[part 4 of 12: package /E40_Platform_System_SystemPackage/Components]
AUTOSAR XML (schema 4-2-1)
package /E40_Platform_System_SystemPackage/Components  (continued)
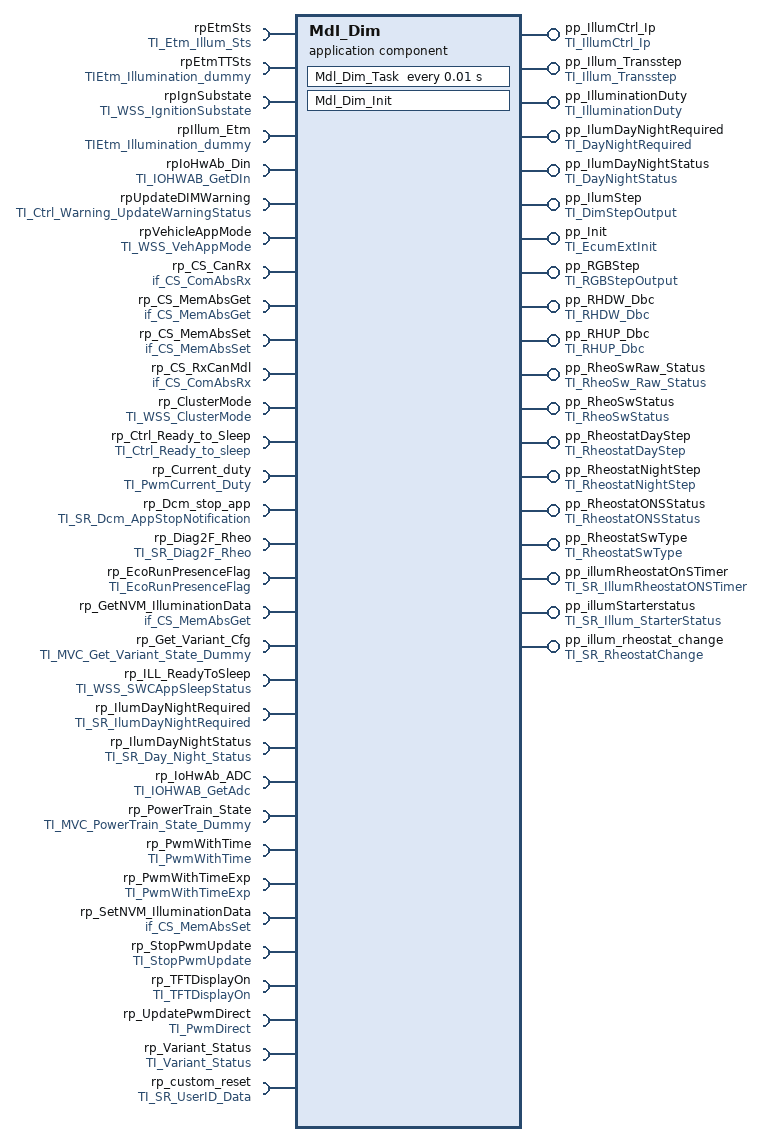
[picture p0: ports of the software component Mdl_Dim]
  application sw component type Mdl_Dim
    19 x provide port:
      pp_IllumCtrl_Ip: nonqueued-sender-com-spec{data-element=IllumCtrl_Ip_Data, init-value=constant-reference=Mdl_DimIllumCtrl_Ip_DataValue0}, provided-interface=TI_IllumCtrl_Ip
      pp_Illum_Transstep: nonqueued-sender-com-spec{data-element=Trans_Stepvlaue, init-value=constant-reference=Mdl_DimTrans_StepvlaueValue0}, provided-interface=TI_Illum_Transstep
      pp_IlluminationDuty: nonqueued-sender-com-spec{data-element=DutyValue, init-value=constant-reference=Mdl_DimDutyValueValue0}, provided-interface=TI_IlluminationDuty
      pp_IlumDayNightRequired: nonqueued-sender-com-spec{data-element=ilumDNRequired, init-value=constant-reference=Mdl_DimilumDNRequiredValue0}, provided-interface=TI_DayNightRequired
      pp_IlumDayNightStatus: nonqueued-sender-com-spec{data-element=illumDNStatus, init-value=constant-reference=Mdl_DimillumDNStatusValue0}, provided-interface=TI_DayNightStatus
      pp_IlumStep: nonqueued-sender-com-spec{data-element=IllumStepValue, init-value=constant-reference=Mdl_DimIllumStepValueValue0}, provided-interface=TI_DimStepOutput
      pp_Init: server-com-spec{operation=TI_EcumExtInit/Init, queue-length=1}, provided-interface=TI_EcumExtInit
      pp_RGBStep: nonqueued-sender-com-spec{data-element=RGBStepValue, init-value=constant-reference=Mdl_DimRGBStepValueValue0}, provided-interface=TI_RGBStepOutput
      pp_RHDW_Dbc: nonqueued-sender-com-spec{data-element=RHDW_Dbc, init-value=constant-reference=Mdl_DimRHDW_DbcValue0}, provided-interface=TI_RHDW_Dbc
      pp_RHUP_Dbc: nonqueued-sender-com-spec{data-element=RHUP_Dbc, init-value=constant-reference=Mdl_DimRHUP_DbcValue0}, provided-interface=TI_RHUP_Dbc
      pp_RheoSwRaw_Status: nonqueued-sender-com-spec{data-element=RawdataStatus, init-value=constant-reference=Mdl_DimRawdataStatusValue0}, provided-interface=TI_RheoSw_Raw_Status
      pp_RheoSwStatus: nonqueued-sender-com-spec{data-element=SwitchStatus, init-value=constant-reference=Mdl_DimSwitchStatusValue0}, provided-interface=TI_RheoSwStatus
      pp_RheostatDayStep: nonqueued-sender-com-spec{data-element=RheostatDayStep, init-value=constant-reference=Mdl_DimRheostatDayStepValue0}, provided-interface=TI_RheostatDayStep
      pp_RheostatNightStep: nonqueued-sender-com-spec{data-element=RheostatNightStep, init-value=constant-reference=Mdl_DimRheostatNightStepValue0}, provided-interface=TI_RheostatNightStep
      pp_RheostatONSStatus: nonqueued-sender-com-spec{data-element=RheostatONSStatus, init-value=constant-reference=Mdl_DimRheostatONSStatusValue0}, provided-interface=TI_RheostatONSStatus
      pp_RheostatSwType: nonqueued-sender-com-spec{data-element=RheostatSwType, init-value=constant-reference=Mdl_DimRheostatSwTypeValue0}, provided-interface=TI_RheostatSwType
      pp_illumRheostatOnSTimer: nonqueued-sender-com-spec{data-element=Rheostat_OnSTime, init-value=constant-reference=Mdl_DimRheostat_OnSTimeValue0}, provided-interface=TI_SR_IllumRheostatONSTimer
      pp_illumStarterstatus: nonqueued-sender-com-spec{data-element=StarterStatus_Out, init-value=constant-reference=Mdl_DimStarterStatus_OutValue0}, provided-interface=TI_SR_Illum_StarterStatus
      pp_illum_rheostat_change: nonqueued-sender-com-spec{data-element=RheoUpdateVal, init-value=constant-reference=Mdl_DimRheoUpdateValValue0}, provided-interface=TI_SR_RheostatChange
    32 x require port:
      rpEtmSts: nonqueued-receiver-com-spec{data-element=Illum_Status, init-value=constant-reference=Mdl_DimIllum_StatusValue0}, required-interface=TI_Etm_Illum_Sts
      rpEtmTTSts: nonqueued-receiver-com-spec{data-element=IllumStatus, init-value=constant-reference=Mdl_DimIllumStatusValue0}, required-interface=TIEtm_Illumination_dummy
      rpIgnSubstate: nonqueued-receiver-com-spec{data-element=IgnitionSubstate, init-value=constant-reference=Mdl_DimIgnitionSubstateValue0}, required-interface=TI_WSS_IgnitionSubstate
      rpIllum_Etm: nonqueued-receiver-com-spec{data-element=IllumStatus, init-value=constant-reference=Mdl_DimIllumStatusValue0}, required-interface=TIEtm_Illumination_dummy
      rpIoHwAb_Din: required-interface=TI_IOHWAB_GetDIn
      rpUpdateDIMWarning: required-interface=TI_Ctrl_Warning_UpdateWarningStatus
      rpVehicleAppMode: nonqueued-receiver-com-spec{data-element=WSSCurrentVehicleState, init-value=constant-reference=Mdl_DimWSSCurrentVehicleStateValue0}, required-interface=TI_WSS_VehAppMode
      rp_CS_CanRx: required-interface=if_CS_ComAbsRx
      rp_CS_MemAbsGet: required-interface=if_CS_MemAbsGet
      rp_CS_MemAbsSet: required-interface=if_CS_MemAbsSet
      rp_CS_RxCanMdl: required-interface=if_CS_ComAbsRx
      rp_ClusterMode: nonqueued-receiver-com-spec{data-element=WSSCurrentClusterMode, init-value=constant-reference=Mdl_DimWSSCurrentClusterModeValue0}, required-interface=TI_WSS_ClusterMode
      rp_Ctrl_Ready_to_Sleep: nonqueued-receiver-com-spec{data-element=Ready_to_Sleep, init-value=constant-reference=Mdl_DimReady_to_SleepValue0}, required-interface=TI_Ctrl_Ready_to_sleep
      rp_Current_duty: required-interface=TI_PwmCurrent_Duty
      rp_Dcm_stop_app: nonqueued-receiver-com-spec{data-element=AppId, init-value=constant-reference=Mdl_DimAppIdValue0}, required-interface=TI_SR_Dcm_AppStopNotification
      rp_Diag2F_Rheo: nonqueued-receiver-com-spec{data-element=Diag_RheoStat, init-value=constant-reference=Mdl_DimDiag_RheoStatValue0}, required-interface=TI_SR_Diag2F_Rheo
      rp_EcoRunPresenceFlag: nonqueued-receiver-com-spec{data-element=EcoRunPresenceFlag, init-value=constant-reference=Mdl_DimEcoRunPresenceFlagValue0}, required-interface=TI_EcoRunPresenceFlag
      rp_GetNVM_IlluminationData: required-interface=if_CS_MemAbsGet
      rp_Get_Variant_Cfg: required-interface=TI_MVC_Get_Variant_State_Dummy
      rp_ILL_ReadyToSleep: required-interface=TI_WSS_SWCAppSleepStatus
      rp_IlumDayNightRequired: nonqueued-receiver-com-spec{data-element=IlumDayNightRequired, init-value=constant-reference=Mdl_DimIlumDayNightRequiredValue0}, required-interface=TI_SR_IlumDayNightRequired
      rp_IlumDayNightStatus: nonqueued-receiver-com-spec{data-element=Day_Night_Status, init-value=constant-reference=Mdl_DimDay_Night_StatusValue0}, required-interface=TI_SR_Day_Night_Status
      rp_IoHwAb_ADC: required-interface=TI_IOHWAB_GetAdc
      rp_PowerTrain_State: nonqueued-receiver-com-spec{data-element=PowerTrain_Flag, init-value=constant-reference=Mdl_DimPowerTrain_FlagValue0}, required-interface=TI_MVC_PowerTrain_State_Dummy
      rp_PwmWithTime: required-interface=TI_PwmWithTime
      rp_PwmWithTimeExp: required-interface=TI_PwmWithTimeExp
      rp_SetNVM_IlluminationData: required-interface=if_CS_MemAbsSet
      rp_StopPwmUpdate: nonqueued-receiver-com-spec{data-element=channel_id, init-value=constant-reference=Mdl_Dimchannel_idValue0}, required-interface=TI_StopPwmUpdate
      rp_TFTDisplayOn: nonqueued-receiver-com-spec{data-element=TFTDisplayOn, init-value=constant-reference=Mdl_DimTFTDisplayOnValue0}, required-interface=TI_TFTDisplayOn
      rp_UpdatePwmDirect: required-interface=TI_PwmDirect
      rp_Variant_Status: required-interface=TI_Variant_Status
      rp_custom_reset: required-interface=TI_SR_UserID_Data
        required-com-specs:
          data-element=CurrentUserID, init-value=constant-reference=Mdl_DimCurrentUserIDValue0
          data-element=CustomizeReset, init-value=constant-reference=Mdl_DimCustomizeResetValue0
          data-element=SettingResetResult, init-value=constant-reference=Mdl_DimSettingResetResultValue0
    behavior IB_Mdl_Dim
      operation invoked event OIE_pp_Init_Mdl_Dim_InitTrigByInit: start-on-event=Mdl_Dim_Init, operation=pp_Init.Init
      timing event TEMdl_Dim_Task: start-on-event=Mdl_Dim_Task, period=0.01
      port-api-options:
        enable-take-address=false, indirect-api=false, port=pp_IllumCtrl_Ip
        enable-take-address=false, indirect-api=false, port=pp_Illum_Transstep
        enable-take-address=false, indirect-api=false, port=pp_IlluminationDuty
        enable-take-address=false, indirect-api=false, port=Mdl_Dim/pp_IlumDayNightRequired
        enable-take-address=false, indirect-api=false, port=Mdl_Dim/pp_IlumDayNightStatus
        enable-take-address=false, indirect-api=false, port=pp_IlumStep
        enable-take-address=false, indirect-api=false, port=Mdl_Dim/pp_Init
        enable-take-address=false, indirect-api=false, port=pp_RGBStep
        enable-take-address=false, indirect-api=false, port=pp_RHDW_Dbc
        enable-take-address=false, indirect-api=false, port=pp_RHUP_Dbc
        enable-take-address=false, indirect-api=false, port=pp_RheoSwRaw_Status
        enable-take-address=false, indirect-api=false, port=pp_RheoSwStatus
        enable-take-address=false, indirect-api=false, port=pp_RheostatDayStep
        enable-take-address=false, indirect-api=false, port=pp_RheostatNightStep
        enable-take-address=false, indirect-api=false, port=pp_RheostatONSStatus
        enable-take-address=false, indirect-api=false, port=pp_RheostatSwType
        enable-take-address=false, indirect-api=false, port=pp_illumRheostatOnSTimer
        enable-take-address=false, indirect-api=false, port=pp_illumStarterstatus
        enable-take-address=false, indirect-api=false, port=pp_illum_rheostat_change
        enable-take-address=false, indirect-api=false, port=Mdl_Dim/rpEtmSts
        enable-take-address=false, indirect-api=false, port=rpEtmTTSts
        enable-take-address=false, indirect-api=false, port=Mdl_Dim/rpIgnSubstate
        enable-take-address=false, indirect-api=false, port=Mdl_Dim/rpIllum_Etm
        enable-take-address=false, indirect-api=false, port=Mdl_Dim/rpIoHwAb_Din
        enable-take-address=false, indirect-api=false, port=rpUpdateDIMWarning
        enable-take-address=false, indirect-api=false, port=Mdl_Dim/rpVehicleAppMode
        enable-take-address=false, indirect-api=false, port=Mdl_Dim/rp_CS_CanRx
        enable-take-address=false, indirect-api=false, port=Mdl_Dim/rp_CS_MemAbsGet
        enable-take-address=false, indirect-api=false, port=Mdl_Dim/rp_CS_MemAbsSet
        enable-take-address=false, indirect-api=false, port=Mdl_Dim/rp_CS_RxCanMdl
        enable-take-address=false, indirect-api=false, port=Mdl_Dim/rp_ClusterMode
        enable-take-address=false, indirect-api=false, port=rp_Ctrl_Ready_to_Sleep
        enable-take-address=false, indirect-api=false, port=rp_Current_duty
        enable-take-address=false, indirect-api=false, port=rp_Dcm_stop_app
        enable-take-address=false, indirect-api=false, port=rp_Diag2F_Rheo
        enable-take-address=false, indirect-api=false, port=rp_EcoRunPresenceFlag
        enable-take-address=false, indirect-api=false, port=rp_GetNVM_IlluminationData
        enable-take-address=false, indirect-api=false, port=Mdl_Dim/rp_Get_Variant_Cfg
        enable-take-address=false, indirect-api=false, port=Mdl_Dim/rp_ILL_ReadyToSleep
        enable-take-address=false, indirect-api=false, port=rp_IlumDayNightRequired
        enable-take-address=false, indirect-api=false, port=Mdl_Dim/rp_IlumDayNightStatus
        enable-take-address=false, indirect-api=false, port=Mdl_Dim/rp_IoHwAb_ADC
        enable-take-address=false, indirect-api=false, port=Mdl_Dim/rp_PowerTrain_State
        enable-take-address=false, indirect-api=false, port=rp_PwmWithTime
        enable-take-address=false, indirect-api=false, port=rp_PwmWithTimeExp
        enable-take-address=false, indirect-api=false, port=rp_SetNVM_IlluminationData
        enable-take-address=false, indirect-api=false, port=rp_StopPwmUpdate
        enable-take-address=false, indirect-api=false, port=Mdl_Dim/rp_TFTDisplayOn
        enable-take-address=false, indirect-api=false, port=rp_UpdatePwmDirect
        enable-take-address=false, indirect-api=false, port=Mdl_Dim/rp_Variant_Status
        enable-take-address=false, indirect-api=false, port=rp_custom_reset
      runnable Mdl_Dim_Init: can-be-invoked-concurrently=true
      runnable Mdl_Dim_Task: can-be-invoked-concurrently=true
        data-receive-point-by-arguments:
          18 x access:
            DRA_rpEtmSts_Illum_Status: accessed-variable=rpEtmSts.Illum_Status
            DRA_rpEtmTTSts_IllumStatus: accessed-variable=rpEtmTTSts.IllumStatus
            DRA_rpIgnSubstate_IgnitionSubstate: accessed-variable=rpIgnSubstate.IgnitionSubstate
            DRA_rpIllum_Etm_IllumStatus: accessed-variable=rpIllum_Etm.IllumStatus
            DRA_rpVehicleAppMode_WSSCurrentVehicleState: accessed-variable=rpVehicleAppMode.WSSCurrentVehicleState
            DRA_rp_ClusterMode_WSSCurrentClusterMode: accessed-variable=rp_ClusterMode.WSSCurrentClusterMode
            DRA_rp_Ctrl_Ready_to_Sleep_Ready_to_Sleep: accessed-variable=rp_Ctrl_Ready_to_Sleep.Ready_to_Sleep
            DRA_rp_Dcm_stop_app_AppId: accessed-variable=rp_Dcm_stop_app.AppId
            DRA_rp_Diag2F_Rheo_Diag_RheoStat: accessed-variable=rp_Diag2F_Rheo.Diag_RheoStat
            DRA_rp_EcoRunPresenceFlag_EcoRunPresenceFlag: accessed-variable=rp_EcoRunPresenceFlag.EcoRunPresenceFlag
            DRA_rp_IlumDayNightRequired_IlumDayNightRequired: accessed-variable=rp_IlumDayNightRequired.IlumDayNightRequired
            DRA_rp_IlumDayNightStatus_Day_Night_Status: accessed-variable=rp_IlumDayNightStatus.Day_Night_Status
            DRA_rp_PowerTrain_State_PowerTrain_Flag: accessed-variable=rp_PowerTrain_State.PowerTrain_Flag
            DRA_rp_StopPwmUpdate_channel_id: accessed-variable=rp_StopPwmUpdate.channel_id
            DRA_rp_TFTDisplayOn_TFTDisplayOn: accessed-variable=rp_TFTDisplayOn.TFTDisplayOn
            DRA_rp_custom_reset_CurrentUserID: accessed-variable=rp_custom_reset.CurrentUserID
            DRA_rp_custom_reset_CustomizeReset: accessed-variable=rp_custom_reset.CustomizeReset
            DRA_rp_custom_reset_SettingResetResult: accessed-variable=rp_custom_reset.SettingResetResult
        data-send-points:
          18 x access:
            DWA_pp_IllumCtrl_Ip_IllumCtrl_Ip_Data: accessed-variable=pp_IllumCtrl_Ip.IllumCtrl_Ip_Data
            DWA_pp_Illum_Transstep_Trans_Stepvlaue: accessed-variable=pp_Illum_Transstep.Trans_Stepvlaue
            DWA_pp_IlluminationDuty_DutyValue: accessed-variable=pp_IlluminationDuty.DutyValue
            DWA_pp_IlumDayNightRequired_ilumDNRequired: accessed-variable=pp_IlumDayNightRequired.ilumDNRequired
            DWA_pp_IlumDayNightStatus_illumDNStatus: accessed-variable=pp_IlumDayNightStatus.illumDNStatus
            DWA_pp_IlumStep_IllumStepValue: accessed-variable=pp_IlumStep.IllumStepValue
            DWA_pp_RGBStep_RGBStepValue: accessed-variable=pp_RGBStep.RGBStepValue
            DWA_pp_RHDW_Dbc_RHDW_Dbc: accessed-variable=pp_RHDW_Dbc.RHDW_Dbc
            DWA_pp_RHUP_Dbc_RHUP_Dbc: accessed-variable=pp_RHUP_Dbc.RHUP_Dbc
            DWA_pp_RheoSwRaw_Status_RawdataStatus: accessed-variable=pp_RheoSwRaw_Status.RawdataStatus
            DWA_pp_RheoSwStatus_SwitchStatus: accessed-variable=pp_RheoSwStatus.SwitchStatus
            DWA_pp_RheostatDayStep_RheostatDayStep: accessed-variable=pp_RheostatDayStep.RheostatDayStep
            DWA_pp_RheostatNightStep_RheostatNightStep: accessed-variable=pp_RheostatNightStep.RheostatNightStep
            DWA_pp_RheostatONSStatus_RheostatONSStatus: accessed-variable=pp_RheostatONSStatus.RheostatONSStatus
            DWA_pp_RheostatSwType_RheostatSwType: accessed-variable=pp_RheostatSwType.RheostatSwType
            DWA_pp_illumRheostatOnSTimer_Rheostat_OnSTime: accessed-variable=pp_illumRheostatOnSTimer.Rheostat_OnSTime
            DWA_pp_illumStarterstatus_StarterStatus_Out: accessed-variable=pp_illumStarterstatus.StarterStatus_Out
            DWA_pp_illum_rheostat_change_RheoUpdateVal: accessed-variable=pp_illum_rheostat_change.RheoUpdateVal
        409 x sync call, all with timeout=0.0:
          OA_rpIoHwAb_Din_GetAsyncRawInput: operation=rpIoHwAb_Din.GetAsyncRawInput
          OA_rpIoHwAb_Din_GetProcessedInput: operation=rpIoHwAb_Din.GetProcessedInput
          OA_rpIoHwAb_Din_GetSyncRawInput: operation=rpIoHwAb_Din.GetSyncRawInput
          OA_rpIoHwAb_Din_GetInputGroup: operation=rpIoHwAb_Din.GetInputGroup
          OA_rpUpdateDIMWarning_UpdateWarningStatus: operation=rpUpdateDIMWarning.UpdateWarningStatus
          OA_rp_CS_CanRx_RxCan_GetSignalValueU8Arr: operation=rp_CS_CanRx.RxCan_GetSignalValueU8Arr
          OA_rp_CS_CanRx_RxCan_SetSignalInitValue: operation=rp_CS_CanRx.RxCan_SetSignalInitValue
          OA_rp_CS_CanRx_RxCan_SetSignalInitValueU8Arr: operation=rp_CS_CanRx.RxCan_SetSignalInitValueU8Arr
          OA_rp_CS_CanRx_RxCan_SignalInvalidProcessingControl: operation=rp_CS_CanRx.RxCan_SignalInvalidProcessingControl
          OA_rp_CS_CanRx_RxCan_SignalMissingProcessingControl: operation=rp_CS_CanRx.RxCan_SignalMissingProcessingControl
          OA_rp_CS_CanRx_RxCan_SignalNRProcessingControl: operation=rp_CS_CanRx.RxCan_SignalNRProcessingControl
          OA_rp_CS_CanRx_RxCan_SignalGetJustRcvdStatus: operation=rp_CS_CanRx.RxCan_SignalGetJustRcvdStatus
          OA_rp_CS_CanRx_RxCan_SignalClearJustRcvdStatus: operation=rp_CS_CanRx.RxCan_SignalClearJustRcvdStatus
          OA_rp_CS_CanRx_RxCan_GetSignalValue: operation=rp_CS_CanRx.RxCan_GetSignalValue
          OA_rp_CS_MemAbsGet_Get_BsShare_SwUpdReflash_Element: operation=rp_CS_MemAbsGet.Get_BsShare_SwUpdReflash_Element
          OA_rp_CS_MemAbsGet_Get_BsShare_SwUpdFotaMode_Element: operation=rp_CS_MemAbsGet.Get_BsShare_SwUpdFotaMode_Element
          OA_rp_CS_MemAbsGet_Get_BsShare_SwUpdFotaFinPrint_Element: operation=rp_CS_MemAbsGet.Get_BsShare_SwUpdFotaFinPrint_Element
          OA_rp_CS_MemAbsGet_Get_BsShare_SwUpdFotaStatus_Element: operation=rp_CS_MemAbsGet.Get_BsShare_SwUpdFotaStatus_Element
          OA_rp_CS_MemAbsGet_Get_BsShare_SwUpdFotadecrypt_Element: operation=rp_CS_MemAbsGet.Get_BsShare_SwUpdFotadecrypt_Element
          OA_rp_CS_MemAbsGet_Get_BsShare_EcuPartNumber_Element: operation=rp_CS_MemAbsGet.Get_BsShare_EcuPartNumber_Element
          OA_rp_CS_MemAbsGet_Get_BsShare_VisteonPartNumber: operation=rp_CS_MemAbsGet.Get_BsShare_VisteonPartNumber
          OA_rp_CS_MemAbsGet_Get_BsShare_VisteonPCBPartNumber: operation=rp_CS_MemAbsGet.Get_BsShare_VisteonPCBPartNumber
          OA_rp_CS_MemAbsGet_Get_BsShare_ProductSerialNumber: operation=rp_CS_MemAbsGet.Get_BsShare_ProductSerialNumber
          OA_rp_CS_MemAbsGet_Get_BsShare_PCBSerialNumber: operation=rp_CS_MemAbsGet.Get_BsShare_PCBSerialNumber
          OA_rp_CS_MemAbsGet_Get_BsShare_SMTManufacturingDate: operation=rp_CS_MemAbsGet.Get_BsShare_SMTManufacturingDate
          OA_rp_CS_MemAbsGet_Get_BsShare_AssemblyManufacturingDate: operation=rp_CS_MemAbsGet.Get_BsShare_AssemblyManufacturingDate
          OA_rp_CS_MemAbsGet_Get_BsShare_SMTPlantNumber: operation=rp_CS_MemAbsGet.Get_BsShare_SMTPlantNumber
          OA_rp_CS_MemAbsGet_Get_BsShare_AssemblyPlantNumber: operation=rp_CS_MemAbsGet.Get_BsShare_AssemblyPlantNumber
          OA_rp_CS_MemAbsGet_Get_BsShare_HWModification: operation=rp_CS_MemAbsGet.Get_BsShare_HWModification
          OA_rp_CS_MemAbsGet_Get_BsShare_VisMeet_Element: operation=rp_CS_MemAbsGet.Get_BsShare_VisMeet_Element
          OA_rp_CS_MemAbsGet_Get_BsShare_VisMeet_EOLEntry_Element: operation=rp_CS_MemAbsGet.Get_BsShare_VisMeet_EOLEntry_Element
          OA_rp_CS_MemAbsGet_Get_BsShare_VehicleConfig_Element: operation=rp_CS_MemAbsGet.Get_BsShare_VehicleConfig_Element
          OA_rp_CS_MemAbsGet_Get_BsConst_SpeedoGauge_Element: operation=rp_CS_MemAbsGet.Get_BsConst_SpeedoGauge_Element
          OA_rp_CS_MemAbsGet_Get_BsConst_TachoGauge_Element: operation=rp_CS_MemAbsGet.Get_BsConst_TachoGauge_Element
          OA_rp_CS_MemAbsGet_Get_BsConst_FuelGauge_Element: operation=rp_CS_MemAbsGet.Get_BsConst_FuelGauge_Element
          OA_rp_CS_MemAbsGet_Get_BsConst_TempGauge_Element: operation=rp_CS_MemAbsGet.Get_BsConst_TempGauge_Element
          OA_rp_CS_MemAbsGet_Get_BsConst_PowerGauge_Element: operation=rp_CS_MemAbsGet.Get_BsConst_PowerGauge_Element
          OA_rp_CS_MemAbsGet_Get_BsConst_OilGauge_Element: operation=rp_CS_MemAbsGet.Get_BsConst_OilGauge_Element
          OA_rp_CS_MemAbsGet_Get_BsConst_TripComputer_Element: operation=rp_CS_MemAbsGet.Get_BsConst_TripComputer_Element
          OA_rp_CS_MemAbsGet_Get_BsConst_Compensation_Line_Slope_m: operation=rp_CS_MemAbsGet.Get_BsConst_Compensation_Line_Slope_m
          OA_rp_CS_MemAbsGet_Get_BsConst_Compensation_Line_Shift_b: operation=rp_CS_MemAbsGet.Get_BsConst_Compensation_Line_Shift_b
          OA_rp_CS_MemAbsGet_Get_BsConst_Lookup_Curve_HotSpot_Coef_X: operation=rp_CS_MemAbsGet.Get_BsConst_Lookup_Curve_HotSpot_Coef_X
          OA_rp_CS_MemAbsGet_Get_BsConst_Lookup_Curve_HotSpot_Coef_Y: operation=rp_CS_MemAbsGet.Get_BsConst_Lookup_Curve_HotSpot_Coef_Y
          OA_rp_CS_MemAbsGet_Get_BsConst_Temp_Threshold_Hysteresis_Derating: operation=rp_CS_MemAbsGet.Get_BsConst_Temp_Threshold_Hysteresis_Derating
          OA_rp_CS_MemAbsGet_Get_BsConst_Derating_Backlight_Disable: operation=rp_CS_MemAbsGet.Get_BsConst_Derating_Backlight_Disable
          OA_rp_CS_MemAbsGet_Get_BsConst_Temperature_Sensor_Conv: operation=rp_CS_MemAbsGet.Get_BsConst_Temperature_Sensor_Conv
          OA_rp_CS_MemAbsGet_Get_BsConst_PCB_Temperature_Sensor_Conv: operation=rp_CS_MemAbsGet.Get_BsConst_PCB_Temperature_Sensor_Conv
          OA_rp_CS_MemAbsGet_Get_BsConst_Display_Illum_Max_Level: operation=rp_CS_MemAbsGet.Get_BsConst_Display_Illum_Max_Level
          OA_rp_CS_MemAbsGet_Get_BsConst_PWM_boost_bypass_duty: operation=rp_CS_MemAbsGet.Get_BsConst_PWM_boost_bypass_duty
          OA_rp_CS_MemAbsGet_Get_BsConst_BsConst_Illumination_ReservedByte: operation=rp_CS_MemAbsGet.Get_BsConst_BsConst_Illumination_ReservedByte
          OA_rp_CS_MemAbsGet_Get_BsConst_Compensation_Line_Slope_m_SafeCopy1: operation=rp_CS_MemAbsGet.Get_BsConst_Compensation_Line_Slope_m_SafeCopy1
          OA_rp_CS_MemAbsGet_Get_BsConst_Compensation_Line_Shift_b_SafeCopy1: operation=rp_CS_MemAbsGet.Get_BsConst_Compensation_Line_Shift_b_SafeCopy1
          OA_rp_CS_MemAbsGet_Get_BsConst_Lookup_Curve_HotSpot_Coef_X_SafeCopy1: operation=rp_CS_MemAbsGet.Get_BsConst_Lookup_Curve_HotSpot_Coef_X_SafeCopy1
          OA_rp_CS_MemAbsGet_Get_BsConst_Lookup_Curve_HotSpot_Coef_Y_SafeCopy1: operation=rp_CS_MemAbsGet.Get_BsConst_Lookup_Curve_HotSpot_Coef_Y_SafeCopy1
          OA_rp_CS_MemAbsGet_Get_BsConst_Temp_Threshold_Hysteresis_Derating_SafeCopy1: operation=rp_CS_MemAbsGet.Get_BsConst_Temp_Threshold_Hysteresis_Derating_SafeCopy1
          OA_rp_CS_MemAbsGet_Get_BsConst_Derating_Backlight_Disable_SafeCopy1: operation=rp_CS_MemAbsGet.Get_BsConst_Derating_Backlight_Disable_SafeCopy1
          OA_rp_CS_MemAbsGet_Get_BsConst_Temperature_Sensor_Conv_SafeCopy1: operation=rp_CS_MemAbsGet.Get_BsConst_Temperature_Sensor_Conv_SafeCopy1
          OA_rp_CS_MemAbsGet_Get_BsConst_PCB_Temperature_Sensor_Conv_SafeCopy1: operation=rp_CS_MemAbsGet.Get_BsConst_PCB_Temperature_Sensor_Conv_SafeCopy1
          OA_rp_CS_MemAbsGet_Get_BsConst_Display_Illum_Max_Level_SafeCopy1: operation=rp_CS_MemAbsGet.Get_BsConst_Display_Illum_Max_Level_SafeCopy1
          OA_rp_CS_MemAbsGet_Get_BsConst_PWM_boost_bypass_duty_SafeCopy1: operation=rp_CS_MemAbsGet.Get_BsConst_PWM_boost_bypass_duty_SafeCopy1
          OA_rp_CS_MemAbsGet_Get_BsConst_BsConst_Illumination_ReservedByte_SafeCopy1: operation=rp_CS_MemAbsGet.Get_BsConst_BsConst_Illumination_ReservedByte_SafeCopy1
          OA_rp_CS_MemAbsGet_Get_BsConst_Compensation_Line_Slope_m_SafeCopy2: operation=rp_CS_MemAbsGet.Get_BsConst_Compensation_Line_Slope_m_SafeCopy2
          OA_rp_CS_MemAbsGet_Get_BsConst_Compensation_Line_Shift_b_SafeCopy2: operation=rp_CS_MemAbsGet.Get_BsConst_Compensation_Line_Shift_b_SafeCopy2
          OA_rp_CS_MemAbsGet_Get_BsConst_Lookup_Curve_HotSpot_Coef_X_SafeCopy2: operation=rp_CS_MemAbsGet.Get_BsConst_Lookup_Curve_HotSpot_Coef_X_SafeCopy2
          OA_rp_CS_MemAbsGet_Get_BsConst_Lookup_Curve_HotSpot_Coef_Y_SafeCopy2: operation=rp_CS_MemAbsGet.Get_BsConst_Lookup_Curve_HotSpot_Coef_Y_SafeCopy2
          OA_rp_CS_MemAbsGet_Get_BsConst_Temp_Threshold_Hysteresis_Derating_SafeCopy2: operation=rp_CS_MemAbsGet.Get_BsConst_Temp_Threshold_Hysteresis_Derating_SafeCopy2
          OA_rp_CS_MemAbsGet_Get_BsConst_Derating_Backlight_Disable_SafeCopy2: operation=rp_CS_MemAbsGet.Get_BsConst_Derating_Backlight_Disable_SafeCopy2
          OA_rp_CS_MemAbsGet_Get_BsConst_Temperature_Sensor_Conv_SafeCopy2: operation=rp_CS_MemAbsGet.Get_BsConst_Temperature_Sensor_Conv_SafeCopy2
          OA_rp_CS_MemAbsGet_Get_BsConst_PCB_Temperature_Sensor_Conv_SafeCopy2: operation=rp_CS_MemAbsGet.Get_BsConst_PCB_Temperature_Sensor_Conv_SafeCopy2
          OA_rp_CS_MemAbsGet_Get_BsConst_Display_Illum_Max_Level_SafeCopy2: operation=rp_CS_MemAbsGet.Get_BsConst_Display_Illum_Max_Level_SafeCopy2
          OA_rp_CS_MemAbsGet_Get_BsConst_PWM_boost_bypass_duty_SafeCopy2: operation=rp_CS_MemAbsGet.Get_BsConst_PWM_boost_bypass_duty_SafeCopy2
          OA_rp_CS_MemAbsGet_Get_BsConst_BsConst_Illumination_ReservedByte_SafeCopy2: operation=rp_CS_MemAbsGet.Get_BsConst_BsConst_Illumination_ReservedByte_SafeCopy2
          OA_rp_CS_MemAbsGet_Get_BsConst_Audio_Element: operation=rp_CS_MemAbsGet.Get_BsConst_Audio_Element
          OA_rp_CS_MemAbsGet_Get_BsConst_Warning_Element: operation=rp_CS_MemAbsGet.Get_BsConst_Warning_Element
          OA_rp_CS_MemAbsGet_Get_BsConst_RealTimeClock_Element: operation=rp_CS_MemAbsGet.Get_BsConst_RealTimeClock_Element
          OA_rp_CS_MemAbsGet_Get_BsConst_Communication_Element: operation=rp_CS_MemAbsGet.Get_BsConst_Communication_Element
          OA_rp_CS_MemAbsGet_Get_BsConst_Power_Element: operation=rp_CS_MemAbsGet.Get_BsConst_Power_Element
          OA_rp_CS_MemAbsGet_Get_BsConst_ServiceReminder_Element: operation=rp_CS_MemAbsGet.Get_BsConst_ServiceReminder_Element
          OA_rp_CS_MemAbsGet_Get_BsConst_EngOffTimer_Element: operation=rp_CS_MemAbsGet.Get_BsConst_EngOffTimer_Element
          OA_rp_CS_MemAbsGet_Get_BsCys_Certicificate_Element: operation=rp_CS_MemAbsGet.Get_BsCys_Certicificate_Element
          OA_rp_CS_MemAbsGet_Get_RefCys_Certicificate_Element: operation=rp_CS_MemAbsGet.Get_RefCys_Certicificate_Element
          OA_rp_CS_MemAbsGet_Get_RefCys_Certicificate1_Element: operation=rp_CS_MemAbsGet.Get_RefCys_Certicificate1_Element
          OA_rp_CS_MemAbsGet_Get_BsRt_Odometer_Element: operation=rp_CS_MemAbsGet.Get_BsRt_Odometer_Element
          OA_rp_CS_MemAbsGet_Get_BsRt_SpeedoGauge_Element: operation=rp_CS_MemAbsGet.Get_BsRt_SpeedoGauge_Element
          OA_rp_CS_MemAbsGet_Get_BsRt_TachoGauge_Element: operation=rp_CS_MemAbsGet.Get_BsRt_TachoGauge_Element
          OA_rp_CS_MemAbsGet_Get_BsRt_FuelGauge_Element: operation=rp_CS_MemAbsGet.Get_BsRt_FuelGauge_Element
          OA_rp_CS_MemAbsGet_Get_BsRt_TempGauge_Element: operation=rp_CS_MemAbsGet.Get_BsRt_TempGauge_Element
          OA_rp_CS_MemAbsGet_Get_BsRt_PowerGauge_Element: operation=rp_CS_MemAbsGet.Get_BsRt_PowerGauge_Element
          OA_rp_CS_MemAbsGet_Get_BsRt_OilGauge_Element: operation=rp_CS_MemAbsGet.Get_BsRt_OilGauge_Element
          OA_rp_CS_MemAbsGet_Get_BsRt_TripComputer_Element: operation=rp_CS_MemAbsGet.Get_BsRt_TripComputer_Element
          OA_rp_CS_MemAbsGet_Get_BsRt_Warning_Element: operation=rp_CS_MemAbsGet.Get_BsRt_Warning_Element
          OA_rp_CS_MemAbsGet_Get_BsRt_RealTimeClock_Element: operation=rp_CS_MemAbsGet.Get_BsRt_RealTimeClock_Element
          OA_rp_CS_MemAbsGet_Get_BsRt_Personalization_Element: operation=rp_CS_MemAbsGet.Get_BsRt_Personalization_Element
          OA_rp_CS_MemAbsGet_Get_BsRt_Illumination_Element: operation=rp_CS_MemAbsGet.Get_BsRt_Illumination_Element
          OA_rp_CS_MemAbsGet_Get_BsRt_CusDlt_Element: operation=rp_CS_MemAbsGet.Get_BsRt_CusDlt_Element
          OA_rp_CS_MemAbsGet_Get_BsReten_Odometer_Element: operation=rp_CS_MemAbsGet.Get_BsReten_Odometer_Element
          OA_rp_CS_MemAbsGet_Get_BsReten_Gauges_Element: operation=rp_CS_MemAbsGet.Get_BsReten_Gauges_Element
          OA_rp_CS_MemAbsGet_Get_BsReten_Tripcomputer_Element: operation=rp_CS_MemAbsGet.Get_BsReten_Tripcomputer_Element
          OA_rp_CS_MemAbsGet_Get_BsReten_Illumination_Element: operation=rp_CS_MemAbsGet.Get_BsReten_Illumination_Element
          OA_rp_CS_MemAbsGet_Get_BsReten_Audio_Element: operation=rp_CS_MemAbsGet.Get_BsReten_Audio_Element
          OA_rp_CS_MemAbsGet_Get_BsReten_Warning_Element: operation=rp_CS_MemAbsGet.Get_BsReten_Warning_Element
          OA_rp_CS_MemAbsGet_Get_BsReten_RealTimeClock_Element: operation=rp_CS_MemAbsGet.Get_BsReten_RealTimeClock_Element
          OA_rp_CS_MemAbsGet_Get_BsReten_Communication_Element: operation=rp_CS_MemAbsGet.Get_BsReten_Communication_Element
          OA_rp_CS_MemAbsGet_Get_BsReten_Personalization_Element: operation=rp_CS_MemAbsGet.Get_BsReten_Personalization_Element
          OA_rp_CS_MemAbsGet_Get_BsReten_Power_Element: operation=rp_CS_MemAbsGet.Get_BsReten_Power_Element
          OA_rp_CS_MemAbsGet_Get_BsReten_Display_Element: operation=rp_CS_MemAbsGet.Get_BsReten_Display_Element
          OA_rp_CS_MemAbsGet_Get_BsDiag_ErrorRecord_Element: operation=rp_CS_MemAbsGet.Get_BsDiag_ErrorRecord_Element
          OA_rp_CS_MemAbsGet_Get_BsDiag_Dtc_Element: operation=rp_CS_MemAbsGet.Get_BsDiag_Dtc_Element
          OA_rp_CS_MemAbsSet_Set_BsShare_SwUpdReflash_Element: operation=rp_CS_MemAbsSet.Set_BsShare_SwUpdReflash_Element
          OA_rp_CS_MemAbsSet_Set_BsShare_SwUpdFotaMode_Element: operation=rp_CS_MemAbsSet.Set_BsShare_SwUpdFotaMode_Element
          OA_rp_CS_MemAbsSet_Set_BsShare_SwUpdFotaFinPrint_Element: operation=rp_CS_MemAbsSet.Set_BsShare_SwUpdFotaFinPrint_Element
          OA_rp_CS_MemAbsSet_Set_BsShare_SwUpdFotaStatus_Element: operation=rp_CS_MemAbsSet.Set_BsShare_SwUpdFotaStatus_Element
          OA_rp_CS_MemAbsSet_Set_BsShare_SwUpdFotadecrypt_Element: operation=rp_CS_MemAbsSet.Set_BsShare_SwUpdFotadecrypt_Element
          OA_rp_CS_MemAbsSet_Set_BsShare_EcuPartNumber_Element: operation=rp_CS_MemAbsSet.Set_BsShare_EcuPartNumber_Element
          OA_rp_CS_MemAbsSet_Set_BsShare_VisteonPartNumber: operation=rp_CS_MemAbsSet.Set_BsShare_VisteonPartNumber
          OA_rp_CS_MemAbsSet_Set_BsShare_VisteonPCBPartNumber: operation=rp_CS_MemAbsSet.Set_BsShare_VisteonPCBPartNumber
          OA_rp_CS_MemAbsSet_Set_BsShare_ProductSerialNumber: operation=rp_CS_MemAbsSet.Set_BsShare_ProductSerialNumber
          OA_rp_CS_MemAbsSet_Set_BsShare_PCBSerialNumber: operation=rp_CS_MemAbsSet.Set_BsShare_PCBSerialNumber
          OA_rp_CS_MemAbsSet_Set_BsShare_SMTManufacturingDate: operation=rp_CS_MemAbsSet.Set_BsShare_SMTManufacturingDate
          OA_rp_CS_MemAbsSet_Set_BsShare_AssemblyManufacturingDate: operation=rp_CS_MemAbsSet.Set_BsShare_AssemblyManufacturingDate
          OA_rp_CS_MemAbsSet_Set_BsShare_SMTPlantNumber: operation=rp_CS_MemAbsSet.Set_BsShare_SMTPlantNumber
          OA_rp_CS_MemAbsSet_Set_BsShare_AssemblyPlantNumber: operation=rp_CS_MemAbsSet.Set_BsShare_AssemblyPlantNumber
          OA_rp_CS_MemAbsSet_Set_BsShare_HWModification: operation=rp_CS_MemAbsSet.Set_BsShare_HWModification
          OA_rp_CS_MemAbsSet_Set_BsShare_VisMeet_Element: operation=rp_CS_MemAbsSet.Set_BsShare_VisMeet_Element
          OA_rp_CS_MemAbsSet_Set_BsShare_VisMeet_EOLEntry_Element: operation=rp_CS_MemAbsSet.Set_BsShare_VisMeet_EOLEntry_Element
          OA_rp_CS_MemAbsSet_Set_BsShare_VehicleConfig_Element: operation=rp_CS_MemAbsSet.Set_BsShare_VehicleConfig_Element
          OA_rp_CS_MemAbsSet_Set_BsConst_SpeedoGauge_Element: operation=rp_CS_MemAbsSet.Set_BsConst_SpeedoGauge_Element
          OA_rp_CS_MemAbsSet_Set_BsConst_TachoGauge_Element: operation=rp_CS_MemAbsSet.Set_BsConst_TachoGauge_Element
          OA_rp_CS_MemAbsSet_Set_BsConst_FuelGauge_Element: operation=rp_CS_MemAbsSet.Set_BsConst_FuelGauge_Element
          OA_rp_CS_MemAbsSet_Set_BsConst_TempGauge_Element: operation=rp_CS_MemAbsSet.Set_BsConst_TempGauge_Element
          OA_rp_CS_MemAbsSet_Set_BsConst_PowerGauge_Element: operation=rp_CS_MemAbsSet.Set_BsConst_PowerGauge_Element
          OA_rp_CS_MemAbsSet_Set_BsConst_OilGauge_Element: operation=rp_CS_MemAbsSet.Set_BsConst_OilGauge_Element
          OA_rp_CS_MemAbsSet_Set_BsConst_TripComputer_Element: operation=rp_CS_MemAbsSet.Set_BsConst_TripComputer_Element
          OA_rp_CS_MemAbsSet_Set_BsConst_Compensation_Line_Slope_m: operation=rp_CS_MemAbsSet.Set_BsConst_Compensation_Line_Slope_m
          OA_rp_CS_MemAbsSet_Set_BsConst_Compensation_Line_Shift_b: operation=rp_CS_MemAbsSet.Set_BsConst_Compensation_Line_Shift_b
          OA_rp_CS_MemAbsSet_Set_BsConst_Lookup_Curve_HotSpot_Coef_X: operation=rp_CS_MemAbsSet.Set_BsConst_Lookup_Curve_HotSpot_Coef_X
          OA_rp_CS_MemAbsSet_Set_BsConst_Lookup_Curve_HotSpot_Coef_Y: operation=rp_CS_MemAbsSet.Set_BsConst_Lookup_Curve_HotSpot_Coef_Y
          OA_rp_CS_MemAbsSet_Set_BsConst_Temp_Threshold_Hysteresis_Derating: operation=rp_CS_MemAbsSet.Set_BsConst_Temp_Threshold_Hysteresis_Derating
          OA_rp_CS_MemAbsSet_Set_BsConst_Derating_Backlight_Disable: operation=rp_CS_MemAbsSet.Set_BsConst_Derating_Backlight_Disable
          OA_rp_CS_MemAbsSet_Set_BsConst_Temperature_Sensor_Conv: operation=rp_CS_MemAbsSet.Set_BsConst_Temperature_Sensor_Conv
          OA_rp_CS_MemAbsSet_Set_BsConst_PCB_Temperature_Sensor_Conv: operation=rp_CS_MemAbsSet.Set_BsConst_PCB_Temperature_Sensor_Conv
          OA_rp_CS_MemAbsSet_Set_BsConst_Display_Illum_Max_Level: operation=rp_CS_MemAbsSet.Set_BsConst_Display_Illum_Max_Level
          OA_rp_CS_MemAbsSet_Set_BsConst_PWM_boost_bypass_duty: operation=rp_CS_MemAbsSet.Set_BsConst_PWM_boost_bypass_duty
          OA_rp_CS_MemAbsSet_Set_BsConst_BsConst_Illumination_ReservedByte: operation=rp_CS_MemAbsSet.Set_BsConst_BsConst_Illumination_ReservedByte
          OA_rp_CS_MemAbsSet_Set_BsConst_Compensation_Line_Slope_m_SafeCopy1: operation=rp_CS_MemAbsSet.Set_BsConst_Compensation_Line_Slope_m_SafeCopy1
          OA_rp_CS_MemAbsSet_Set_BsConst_Compensation_Line_Shift_b_SafeCopy1: operation=rp_CS_MemAbsSet.Set_BsConst_Compensation_Line_Shift_b_SafeCopy1
          OA_rp_CS_MemAbsSet_Set_BsConst_Lookup_Curve_HotSpot_Coef_X_SafeCopy1: operation=rp_CS_MemAbsSet.Set_BsConst_Lookup_Curve_HotSpot_Coef_X_SafeCopy1
          OA_rp_CS_MemAbsSet_Set_BsConst_Lookup_Curve_HotSpot_Coef_Y_SafeCopy1: operation=rp_CS_MemAbsSet.Set_BsConst_Lookup_Curve_HotSpot_Coef_Y_SafeCopy1
          OA_rp_CS_MemAbsSet_Set_BsConst_Temp_Threshold_Hysteresis_Derating_SafeCopy1: operation=rp_CS_MemAbsSet.Set_BsConst_Temp_Threshold_Hysteresis_Derating_SafeCopy1
          OA_rp_CS_MemAbsSet_Set_BsConst_Derating_Backlight_Disable_SafeCopy1: operation=rp_CS_MemAbsSet.Set_BsConst_Derating_Backlight_Disable_SafeCopy1
          OA_rp_CS_MemAbsSet_Set_BsConst_Temperature_Sensor_Conv_SafeCopy1: operation=rp_CS_MemAbsSet.Set_BsConst_Temperature_Sensor_Conv_SafeCopy1
          OA_rp_CS_MemAbsSet_Set_BsConst_PCB_Temperature_Sensor_Conv_SafeCopy1: operation=rp_CS_MemAbsSet.Set_BsConst_PCB_Temperature_Sensor_Conv_SafeCopy1
          OA_rp_CS_MemAbsSet_Set_BsConst_Display_Illum_Max_Level_SafeCopy1: operation=rp_CS_MemAbsSet.Set_BsConst_Display_Illum_Max_Level_SafeCopy1
          OA_rp_CS_MemAbsSet_Set_BsConst_PWM_boost_bypass_duty_SafeCopy1: operation=rp_CS_MemAbsSet.Set_BsConst_PWM_boost_bypass_duty_SafeCopy1
          OA_rp_CS_MemAbsSet_Set_BsConst_BsConst_Illumination_ReservedByte_SafeCopy1: operation=rp_CS_MemAbsSet.Set_BsConst_BsConst_Illumination_ReservedByte_SafeCopy1
          OA_rp_CS_MemAbsSet_Set_BsConst_Compensation_Line_Slope_m_SafeCopy2: operation=rp_CS_MemAbsSet.Set_BsConst_Compensation_Line_Slope_m_SafeCopy2
          OA_rp_CS_MemAbsSet_Set_BsConst_Compensation_Line_Shift_b_SafeCopy2: operation=rp_CS_MemAbsSet.Set_BsConst_Compensation_Line_Shift_b_SafeCopy2
          OA_rp_CS_MemAbsSet_Set_BsConst_Lookup_Curve_HotSpot_Coef_X_SafeCopy2: operation=rp_CS_MemAbsSet.Set_BsConst_Lookup_Curve_HotSpot_Coef_X_SafeCopy2
          OA_rp_CS_MemAbsSet_Set_BsConst_Lookup_Curve_HotSpot_Coef_Y_SafeCopy2: operation=rp_CS_MemAbsSet.Set_BsConst_Lookup_Curve_HotSpot_Coef_Y_SafeCopy2
          OA_rp_CS_MemAbsSet_Set_BsConst_Temp_Threshold_Hysteresis_Derating_SafeCopy2: operation=rp_CS_MemAbsSet.Set_BsConst_Temp_Threshold_Hysteresis_Derating_SafeCopy2
          OA_rp_CS_MemAbsSet_Set_BsConst_Derating_Backlight_Disable_SafeCopy2: operation=rp_CS_MemAbsSet.Set_BsConst_Derating_Backlight_Disable_SafeCopy2
          OA_rp_CS_MemAbsSet_Set_BsConst_Temperature_Sensor_Conv_SafeCopy2: operation=rp_CS_MemAbsSet.Set_BsConst_Temperature_Sensor_Conv_SafeCopy2
          OA_rp_CS_MemAbsSet_Set_BsConst_PCB_Temperature_Sensor_Conv_SafeCopy2: operation=rp_CS_MemAbsSet.Set_BsConst_PCB_Temperature_Sensor_Conv_SafeCopy2
          OA_rp_CS_MemAbsSet_Set_BsConst_Display_Illum_Max_Level_SafeCopy2: operation=rp_CS_MemAbsSet.Set_BsConst_Display_Illum_Max_Level_SafeCopy2
          OA_rp_CS_MemAbsSet_Set_BsConst_PWM_boost_bypass_duty_SafeCopy2: operation=rp_CS_MemAbsSet.Set_BsConst_PWM_boost_bypass_duty_SafeCopy2
          OA_rp_CS_MemAbsSet_Set_BsConst_BsConst_Illumination_ReservedByte_SafeCopy2: operation=rp_CS_MemAbsSet.Set_BsConst_BsConst_Illumination_ReservedByte_SafeCopy2
          OA_rp_CS_MemAbsSet_Set_BsConst_Audio_Element: operation=rp_CS_MemAbsSet.Set_BsConst_Audio_Element
          OA_rp_CS_MemAbsSet_Set_BsConst_Warning_Element: operation=rp_CS_MemAbsSet.Set_BsConst_Warning_Element
          OA_rp_CS_MemAbsSet_Set_BsConst_RealTimeClock_Element: operation=rp_CS_MemAbsSet.Set_BsConst_RealTimeClock_Element
          OA_rp_CS_MemAbsSet_Set_BsConst_Communication_Element: operation=rp_CS_MemAbsSet.Set_BsConst_Communication_Element
          OA_rp_CS_MemAbsSet_Set_BsConst_Power_Element: operation=rp_CS_MemAbsSet.Set_BsConst_Power_Element
          OA_rp_CS_MemAbsSet_Set_BsConst_ServiceReminder_Element: operation=rp_CS_MemAbsSet.Set_BsConst_ServiceReminder_Element
          OA_rp_CS_MemAbsSet_Set_BsConst_EngOffTimer_Element: operation=rp_CS_MemAbsSet.Set_BsConst_EngOffTimer_Element
          OA_rp_CS_MemAbsSet_Set_BsCys_Certicificate_Element: operation=rp_CS_MemAbsSet.Set_BsCys_Certicificate_Element
          OA_rp_CS_MemAbsSet_Set_RefCys_Certicificate_Element: operation=rp_CS_MemAbsSet.Set_RefCys_Certicificate_Element
          OA_rp_CS_MemAbsSet_Set_RefCys_Certicificate1_Element: operation=rp_CS_MemAbsSet.Set_RefCys_Certicificate1_Element
          OA_rp_CS_MemAbsSet_Set_BsRt_Odometer_Element: operation=rp_CS_MemAbsSet.Set_BsRt_Odometer_Element
          OA_rp_CS_MemAbsSet_Set_BsRt_SpeedoGauge_Element: operation=rp_CS_MemAbsSet.Set_BsRt_SpeedoGauge_Element
          OA_rp_CS_MemAbsSet_Set_BsRt_TachoGauge_Element: operation=rp_CS_MemAbsSet.Set_BsRt_TachoGauge_Element
          OA_rp_CS_MemAbsSet_Set_BsRt_FuelGauge_Element: operation=rp_CS_MemAbsSet.Set_BsRt_FuelGauge_Element
          OA_rp_CS_MemAbsSet_Set_BsRt_TempGauge_Element: operation=rp_CS_MemAbsSet.Set_BsRt_TempGauge_Element
          OA_rp_CS_MemAbsSet_Set_BsRt_PowerGauge_Element: operation=rp_CS_MemAbsSet.Set_BsRt_PowerGauge_Element
          OA_rp_CS_MemAbsSet_Set_BsRt_OilGauge_Element: operation=rp_CS_MemAbsSet.Set_BsRt_OilGauge_Element
          OA_rp_CS_MemAbsSet_Set_BsRt_TripComputer_Element: operation=rp_CS_MemAbsSet.Set_BsRt_TripComputer_Element
          OA_rp_CS_MemAbsSet_Set_BsRt_Warning_Element: operation=rp_CS_MemAbsSet.Set_BsRt_Warning_Element
          OA_rp_CS_MemAbsSet_Set_BsRt_RealTimeClock_Element: operation=rp_CS_MemAbsSet.Set_BsRt_RealTimeClock_Element
          OA_rp_CS_MemAbsSet_Set_BsRt_Personalization_Element: operation=rp_CS_MemAbsSet.Set_BsRt_Personalization_Element
          OA_rp_CS_MemAbsSet_Set_BsRt_Illumination_Element: operation=rp_CS_MemAbsSet.Set_BsRt_Illumination_Element
          OA_rp_CS_MemAbsSet_Set_BsRt_CusDlt_Element: operation=rp_CS_MemAbsSet.Set_BsRt_CusDlt_Element
          OA_rp_CS_MemAbsSet_Set_BsReten_Odometer_Element: operation=rp_CS_MemAbsSet.Set_BsReten_Odometer_Element
          OA_rp_CS_MemAbsSet_Set_BsReten_Gauges_Element: operation=rp_CS_MemAbsSet.Set_BsReten_Gauges_Element
          OA_rp_CS_MemAbsSet_Set_BsReten_Tripcomputer_Element: operation=rp_CS_MemAbsSet.Set_BsReten_Tripcomputer_Element
          OA_rp_CS_MemAbsSet_Set_BsReten_Illumination_Element: operation=rp_CS_MemAbsSet.Set_BsReten_Illumination_Element
          OA_rp_CS_MemAbsSet_Set_BsReten_Audio_Element: operation=rp_CS_MemAbsSet.Set_BsReten_Audio_Element
          OA_rp_CS_MemAbsSet_Set_BsReten_Warning_Element: operation=rp_CS_MemAbsSet.Set_BsReten_Warning_Element
          OA_rp_CS_MemAbsSet_Set_BsReten_RealTimeClock_Element: operation=rp_CS_MemAbsSet.Set_BsReten_RealTimeClock_Element
          OA_rp_CS_MemAbsSet_Set_BsReten_Communication_Element: operation=rp_CS_MemAbsSet.Set_BsReten_Communication_Element
          OA_rp_CS_MemAbsSet_Set_BsReten_Personalization_Element: operation=rp_CS_MemAbsSet.Set_BsReten_Personalization_Element
          OA_rp_CS_MemAbsSet_Set_BsReten_Power_Element: operation=rp_CS_MemAbsSet.Set_BsReten_Power_Element
          OA_rp_CS_MemAbsSet_Set_BsReten_Display_Element: operation=rp_CS_MemAbsSet.Set_BsReten_Display_Element
          OA_rp_CS_MemAbsSet_Set_BsDiag_ErrorRecord_Element: operation=rp_CS_MemAbsSet.Set_BsDiag_ErrorRecord_Element
          OA_rp_CS_MemAbsSet_Set_BsDiag_Dtc_Element: operation=rp_CS_MemAbsSet.Set_BsDiag_Dtc_Element
          OA_rp_CS_RxCanMdl_RxCan_GetSignalValueU8Arr: operation=rp_CS_RxCanMdl.RxCan_GetSignalValueU8Arr
          OA_rp_CS_RxCanMdl_RxCan_SetSignalInitValue: operation=rp_CS_RxCanMdl.RxCan_SetSignalInitValue
          OA_rp_CS_RxCanMdl_RxCan_SetSignalInitValueU8Arr: operation=rp_CS_RxCanMdl.RxCan_SetSignalInitValueU8Arr
          OA_rp_CS_RxCanMdl_RxCan_SignalInvalidProcessingControl: operation=rp_CS_RxCanMdl.RxCan_SignalInvalidProcessingControl
          OA_rp_CS_RxCanMdl_RxCan_SignalMissingProcessingControl: operation=rp_CS_RxCanMdl.RxCan_SignalMissingProcessingControl
          OA_rp_CS_RxCanMdl_RxCan_SignalNRProcessingControl: operation=rp_CS_RxCanMdl.RxCan_SignalNRProcessingControl
          OA_rp_CS_RxCanMdl_RxCan_SignalGetJustRcvdStatus: operation=rp_CS_RxCanMdl.RxCan_SignalGetJustRcvdStatus
          OA_rp_CS_RxCanMdl_RxCan_SignalClearJustRcvdStatus: operation=rp_CS_RxCanMdl.RxCan_SignalClearJustRcvdStatus
          OA_rp_CS_RxCanMdl_RxCan_GetSignalValue: operation=rp_CS_RxCanMdl.RxCan_GetSignalValue
          OA_rp_Current_duty_GetPwmCurrentDuty: operation=rp_Current_duty.GetPwmCurrentDuty
          OA_rp_GetNVM_IlluminationData_Get_BsShare_SwUpdReflash_Element: operation=rp_GetNVM_IlluminationData.Get_BsShare_SwUpdReflash_Element
          OA_rp_GetNVM_IlluminationData_Get_BsShare_SwUpdFotaMode_Element: operation=rp_GetNVM_IlluminationData.Get_BsShare_SwUpdFotaMode_Element
          OA_rp_GetNVM_IlluminationData_Get_BsShare_SwUpdFotaFinPrint_Element: operation=rp_GetNVM_IlluminationData.Get_BsShare_SwUpdFotaFinPrint_Element
          OA_rp_GetNVM_IlluminationData_Get_BsShare_SwUpdFotaStatus_Element: operation=rp_GetNVM_IlluminationData.Get_BsShare_SwUpdFotaStatus_Element
          OA_rp_GetNVM_IlluminationData_Get_BsShare_SwUpdFotadecrypt_Element: operation=rp_GetNVM_IlluminationData.Get_BsShare_SwUpdFotadecrypt_Element
          OA_rp_GetNVM_IlluminationData_Get_BsShare_EcuPartNumber_Element: operation=rp_GetNVM_IlluminationData.Get_BsShare_EcuPartNumber_Element
          OA_rp_GetNVM_IlluminationData_Get_BsShare_VisteonPartNumber: operation=rp_GetNVM_IlluminationData.Get_BsShare_VisteonPartNumber
          OA_rp_GetNVM_IlluminationData_Get_BsShare_VisteonPCBPartNumber: operation=rp_GetNVM_IlluminationData.Get_BsShare_VisteonPCBPartNumber
          OA_rp_GetNVM_IlluminationData_Get_BsShare_ProductSerialNumber: operation=rp_GetNVM_IlluminationData.Get_BsShare_ProductSerialNumber
          OA_rp_GetNVM_IlluminationData_Get_BsShare_PCBSerialNumber: operation=rp_GetNVM_IlluminationData.Get_BsShare_PCBSerialNumber
          OA_rp_GetNVM_IlluminationData_Get_BsShare_SMTManufacturingDate: operation=rp_GetNVM_IlluminationData.Get_BsShare_SMTManufacturingDate
          OA_rp_GetNVM_IlluminationData_Get_BsShare_AssemblyManufacturingDate: operation=rp_GetNVM_IlluminationData.Get_BsShare_AssemblyManufacturingDate
          OA_rp_GetNVM_IlluminationData_Get_BsShare_SMTPlantNumber: operation=rp_GetNVM_IlluminationData.Get_BsShare_SMTPlantNumber
          OA_rp_GetNVM_IlluminationData_Get_BsShare_AssemblyPlantNumber: operation=rp_GetNVM_IlluminationData.Get_BsShare_AssemblyPlantNumber
          OA_rp_GetNVM_IlluminationData_Get_BsShare_HWModification: operation=rp_GetNVM_IlluminationData.Get_BsShare_HWModification
          OA_rp_GetNVM_IlluminationData_Get_BsShare_VisMeet_Element: operation=rp_GetNVM_IlluminationData.Get_BsShare_VisMeet_Element
          OA_rp_GetNVM_IlluminationData_Get_BsShare_VisMeet_EOLEntry_Element: operation=rp_GetNVM_IlluminationData.Get_BsShare_VisMeet_EOLEntry_Element
          OA_rp_GetNVM_IlluminationData_Get_BsShare_VehicleConfig_Element: operation=rp_GetNVM_IlluminationData.Get_BsShare_VehicleConfig_Element
          OA_rp_GetNVM_IlluminationData_Get_BsConst_SpeedoGauge_Element: operation=rp_GetNVM_IlluminationData.Get_BsConst_SpeedoGauge_Element
          OA_rp_GetNVM_IlluminationData_Get_BsConst_TachoGauge_Element: operation=rp_GetNVM_IlluminationData.Get_BsConst_TachoGauge_Element
          OA_rp_GetNVM_IlluminationData_Get_BsConst_FuelGauge_Element: operation=rp_GetNVM_IlluminationData.Get_BsConst_FuelGauge_Element
          OA_rp_GetNVM_IlluminationData_Get_BsConst_TempGauge_Element: operation=rp_GetNVM_IlluminationData.Get_BsConst_TempGauge_Element
          OA_rp_GetNVM_IlluminationData_Get_BsConst_PowerGauge_Element: operation=rp_GetNVM_IlluminationData.Get_BsConst_PowerGauge_Element
          OA_rp_GetNVM_IlluminationData_Get_BsConst_OilGauge_Element: operation=rp_GetNVM_IlluminationData.Get_BsConst_OilGauge_Element
          OA_rp_GetNVM_IlluminationData_Get_BsConst_TripComputer_Element: operation=rp_GetNVM_IlluminationData.Get_BsConst_TripComputer_Element
          OA_rp_GetNVM_IlluminationData_Get_BsConst_Compensation_Line_Slope_m: operation=rp_GetNVM_IlluminationData.Get_BsConst_Compensation_Line_Slope_m
          OA_rp_GetNVM_IlluminationData_Get_BsConst_Compensation_Line_Shift_b: operation=rp_GetNVM_IlluminationData.Get_BsConst_Compensation_Line_Shift_b
          OA_rp_GetNVM_IlluminationData_Get_BsConst_Lookup_Curve_HotSpot_Coef_X: operation=rp_GetNVM_IlluminationData.Get_BsConst_Lookup_Curve_HotSpot_Coef_X
          OA_rp_GetNVM_IlluminationData_Get_BsConst_Lookup_Curve_HotSpot_Coef_Y: operation=rp_GetNVM_IlluminationData.Get_BsConst_Lookup_Curve_HotSpot_Coef_Y
          OA_rp_GetNVM_IlluminationData_Get_BsConst_Temp_Threshold_Hysteresis_Derating: operation=rp_GetNVM_IlluminationData.Get_BsConst_Temp_Threshold_Hysteresis_Derating
          OA_rp_GetNVM_IlluminationData_Get_BsConst_Derating_Backlight_Disable: operation=rp_GetNVM_IlluminationData.Get_BsConst_Derating_Backlight_Disable
          OA_rp_GetNVM_IlluminationData_Get_BsConst_Temperature_Sensor_Conv: operation=rp_GetNVM_IlluminationData.Get_BsConst_Temperature_Sensor_Conv
          OA_rp_GetNVM_IlluminationData_Get_BsConst_PCB_Temperature_Sensor_Conv: operation=rp_GetNVM_IlluminationData.Get_BsConst_PCB_Temperature_Sensor_Conv
          OA_rp_GetNVM_IlluminationData_Get_BsConst_Display_Illum_Max_Level: operation=rp_GetNVM_IlluminationData.Get_BsConst_Display_Illum_Max_Level
          OA_rp_GetNVM_IlluminationData_Get_BsConst_PWM_boost_bypass_duty: operation=rp_GetNVM_IlluminationData.Get_BsConst_PWM_boost_bypass_duty
          OA_rp_GetNVM_IlluminationData_Get_BsConst_BsConst_Illumination_ReservedByte: operation=rp_GetNVM_IlluminationData.Get_BsConst_BsConst_Illumination_ReservedByte
          OA_rp_GetNVM_IlluminationData_Get_BsConst_Compensation_Line_Slope_m_SafeCopy1: operation=rp_GetNVM_IlluminationData.Get_BsConst_Compensation_Line_Slope_m_SafeCopy1
          OA_rp_GetNVM_IlluminationData_Get_BsConst_Compensation_Line_Shift_b_SafeCopy1: operation=rp_GetNVM_IlluminationData.Get_BsConst_Compensation_Line_Shift_b_SafeCopy1
          OA_rp_GetNVM_IlluminationData_Get_BsConst_Lookup_Curve_HotSpot_Coef_X_SafeCopy1: operation=rp_GetNVM_IlluminationData.Get_BsConst_Lookup_Curve_HotSpot_Coef_X_SafeCopy1
          OA_rp_GetNVM_IlluminationData_Get_BsConst_Lookup_Curve_HotSpot_Coef_Y_SafeCopy1: operation=rp_GetNVM_IlluminationData.Get_BsConst_Lookup_Curve_HotSpot_Coef_Y_SafeCopy1
          OA_rp_GetNVM_IlluminationData_Get_BsConst_Temp_Threshold_Hysteresis_Derating_SafeCopy1: operation=rp_GetNVM_IlluminationData.Get_BsConst_Temp_Threshold_Hysteresis_Derating_SafeCopy1
          OA_rp_GetNVM_IlluminationData_Get_BsConst_Derating_Backlight_Disable_SafeCopy1: operation=rp_GetNVM_IlluminationData.Get_BsConst_Derating_Backlight_Disable_SafeCopy1
          OA_rp_GetNVM_IlluminationData_Get_BsConst_Temperature_Sensor_Conv_SafeCopy1: operation=rp_GetNVM_IlluminationData.Get_BsConst_Temperature_Sensor_Conv_SafeCopy1
          OA_rp_GetNVM_IlluminationData_Get_BsConst_PCB_Temperature_Sensor_Conv_SafeCopy1: operation=rp_GetNVM_IlluminationData.Get_BsConst_PCB_Temperature_Sensor_Conv_SafeCopy1
          OA_rp_GetNVM_IlluminationData_Get_BsConst_Display_Illum_Max_Level_SafeCopy1: operation=rp_GetNVM_IlluminationData.Get_BsConst_Display_Illum_Max_Level_SafeCopy1
          OA_rp_GetNVM_IlluminationData_Get_BsConst_PWM_boost_bypass_duty_SafeCopy1: operation=rp_GetNVM_IlluminationData.Get_BsConst_PWM_boost_bypass_duty_SafeCopy1
          OA_rp_GetNVM_IlluminationData_Get_BsConst_BsConst_Illumination_ReservedByte_SafeCopy1: operation=rp_GetNVM_IlluminationData.Get_BsConst_BsConst_Illumination_ReservedByte_SafeCopy1
          OA_rp_GetNVM_IlluminationData_Get_BsConst_Compensation_Line_Slope_m_SafeCopy2: operation=rp_GetNVM_IlluminationData.Get_BsConst_Compensation_Line_Slope_m_SafeCopy2
          OA_rp_GetNVM_IlluminationData_Get_BsConst_Compensation_Line_Shift_b_SafeCopy2: operation=rp_GetNVM_IlluminationData.Get_BsConst_Compensation_Line_Shift_b_SafeCopy2
          OA_rp_GetNVM_IlluminationData_Get_BsConst_Lookup_Curve_HotSpot_Coef_X_SafeCopy2: operation=rp_GetNVM_IlluminationData.Get_BsConst_Lookup_Curve_HotSpot_Coef_X_SafeCopy2
          OA_rp_GetNVM_IlluminationData_Get_BsConst_Lookup_Curve_HotSpot_Coef_Y_SafeCopy2: operation=rp_GetNVM_IlluminationData.Get_BsConst_Lookup_Curve_HotSpot_Coef_Y_SafeCopy2
          OA_rp_GetNVM_IlluminationData_Get_BsConst_Temp_Threshold_Hysteresis_Derating_SafeCopy2: operation=rp_GetNVM_IlluminationData.Get_BsConst_Temp_Threshold_Hysteresis_Derating_SafeCopy2
          OA_rp_GetNVM_IlluminationData_Get_BsConst_Derating_Backlight_Disable_SafeCopy2: operation=rp_GetNVM_IlluminationData.Get_BsConst_Derating_Backlight_Disable_SafeCopy2
          OA_rp_GetNVM_IlluminationData_Get_BsConst_Temperature_Sensor_Conv_SafeCopy2: operation=rp_GetNVM_IlluminationData.Get_BsConst_Temperature_Sensor_Conv_SafeCopy2
          OA_rp_GetNVM_IlluminationData_Get_BsConst_PCB_Temperature_Sensor_Conv_SafeCopy2: operation=rp_GetNVM_IlluminationData.Get_BsConst_PCB_Temperature_Sensor_Conv_SafeCopy2
          OA_rp_GetNVM_IlluminationData_Get_BsConst_Display_Illum_Max_Level_SafeCopy2: operation=rp_GetNVM_IlluminationData.Get_BsConst_Display_Illum_Max_Level_SafeCopy2
          OA_rp_GetNVM_IlluminationData_Get_BsConst_PWM_boost_bypass_duty_SafeCopy2: operation=rp_GetNVM_IlluminationData.Get_BsConst_PWM_boost_bypass_duty_SafeCopy2
          OA_rp_GetNVM_IlluminationData_Get_BsConst_BsConst_Illumination_ReservedByte_SafeCopy2: operation=rp_GetNVM_IlluminationData.Get_BsConst_BsConst_Illumination_ReservedByte_SafeCopy2
          OA_rp_GetNVM_IlluminationData_Get_BsConst_Audio_Element: operation=rp_GetNVM_IlluminationData.Get_BsConst_Audio_Element
          OA_rp_GetNVM_IlluminationData_Get_BsConst_Warning_Element: operation=rp_GetNVM_IlluminationData.Get_BsConst_Warning_Element
          OA_rp_GetNVM_IlluminationData_Get_BsConst_RealTimeClock_Element: operation=rp_GetNVM_IlluminationData.Get_BsConst_RealTimeClock_Element
          OA_rp_GetNVM_IlluminationData_Get_BsConst_Communication_Element: operation=rp_GetNVM_IlluminationData.Get_BsConst_Communication_Element
          OA_rp_GetNVM_IlluminationData_Get_BsConst_Power_Element: operation=rp_GetNVM_IlluminationData.Get_BsConst_Power_Element
          OA_rp_GetNVM_IlluminationData_Get_BsConst_ServiceReminder_Element: operation=rp_GetNVM_IlluminationData.Get_BsConst_ServiceReminder_Element
          OA_rp_GetNVM_IlluminationData_Get_BsConst_EngOffTimer_Element: operation=rp_GetNVM_IlluminationData.Get_BsConst_EngOffTimer_Element
          OA_rp_GetNVM_IlluminationData_Get_BsCys_Certicificate_Element: operation=rp_GetNVM_IlluminationData.Get_BsCys_Certicificate_Element
          OA_rp_GetNVM_IlluminationData_Get_RefCys_Certicificate_Element: operation=rp_GetNVM_IlluminationData.Get_RefCys_Certicificate_Element
          OA_rp_GetNVM_IlluminationData_Get_RefCys_Certicificate1_Element: operation=rp_GetNVM_IlluminationData.Get_RefCys_Certicificate1_Element
          OA_rp_GetNVM_IlluminationData_Get_BsRt_Odometer_Element: operation=rp_GetNVM_IlluminationData.Get_BsRt_Odometer_Element
          OA_rp_GetNVM_IlluminationData_Get_BsRt_SpeedoGauge_Element: operation=rp_GetNVM_IlluminationData.Get_BsRt_SpeedoGauge_Element
          OA_rp_GetNVM_IlluminationData_Get_BsRt_TachoGauge_Element: operation=rp_GetNVM_IlluminationData.Get_BsRt_TachoGauge_Element
          OA_rp_GetNVM_IlluminationData_Get_BsRt_FuelGauge_Element: operation=rp_GetNVM_IlluminationData.Get_BsRt_FuelGauge_Element
          OA_rp_GetNVM_IlluminationData_Get_BsRt_TempGauge_Element: operation=rp_GetNVM_IlluminationData.Get_BsRt_TempGauge_Element
          OA_rp_GetNVM_IlluminationData_Get_BsRt_PowerGauge_Element: operation=rp_GetNVM_IlluminationData.Get_BsRt_PowerGauge_Element
          OA_rp_GetNVM_IlluminationData_Get_BsRt_OilGauge_Element: operation=rp_GetNVM_IlluminationData.Get_BsRt_OilGauge_Element
          OA_rp_GetNVM_IlluminationData_Get_BsRt_TripComputer_Element: operation=rp_GetNVM_IlluminationData.Get_BsRt_TripComputer_Element
          OA_rp_GetNVM_IlluminationData_Get_BsRt_Warning_Element: operation=rp_GetNVM_IlluminationData.Get_BsRt_Warning_Element
          OA_rp_GetNVM_IlluminationData_Get_BsRt_RealTimeClock_Element: operation=rp_GetNVM_IlluminationData.Get_BsRt_RealTimeClock_Element
          OA_rp_GetNVM_IlluminationData_Get_BsRt_Personalization_Element: operation=rp_GetNVM_IlluminationData.Get_BsRt_Personalization_Element
          OA_rp_GetNVM_IlluminationData_Get_BsRt_Illumination_Element: operation=rp_GetNVM_IlluminationData.Get_BsRt_Illumination_Element
          OA_rp_GetNVM_IlluminationData_Get_BsRt_CusDlt_Element: operation=rp_GetNVM_IlluminationData.Get_BsRt_CusDlt_Element
          OA_rp_GetNVM_IlluminationData_Get_BsReten_Odometer_Element: operation=rp_GetNVM_IlluminationData.Get_BsReten_Odometer_Element
          OA_rp_GetNVM_IlluminationData_Get_BsReten_Gauges_Element: operation=rp_GetNVM_IlluminationData.Get_BsReten_Gauges_Element
          OA_rp_GetNVM_IlluminationData_Get_BsReten_Tripcomputer_Element: operation=rp_GetNVM_IlluminationData.Get_BsReten_Tripcomputer_Element
          OA_rp_GetNVM_IlluminationData_Get_BsReten_Illumination_Element: operation=rp_GetNVM_IlluminationData.Get_BsReten_Illumination_Element
          OA_rp_GetNVM_IlluminationData_Get_BsReten_Audio_Element: operation=rp_GetNVM_IlluminationData.Get_BsReten_Audio_Element
          OA_rp_GetNVM_IlluminationData_Get_BsReten_Warning_Element: operation=rp_GetNVM_IlluminationData.Get_BsReten_Warning_Element
          OA_rp_GetNVM_IlluminationData_Get_BsReten_RealTimeClock_Element: operation=rp_GetNVM_IlluminationData.Get_BsReten_RealTimeClock_Element
          OA_rp_GetNVM_IlluminationData_Get_BsReten_Communication_Element: operation=rp_GetNVM_IlluminationData.Get_BsReten_Communication_Element
          OA_rp_GetNVM_IlluminationData_Get_BsReten_Personalization_Element: operation=rp_GetNVM_IlluminationData.Get_BsReten_Personalization_Element
          OA_rp_GetNVM_IlluminationData_Get_BsReten_Power_Element: operation=rp_GetNVM_IlluminationData.Get_BsReten_Power_Element
          OA_rp_GetNVM_IlluminationData_Get_BsReten_Display_Element: operation=rp_GetNVM_IlluminationData.Get_BsReten_Display_Element
          OA_rp_GetNVM_IlluminationData_Get_BsDiag_ErrorRecord_Element: operation=rp_GetNVM_IlluminationData.Get_BsDiag_ErrorRecord_Element
          OA_rp_GetNVM_IlluminationData_Get_BsDiag_Dtc_Element: operation=rp_GetNVM_IlluminationData.Get_BsDiag_Dtc_Element
          OA_rp_Get_Variant_Cfg_Get_Variant_Config_State: operation=rp_Get_Variant_Cfg.Get_Variant_Config_State
          OA_rp_ILL_ReadyToSleep_SWCSleepStatus: operation=rp_ILL_ReadyToSleep.SWCSleepStatus
          OA_rp_IoHwAb_ADC_GetAsyncRawAdc: operation=rp_IoHwAb_ADC.GetAsyncRawAdc
          OA_rp_IoHwAb_ADC_GetSyncRawAdc: operation=rp_IoHwAb_ADC.GetSyncRawAdc
          OA_rp_IoHwAb_ADC_GetProcessedAdc: operation=rp_IoHwAb_ADC.GetProcessedAdc
          OA_rp_PwmWithTime_GetPwmWithTime: operation=rp_PwmWithTime.GetPwmWithTime
          OA_rp_PwmWithTimeExp_GetPwmWithTimeExp: operation=rp_PwmWithTimeExp.GetPwmWithTimeExp
          OA_rp_SetNVM_IlluminationData_Set_BsShare_SwUpdReflash_Element: operation=rp_SetNVM_IlluminationData.Set_BsShare_SwUpdReflash_Element
          OA_rp_SetNVM_IlluminationData_Set_BsShare_SwUpdFotaMode_Element: operation=rp_SetNVM_IlluminationData.Set_BsShare_SwUpdFotaMode_Element
          OA_rp_SetNVM_IlluminationData_Set_BsShare_SwUpdFotaFinPrint_Element: operation=rp_SetNVM_IlluminationData.Set_BsShare_SwUpdFotaFinPrint_Element
          OA_rp_SetNVM_IlluminationData_Set_BsShare_SwUpdFotaStatus_Element: operation=rp_SetNVM_IlluminationData.Set_BsShare_SwUpdFotaStatus_Element
          OA_rp_SetNVM_IlluminationData_Set_BsShare_SwUpdFotadecrypt_Element: operation=rp_SetNVM_IlluminationData.Set_BsShare_SwUpdFotadecrypt_Element
          OA_rp_SetNVM_IlluminationData_Set_BsShare_EcuPartNumber_Element: operation=rp_SetNVM_IlluminationData.Set_BsShare_EcuPartNumber_Element
          OA_rp_SetNVM_IlluminationData_Set_BsShare_VisteonPartNumber: operation=rp_SetNVM_IlluminationData.Set_BsShare_VisteonPartNumber
          OA_rp_SetNVM_IlluminationData_Set_BsShare_VisteonPCBPartNumber: operation=rp_SetNVM_IlluminationData.Set_BsShare_VisteonPCBPartNumber
          OA_rp_SetNVM_IlluminationData_Set_BsShare_ProductSerialNumber: operation=rp_SetNVM_IlluminationData.Set_BsShare_ProductSerialNumber
          OA_rp_SetNVM_IlluminationData_Set_BsShare_PCBSerialNumber: operation=rp_SetNVM_IlluminationData.Set_BsShare_PCBSerialNumber
          OA_rp_SetNVM_IlluminationData_Set_BsShare_SMTManufacturingDate: operation=rp_SetNVM_IlluminationData.Set_BsShare_SMTManufacturingDate
          OA_rp_SetNVM_IlluminationData_Set_BsShare_AssemblyManufacturingDate: operation=rp_SetNVM_IlluminationData.Set_BsShare_AssemblyManufacturingDate
          OA_rp_SetNVM_IlluminationData_Set_BsShare_SMTPlantNumber: operation=rp_SetNVM_IlluminationData.Set_BsShare_SMTPlantNumber
          OA_rp_SetNVM_IlluminationData_Set_BsShare_AssemblyPlantNumber: operation=rp_SetNVM_IlluminationData.Set_BsShare_AssemblyPlantNumber
          OA_rp_SetNVM_IlluminationData_Set_BsShare_HWModification: operation=rp_SetNVM_IlluminationData.Set_BsShare_HWModification
          OA_rp_SetNVM_IlluminationData_Set_BsShare_VisMeet_Element: operation=rp_SetNVM_IlluminationData.Set_BsShare_VisMeet_Element
          OA_rp_SetNVM_IlluminationData_Set_BsShare_VisMeet_EOLEntry_Element: operation=rp_SetNVM_IlluminationData.Set_BsShare_VisMeet_EOLEntry_Element
          OA_rp_SetNVM_IlluminationData_Set_BsShare_VehicleConfig_Element: operation=rp_SetNVM_IlluminationData.Set_BsShare_VehicleConfig_Element
          OA_rp_SetNVM_IlluminationData_Set_BsConst_SpeedoGauge_Element: operation=rp_SetNVM_IlluminationData.Set_BsConst_SpeedoGauge_Element
          OA_rp_SetNVM_IlluminationData_Set_BsConst_TachoGauge_Element: operation=rp_SetNVM_IlluminationData.Set_BsConst_TachoGauge_Element
          OA_rp_SetNVM_IlluminationData_Set_BsConst_FuelGauge_Element: operation=rp_SetNVM_IlluminationData.Set_BsConst_FuelGauge_Element
          OA_rp_SetNVM_IlluminationData_Set_BsConst_TempGauge_Element: operation=rp_SetNVM_IlluminationData.Set_BsConst_TempGauge_Element
          OA_rp_SetNVM_IlluminationData_Set_BsConst_PowerGauge_Element: operation=rp_SetNVM_IlluminationData.Set_BsConst_PowerGauge_Element
          OA_rp_SetNVM_IlluminationData_Set_BsConst_OilGauge_Element: operation=rp_SetNVM_IlluminationData.Set_BsConst_OilGauge_Element
          OA_rp_SetNVM_IlluminationData_Set_BsConst_TripComputer_Element: operation=rp_SetNVM_IlluminationData.Set_BsConst_TripComputer_Element
          OA_rp_SetNVM_IlluminationData_Set_BsConst_Compensation_Line_Slope_m: operation=rp_SetNVM_IlluminationData.Set_BsConst_Compensation_Line_Slope_m
          OA_rp_SetNVM_IlluminationData_Set_BsConst_Compensation_Line_Shift_b: operation=rp_SetNVM_IlluminationData.Set_BsConst_Compensation_Line_Shift_b
          OA_rp_SetNVM_IlluminationData_Set_BsConst_Lookup_Curve_HotSpot_Coef_X: operation=rp_SetNVM_IlluminationData.Set_BsConst_Lookup_Curve_HotSpot_Coef_X
          OA_rp_SetNVM_IlluminationData_Set_BsConst_Lookup_Curve_HotSpot_Coef_Y: operation=rp_SetNVM_IlluminationData.Set_BsConst_Lookup_Curve_HotSpot_Coef_Y
          OA_rp_SetNVM_IlluminationData_Set_BsConst_Temp_Threshold_Hysteresis_Derating: operation=rp_SetNVM_IlluminationData.Set_BsConst_Temp_Threshold_Hysteresis_Derating
          OA_rp_SetNVM_IlluminationData_Set_BsConst_Derating_Backlight_Disable: operation=rp_SetNVM_IlluminationData.Set_BsConst_Derating_Backlight_Disable
          OA_rp_SetNVM_IlluminationData_Set_BsConst_Temperature_Sensor_Conv: operation=rp_SetNVM_IlluminationData.Set_BsConst_Temperature_Sensor_Conv
          OA_rp_SetNVM_IlluminationData_Set_BsConst_PCB_Temperature_Sensor_Conv: operation=rp_SetNVM_IlluminationData.Set_BsConst_PCB_Temperature_Sensor_Conv
          OA_rp_SetNVM_IlluminationData_Set_BsConst_Display_Illum_Max_Level: operation=rp_SetNVM_IlluminationData.Set_BsConst_Display_Illum_Max_Level
          OA_rp_SetNVM_IlluminationData_Set_BsConst_PWM_boost_bypass_duty: operation=rp_SetNVM_IlluminationData.Set_BsConst_PWM_boost_bypass_duty
          OA_rp_SetNVM_IlluminationData_Set_BsConst_BsConst_Illumination_ReservedByte: operation=rp_SetNVM_IlluminationData.Set_BsConst_BsConst_Illumination_ReservedByte
          OA_rp_SetNVM_IlluminationData_Set_BsConst_Compensation_Line_Slope_m_SafeCopy1: operation=rp_SetNVM_IlluminationData.Set_BsConst_Compensation_Line_Slope_m_SafeCopy1
          OA_rp_SetNVM_IlluminationData_Set_BsConst_Compensation_Line_Shift_b_SafeCopy1: operation=rp_SetNVM_IlluminationData.Set_BsConst_Compensation_Line_Shift_b_SafeCopy1
          OA_rp_SetNVM_IlluminationData_Set_BsConst_Lookup_Curve_HotSpot_Coef_X_SafeCopy1: operation=rp_SetNVM_IlluminationData.Set_BsConst_Lookup_Curve_HotSpot_Coef_X_SafeCopy1
          OA_rp_SetNVM_IlluminationData_Set_BsConst_Lookup_Curve_HotSpot_Coef_Y_SafeCopy1: operation=rp_SetNVM_IlluminationData.Set_BsConst_Lookup_Curve_HotSpot_Coef_Y_SafeCopy1
          OA_rp_SetNVM_IlluminationData_Set_BsConst_Temp_Threshold_Hysteresis_Derating_SafeCopy1: operation=rp_SetNVM_IlluminationData.Set_BsConst_Temp_Threshold_Hysteresis_Derating_SafeCopy1
          OA_rp_SetNVM_IlluminationData_Set_BsConst_Derating_Backlight_Disable_SafeCopy1: operation=rp_SetNVM_IlluminationData.Set_BsConst_Derating_Backlight_Disable_SafeCopy1
          OA_rp_SetNVM_IlluminationData_Set_BsConst_Temperature_Sensor_Conv_SafeCopy1: operation=rp_SetNVM_IlluminationData.Set_BsConst_Temperature_Sensor_Conv_SafeCopy1
          OA_rp_SetNVM_IlluminationData_Set_BsConst_PCB_Temperature_Sensor_Conv_SafeCopy1: operation=rp_SetNVM_IlluminationData.Set_BsConst_PCB_Temperature_Sensor_Conv_SafeCopy1
          OA_rp_SetNVM_IlluminationData_Set_BsConst_Display_Illum_Max_Level_SafeCopy1: operation=rp_SetNVM_IlluminationData.Set_BsConst_Display_Illum_Max_Level_SafeCopy1
          OA_rp_SetNVM_IlluminationData_Set_BsConst_PWM_boost_bypass_duty_SafeCopy1: operation=rp_SetNVM_IlluminationData.Set_BsConst_PWM_boost_bypass_duty_SafeCopy1
          OA_rp_SetNVM_IlluminationData_Set_BsConst_BsConst_Illumination_ReservedByte_SafeCopy1: operation=rp_SetNVM_IlluminationData.Set_BsConst_BsConst_Illumination_ReservedByte_SafeCopy1
          OA_rp_SetNVM_IlluminationData_Set_BsConst_Compensation_Line_Slope_m_SafeCopy2: operation=rp_SetNVM_IlluminationData.Set_BsConst_Compensation_Line_Slope_m_SafeCopy2
          OA_rp_SetNVM_IlluminationData_Set_BsConst_Compensation_Line_Shift_b_SafeCopy2: operation=rp_SetNVM_IlluminationData.Set_BsConst_Compensation_Line_Shift_b_SafeCopy2
          OA_rp_SetNVM_IlluminationData_Set_BsConst_Lookup_Curve_HotSpot_Coef_X_SafeCopy2: operation=rp_SetNVM_IlluminationData.Set_BsConst_Lookup_Curve_HotSpot_Coef_X_SafeCopy2
          OA_rp_SetNVM_IlluminationData_Set_BsConst_Lookup_Curve_HotSpot_Coef_Y_SafeCopy2: operation=rp_SetNVM_IlluminationData.Set_BsConst_Lookup_Curve_HotSpot_Coef_Y_SafeCopy2
          OA_rp_SetNVM_IlluminationData_Set_BsConst_Temp_Threshold_Hysteresis_Derating_SafeCopy2: operation=rp_SetNVM_IlluminationData.Set_BsConst_Temp_Threshold_Hysteresis_Derating_SafeCopy2
          OA_rp_SetNVM_IlluminationData_Set_BsConst_Derating_Backlight_Disable_SafeCopy2: operation=rp_SetNVM_IlluminationData.Set_BsConst_Derating_Backlight_Disable_SafeCopy2
          OA_rp_SetNVM_IlluminationData_Set_BsConst_Temperature_Sensor_Conv_SafeCopy2: operation=rp_SetNVM_IlluminationData.Set_BsConst_Temperature_Sensor_Conv_SafeCopy2
          OA_rp_SetNVM_IlluminationData_Set_BsConst_PCB_Temperature_Sensor_Conv_SafeCopy2: operation=rp_SetNVM_IlluminationData.Set_BsConst_PCB_Temperature_Sensor_Conv_SafeCopy2
          OA_rp_SetNVM_IlluminationData_Set_BsConst_Display_Illum_Max_Level_SafeCopy2: operation=rp_SetNVM_IlluminationData.Set_BsConst_Display_Illum_Max_Level_SafeCopy2
          OA_rp_SetNVM_IlluminationData_Set_BsConst_PWM_boost_bypass_duty_SafeCopy2: operation=rp_SetNVM_IlluminationData.Set_BsConst_PWM_boost_bypass_duty_SafeCopy2
          OA_rp_SetNVM_IlluminationData_Set_BsConst_BsConst_Illumination_ReservedByte_SafeCopy2: operation=rp_SetNVM_IlluminationData.Set_BsConst_BsConst_Illumination_ReservedByte_SafeCopy2
          OA_rp_SetNVM_IlluminationData_Set_BsConst_Audio_Element: operation=rp_SetNVM_IlluminationData.Set_BsConst_Audio_Element
          OA_rp_SetNVM_IlluminationData_Set_BsConst_Warning_Element: operation=rp_SetNVM_IlluminationData.Set_BsConst_Warning_Element
          OA_rp_SetNVM_IlluminationData_Set_BsConst_RealTimeClock_Element: operation=rp_SetNVM_IlluminationData.Set_BsConst_RealTimeClock_Element
          OA_rp_SetNVM_IlluminationData_Set_BsConst_Communication_Element: operation=rp_SetNVM_IlluminationData.Set_BsConst_Communication_Element
          OA_rp_SetNVM_IlluminationData_Set_BsConst_Power_Element: operation=rp_SetNVM_IlluminationData.Set_BsConst_Power_Element
          OA_rp_SetNVM_IlluminationData_Set_BsConst_ServiceReminder_Element: operation=rp_SetNVM_IlluminationData.Set_BsConst_ServiceReminder_Element
          OA_rp_SetNVM_IlluminationData_Set_BsConst_EngOffTimer_Element: operation=rp_SetNVM_IlluminationData.Set_BsConst_EngOffTimer_Element
          OA_rp_SetNVM_IlluminationData_Set_BsCys_Certicificate_Element: operation=rp_SetNVM_IlluminationData.Set_BsCys_Certicificate_Element
          OA_rp_SetNVM_IlluminationData_Set_RefCys_Certicificate_Element: operation=rp_SetNVM_IlluminationData.Set_RefCys_Certicificate_Element
          OA_rp_SetNVM_IlluminationData_Set_RefCys_Certicificate1_Element: operation=rp_SetNVM_IlluminationData.Set_RefCys_Certicificate1_Element
          OA_rp_SetNVM_IlluminationData_Set_BsRt_Odometer_Element: operation=rp_SetNVM_IlluminationData.Set_BsRt_Odometer_Element
          OA_rp_SetNVM_IlluminationData_Set_BsRt_SpeedoGauge_Element: operation=rp_SetNVM_IlluminationData.Set_BsRt_SpeedoGauge_Element
          OA_rp_SetNVM_IlluminationData_Set_BsRt_TachoGauge_Element: operation=rp_SetNVM_IlluminationData.Set_BsRt_TachoGauge_Element
          OA_rp_SetNVM_IlluminationData_Set_BsRt_FuelGauge_Element: operation=rp_SetNVM_IlluminationData.Set_BsRt_FuelGauge_Element
          OA_rp_SetNVM_IlluminationData_Set_BsRt_TempGauge_Element: operation=rp_SetNVM_IlluminationData.Set_BsRt_TempGauge_Element
          OA_rp_SetNVM_IlluminationData_Set_BsRt_PowerGauge_Element: operation=rp_SetNVM_IlluminationData.Set_BsRt_PowerGauge_Element
          OA_rp_SetNVM_IlluminationData_Set_BsRt_OilGauge_Element: operation=rp_SetNVM_IlluminationData.Set_BsRt_OilGauge_Element
          OA_rp_SetNVM_IlluminationData_Set_BsRt_TripComputer_Element: operation=rp_SetNVM_IlluminationData.Set_BsRt_TripComputer_Element
          OA_rp_SetNVM_IlluminationData_Set_BsRt_Warning_Element: operation=rp_SetNVM_IlluminationData.Set_BsRt_Warning_Element
          OA_rp_SetNVM_IlluminationData_Set_BsRt_RealTimeClock_Element: operation=rp_SetNVM_IlluminationData.Set_BsRt_RealTimeClock_Element
          OA_rp_SetNVM_IlluminationData_Set_BsRt_Personalization_Element: operation=rp_SetNVM_IlluminationData.Set_BsRt_Personalization_Element
          OA_rp_SetNVM_IlluminationData_Set_BsRt_Illumination_Element: operation=rp_SetNVM_IlluminationData.Set_BsRt_Illumination_Element
          OA_rp_SetNVM_IlluminationData_Set_BsRt_CusDlt_Element: operation=rp_SetNVM_IlluminationData.Set_BsRt_CusDlt_Element
          OA_rp_SetNVM_IlluminationData_Set_BsReten_Odometer_Element: operation=rp_SetNVM_IlluminationData.Set_BsReten_Odometer_Element
          OA_rp_SetNVM_IlluminationData_Set_BsReten_Gauges_Element: operation=rp_SetNVM_IlluminationData.Set_BsReten_Gauges_Element
          OA_rp_SetNVM_IlluminationData_Set_BsReten_Tripcomputer_Element: operation=rp_SetNVM_IlluminationData.Set_BsReten_Tripcomputer_Element
          OA_rp_SetNVM_IlluminationData_Set_BsReten_Illumination_Element: operation=rp_SetNVM_IlluminationData.Set_BsReten_Illumination_Element
          OA_rp_SetNVM_IlluminationData_Set_BsReten_Audio_Element: operation=rp_SetNVM_IlluminationData.Set_BsReten_Audio_Element
          OA_rp_SetNVM_IlluminationData_Set_BsReten_Warning_Element: operation=rp_SetNVM_IlluminationData.Set_BsReten_Warning_Element
          OA_rp_SetNVM_IlluminationData_Set_BsReten_RealTimeClock_Element: operation=rp_SetNVM_IlluminationData.Set_BsReten_RealTimeClock_Element
          OA_rp_SetNVM_IlluminationData_Set_BsReten_Communication_Element: operation=rp_SetNVM_IlluminationData.Set_BsReten_Communication_Element
          OA_rp_SetNVM_IlluminationData_Set_BsReten_Personalization_Element: operation=rp_SetNVM_IlluminationData.Set_BsReten_Personalization_Element
          OA_rp_SetNVM_IlluminationData_Set_BsReten_Power_Element: operation=rp_SetNVM_IlluminationData.Set_BsReten_Power_Element
          OA_rp_SetNVM_IlluminationData_Set_BsReten_Display_Element: operation=rp_SetNVM_IlluminationData.Set_BsReten_Display_Element
          OA_rp_SetNVM_IlluminationData_Set_BsDiag_ErrorRecord_Element: operation=rp_SetNVM_IlluminationData.Set_BsDiag_ErrorRecord_Element
          OA_rp_SetNVM_IlluminationData_Set_BsDiag_Dtc_Element: operation=rp_SetNVM_IlluminationData.Set_BsDiag_Dtc_Element
          OA_rp_UpdatePwmDirect_GetPwmDirect: operation=rp_UpdatePwmDirect.GetPwmDirect
          OA_rp_Variant_Status_GetVariant_Status: operation=rp_Variant_Status.GetVariant_Status
  35 x constant specification:
    Mdl_DimIllumCtrl_Ip_DataValue0: value-spec={short-label=Mdl_DimIllumCtrl_Ip_DataValue0, fields=[Mdl_DimIllumCtrl_Ip_DataValue_0:0, Mdl_DimIllumCtrl_Ip_DataValue_1:0, Mdl_DimIllumCtrl_Ip_DataValue_2:0, Mdl_DimIllumCtrl_Ip_DataValue_3:0, Mdl_DimIllumCtrl_Ip_DataValue_4:0, Mdl_DimIllumCtrl_Ip_DataValue_5:0, Mdl_DimIllumCtrl_Ip_DataValue_6:0, Mdl_DimIllumCtrl_Ip_DataValue_7:0]}
    Mdl_DimTrans_StepvlaueValue0: value-spec=Mdl_DimTrans_StepvlaueValue0:0
    Mdl_DimDutyValueValue0: value-spec=Mdl_DimDutyValueValue0:0
    Mdl_DimilumDNRequiredValue0: value-spec=Mdl_DimilumDNRequiredValue0:0
    Mdl_DimillumDNStatusValue0: value-spec=Mdl_DimillumDNStatusValue0:0
    Mdl_DimIllumStepValueValue0: value-spec=Mdl_DimIllumStepValueValue0:0
    Mdl_DimRGBStepValueValue0: value-spec=Mdl_DimRGBStepValueValue0:0
    Mdl_DimRHDW_DbcValue0: value-spec=Mdl_DimRHDW_DbcValue0:0
    Mdl_DimRHUP_DbcValue0: value-spec=Mdl_DimRHUP_DbcValue0:0
    Mdl_DimRawdataStatusValue0: value-spec=Mdl_DimRawdataStatusValue0:0
    Mdl_DimSwitchStatusValue0: value-spec=Mdl_DimSwitchStatusValue0:0
    Mdl_DimRheostatDayStepValue0: value-spec=Mdl_DimRheostatDayStepValue0:0
    Mdl_DimRheostatNightStepValue0: value-spec=Mdl_DimRheostatNightStepValue0:0
    Mdl_DimRheostatONSStatusValue0: value-spec=Mdl_DimRheostatONSStatusValue0:0
    Mdl_DimRheostatSwTypeValue0: value-spec=Mdl_DimRheostatSwTypeValue0:0
    Mdl_DimRheostat_OnSTimeValue0: value-spec=Mdl_DimRheostat_OnSTimeValue0:0
    Mdl_DimStarterStatus_OutValue0: value-spec=Mdl_DimStarterStatus_OutValue0:0
    Mdl_DimRheoUpdateValValue0: value-spec=Mdl_DimRheoUpdateValValue0:0
    Mdl_DimIllum_StatusValue0: value-spec=Mdl_DimIllum_StatusValue0:0
    Mdl_DimIllumStatusValue0: value-spec=Mdl_DimIllumStatusValue0:0
    Mdl_DimIgnitionSubstateValue0: value-spec=Mdl_DimIgnitionSubstateValue0:0
    Mdl_DimWSSCurrentVehicleStateValue0: value-spec=Mdl_DimWSSCurrentVehicleStateValue0:0
    Mdl_DimWSSCurrentClusterModeValue0: value-spec=Mdl_DimWSSCurrentClusterModeValue0:0
    Mdl_DimReady_to_SleepValue0: value-spec=Mdl_DimReady_to_SleepValue0:false
    Mdl_DimAppIdValue0: value-spec=Mdl_DimAppIdValue0:0
    Mdl_DimDiag_RheoStatValue0: value-spec=Mdl_DimDiag_RheoStatValue0:0
    Mdl_DimEcoRunPresenceFlagValue0: value-spec=Mdl_DimEcoRunPresenceFlagValue0:0
    Mdl_DimIlumDayNightRequiredValue0: value-spec=Mdl_DimIlumDayNightRequiredValue0:0
    Mdl_DimDay_Night_StatusValue0: value-spec=Mdl_DimDay_Night_StatusValue0:0
    Mdl_DimPowerTrain_FlagValue0: value-spec=Mdl_DimPowerTrain_FlagValue0:0
    Mdl_Dimchannel_idValue0: value-spec=Mdl_Dimchannel_idValue0:0
    Mdl_DimTFTDisplayOnValue0: value-spec=Mdl_DimTFTDisplayOnValue0:0
    Mdl_DimCurrentUserIDValue0: value-spec=Mdl_DimCurrentUserIDValue0:0
    Mdl_DimCustomizeResetValue0: value-spec=Mdl_DimCustomizeResetValue0:0
    Mdl_DimSettingResetResultValue0: value-spec=Mdl_DimSettingResetResultValue0:0
  swc implementation IMPL_Mdl_Dim: programming-language=C, behavior=IB_Mdl_Dim
    code-descriptors:
      code CodeDescriptor
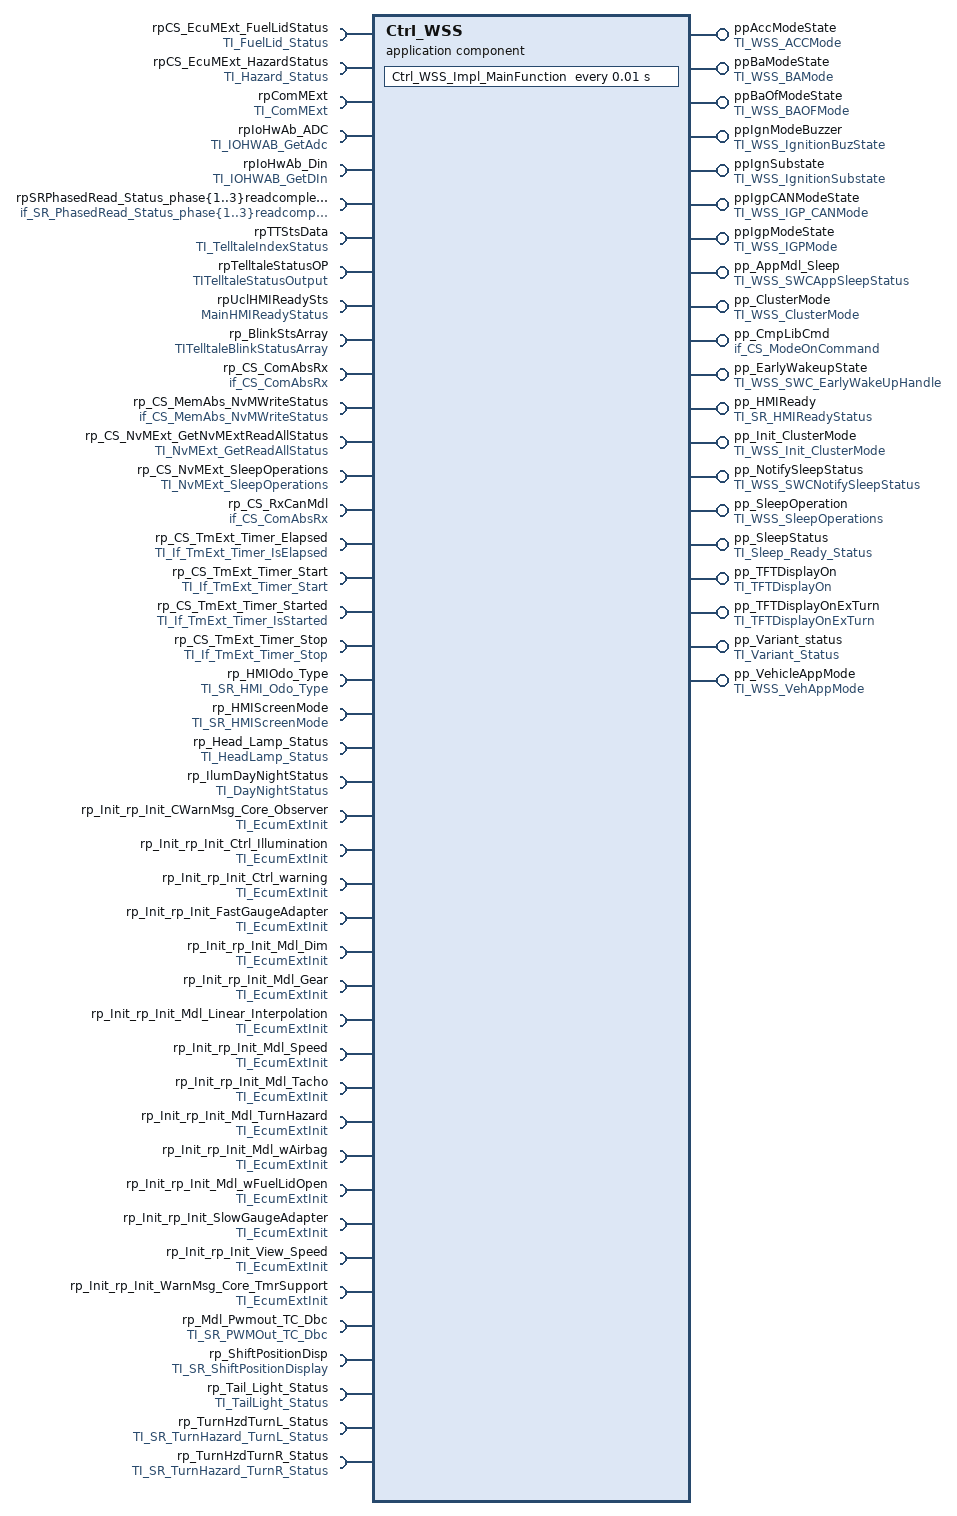
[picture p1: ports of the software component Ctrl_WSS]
  application sw component type Ctrl_WSS
    20 x provide port:
      ppAccModeState: nonqueued-sender-com-spec{data-element=WSSAccState, init-value=constant-reference=Ctrl_WSSWSSAccStateValue0}, provided-interface=TI_WSS_ACCMode
      ppBaModeState: nonqueued-sender-com-spec{data-element=WSSBaState, init-value=constant-reference=Ctrl_WSSWSSBaStateValue0}, provided-interface=TI_WSS_BAMode
      ppBaOfModeState: nonqueued-sender-com-spec{data-element=WSSBaOfState, init-value=constant-reference=Ctrl_WSSWSSBaOfStateValue0}, provided-interface=TI_WSS_BAOFMode
      ppIgnModeBuzzer: nonqueued-sender-com-spec{data-element=IgnitioBuznstate, init-value=constant-reference=Ctrl_WSSIgnitioBuznstateValue0}, provided-interface=TI_WSS_IgnitionBuzState
      ppIgnSubstate: nonqueued-sender-com-spec{data-element=IgnitionSubstate, init-value=constant-reference=Ctrl_WSSIgnitionSubstateValue0}, provided-interface=TI_WSS_IgnitionSubstate
      ppIgpCANModeState: nonqueued-sender-com-spec{data-element=WSSIGPCANState, init-value=constant-reference=Ctrl_WSSWSSIGPCANStateValue0}, provided-interface=TI_WSS_IGP_CANMode
      ppIgpModeState: nonqueued-sender-com-spec{data-element=WSSIGPState, init-value=constant-reference=Ctrl_WSSWSSIGPStateValue0}, provided-interface=TI_WSS_IGPMode
      pp_AppMdl_Sleep: server-com-spec{operation=SWCSleepStatus, queue-length=1}, provided-interface=TI_WSS_SWCAppSleepStatus
      pp_ClusterMode: nonqueued-sender-com-spec{data-element=WSSCurrentClusterMode, init-value=constant-reference=Ctrl_WSSWSSCurrentClusterModeValue0}, provided-interface=TI_WSS_ClusterMode
      pp_CmpLibCmd: server-com-spec{operation=Impl_OnCommand, queue-length=1}, provided-interface=if_CS_ModeOnCommand
      pp_EarlyWakeupState: server-com-spec{operation=SWCEarlyWakeUpHandle, queue-length=1}, provided-interface=TI_WSS_SWC_EarlyWakeUpHandle
      pp_HMIReady: nonqueued-sender-com-spec{data-element=HMI_ReadyStatus, init-value=constant-reference=Ctrl_WSSHMI_ReadyStatusValue0}, provided-interface=TI_SR_HMIReadyStatus
      pp_Init_ClusterMode: nonqueued-sender-com-spec{data-element=WSSCurrentClusterInitMode, init-value=constant-reference=Ctrl_WSSWSSCurrentClusterInitModeValue0}, provided-interface=TI_WSS_Init_ClusterMode
      pp_NotifySleepStatus: server-com-spec{operation=CtrlWSS_NotifyNetworkSleep, queue-length=1}, provided-interface=TI_WSS_SWCNotifySleepStatus
      pp_SleepOperation: provided-interface=TI_WSS_SleepOperations
        provided-com-specs:
          operation=CtrlWSS_CancelSleep, queue-length=1
          operation=CtrlWSS_ReadytoSleep, queue-length=1
          operation=CtrlWSS_RequestSleep, queue-length=1
      pp_SleepStatus: nonqueued-sender-com-spec{data-element=Sleep_Status, init-value=constant-reference=Ctrl_WSSSleep_StatusValue0}, provided-interface=TI_Sleep_Ready_Status
      pp_TFTDisplayOn: nonqueued-sender-com-spec{data-element=TFTDisplayOn, init-value=constant-reference=Ctrl_WSSTFTDisplayOnValue0}, provided-interface=TI_TFTDisplayOn
      pp_TFTDisplayOnExTurn: nonqueued-sender-com-spec{data-element=TFTDisplayOnExTurn, init-value=constant-reference=Ctrl_WSSTFTDisplayOnExTurnValue0}, provided-interface=TI_TFTDisplayOnExTurn
      pp_Variant_status: server-com-spec{operation=GetVariant_Status, queue-length=1}, provided-interface=TI_Variant_Status
      pp_VehicleAppMode: nonqueued-sender-com-spec{data-element=WSSCurrentVehicleState, init-value=constant-reference=Ctrl_WSSWSSCurrentVehicleStateValue0}, provided-interface=TI_WSS_VehAppMode
    45 x require port:
      rpCS_EcuMExt_FuelLidStatus: queued-receiver-com-spec{data-element=FuelLidStatus, queue-length=15}, required-interface=TI_FuelLid_Status
      rpCS_EcuMExt_HazardStatus: queued-receiver-com-spec{data-element=HazardStatus, queue-length=15}, required-interface=TI_Hazard_Status
      rpComMExt: required-interface=TI_ComMExt
      rpIoHwAb_ADC: required-interface=TI_IOHWAB_GetAdc
      rpIoHwAb_Din: required-interface=TI_IOHWAB_GetDIn
      rpSRPhasedRead_Status_phase{1..3}readcompleted: nonqueued-receiver-com-spec{data-element=PhasedRead_Status_phase{1..3}readcompleted, init-value=constant-reference=Ctrl_WSSPhasedRead_Status_phase{1..3}readcompletedValue0}, required-interface=if_SR_PhasedRead_Status_phase{1..3}readcompleted
      rpTTStsData: required-interface=TI_TelltaleIndexStatus
        required-com-specs:
          data-element=TTIndex, init-value=constant-reference=Ctrl_WSSTTIndexValue0
          data-element=TTStatus, init-value=constant-reference=Ctrl_WSSTTStatusValue0
      rpTelltaleStatusOP: nonqueued-receiver-com-spec{data-element=TelltaleOpArray, init-value=constant-reference=Ctrl_WSSTelltaleOpArrayValue0}, required-interface=TITelltaleStatusOutput
      rpUclHMIReadySts: queued-receiver-com-spec{data-element=MainHMIReadyStatusData, queue-length=5}, required-interface=MainHMIReadyStatus
      rp_BlinkStsArray: required-interface=TITelltaleBlinkStatusArray
        required-com-specs:
          data-element=TTBlinkStatusArray, init-value=constant-reference=Ctrl_WSSTTBlinkStatusArrayValue0
          data-element=TTdummyDataForTypes, init-value=constant-reference=Ctrl_WSSTTdummyDataForTypesValue0
      rp_CS_ComAbsRx: required-interface=if_CS_ComAbsRx
      rp_CS_MemAbs_NvMWriteStatus: required-interface=if_CS_MemAbs_NvMWriteStatus
      rp_CS_NvMExt_GetNvMExtReadAllStatus: required-interface=TI_NvMExt_GetReadAllStatus
      rp_CS_NvMExt_SleepOperations: required-interface=TI_NvMExt_SleepOperations
      rp_CS_RxCanMdl: required-interface=if_CS_ComAbsRx
      rp_CS_TmExt_Timer_Elapsed: required-interface=TI_If_TmExt_Timer_IsElapsed
      rp_CS_TmExt_Timer_Start: required-interface=TI_If_TmExt_Timer_Start
      rp_CS_TmExt_Timer_Started: required-interface=TI_If_TmExt_Timer_IsStarted
      rp_CS_TmExt_Timer_Stop: required-interface=TI_If_TmExt_Timer_Stop
      rp_HMIOdo_Type: nonqueued-receiver-com-spec{data-element=HMI_OdoType, init-value=constant-reference=Ctrl_WSSHMI_OdoTypeValue0}, required-interface=TI_SR_HMI_Odo_Type
      rp_HMIScreenMode: nonqueued-receiver-com-spec{data-element=HMIScreenMode_Status, init-value=constant-reference=Ctrl_WSSHMIScreenMode_StatusValue0}, required-interface=TI_SR_HMIScreenMode
      rp_Head_Lamp_Status: nonqueued-receiver-com-spec{data-element=Head_Lamp_st, init-value=constant-reference=Ctrl_WSSHead_Lamp_stValue0}, required-interface=TI_HeadLamp_Status
      rp_IlumDayNightStatus: nonqueued-receiver-com-spec{data-element=illumDNStatus, init-value=constant-reference=Ctrl_WSSillumDNStatusValue0}, required-interface=TI_DayNightStatus
      rp_Init_rp_Init_CWarnMsg_Core_Observer: required-interface=TI_EcumExtInit
      rp_Init_rp_Init_Ctrl_Illumination: required-interface=TI_EcumExtInit
      rp_Init_rp_Init_Ctrl_warning: required-interface=TI_EcumExtInit
      rp_Init_rp_Init_FastGaugeAdapter: required-interface=TI_EcumExtInit
      rp_Init_rp_Init_Mdl_Dim: required-interface=TI_EcumExtInit
      rp_Init_rp_Init_Mdl_Gear: required-interface=TI_EcumExtInit
      rp_Init_rp_Init_Mdl_Linear_Interpolation: required-interface=TI_EcumExtInit
      rp_Init_rp_Init_Mdl_Speed: required-interface=TI_EcumExtInit
      rp_Init_rp_Init_Mdl_Tacho: required-interface=TI_EcumExtInit
      rp_Init_rp_Init_Mdl_TurnHazard: required-interface=TI_EcumExtInit
      rp_Init_rp_Init_Mdl_wAirbag: required-interface=TI_EcumExtInit
      rp_Init_rp_Init_Mdl_wFuelLidOpen: required-interface=TI_EcumExtInit
      rp_Init_rp_Init_SlowGaugeAdapter: required-interface=TI_EcumExtInit
      rp_Init_rp_Init_View_Speed: required-interface=TI_EcumExtInit
      rp_Init_rp_Init_WarnMsg_Core_TmrSupport: required-interface=TI_EcumExtInit
      rp_Mdl_Pwmout_TC_Dbc: nonqueued-receiver-com-spec{data-element=PWMOut_TC_Dbc, init-value=constant-reference=Ctrl_WSSPWMOut_TC_DbcValue0}, required-interface=TI_SR_PWMOut_TC_Dbc
      rp_ShiftPositionDisp: nonqueued-receiver-com-spec{data-element=ShiftPositionDisplay, init-value=constant-reference=Ctrl_WSSShiftPositionDisplayValue0}, required-interface=TI_SR_ShiftPositionDisplay
      rp_Tail_Light_Status: nonqueued-receiver-com-spec{data-element=Tail_Light_st, init-value=constant-reference=Ctrl_WSSTail_Light_stValue0}, required-interface=TI_TailLight_Status
      rp_TurnHzdTurnL_Status: nonqueued-receiver-com-spec{data-element=LeftIndicatorSts, init-value=constant-reference=Ctrl_WSSLeftIndicatorStsValue0}, required-interface=TI_SR_TurnHazard_TurnL_Status
      rp_TurnHzdTurnR_Status: nonqueued-receiver-com-spec{data-element=RightIndicatorSts, init-value=constant-reference=Ctrl_WSSRightIndicatorStsValue0}, required-interface=TI_SR_TurnHazard_TurnR_Status
    behavior IB_Ctrl_WSS
      5 x operation invoked event:
        OIE_pp_SleepOperation_CtrlWSS_CancelSleepTrigByCtrlWSS_CancelSleep: start-on-event=CtrlWSS_CancelSleep, operation=pp_SleepOperation.CtrlWSS_CancelSleep
        OIE_pp_NotifySleepStatus_Ctrl_WSS_CtrlWSS_NotifyNetworkSleepTrigByCtrlWSS_NotifyNetworkSleep: start-on-event=Ctrl_WSS_CtrlWSS_NotifyNetworkSleep, operation=pp_NotifySleepStatus.CtrlWSS_NotifyNetworkSleep
        OIE_pp_SleepOperation_CtrlWSS_ReadytoSleepTrigByCtrlWSS_ReadytoSleep: start-on-event=CtrlWSS_ReadytoSleep, operation=pp_SleepOperation.CtrlWSS_ReadytoSleep
        OIE_pp_SleepOperation_CtrlWSS_RequestSleepTrigByCtrlWSS_RequestSleep: start-on-event=CtrlWSS_RequestSleep, operation=pp_SleepOperation.CtrlWSS_RequestSleep
        OIE_pp_Variant_status_Ctrl_WSS_GetVariant_StatusTrigByGetVariant_Status: start-on-event=Ctrl_WSS_GetVariant_Status, operation=pp_Variant_status.GetVariant_Status
      timing event TECtrl_WSS_Impl_MainFunction: start-on-event=Ctrl_WSS_Impl_MainFunction, period=0.01
      operation invoked event OIE_pp_CmpLibCmd_Ctrl_WSS_Impl_OnCommandTrigByImpl_OnCommand: start-on-event=Ctrl_WSS_Impl_OnCommand, operation=pp_CmpLibCmd.Impl_OnCommand
      operation invoked event OIE_pp_EarlyWakeupState_Ctrl_WSS_SWCEarlyWakeUpHandleTrigBySWCEarlyWakeUpHandle: start-on-event=Ctrl_WSS_SWCEarlyWakeUpHandle, operation=pp_EarlyWakeupState.SWCEarlyWakeUpHandle
      operation invoked event OIE_pp_AppMdl_Sleep_Ctrl_WSS_SWCSleepStatusTrigBySWCSleepStatus: start-on-event=Ctrl_WSS_SWCSleepStatus, operation=pp_AppMdl_Sleep.SWCSleepStatus
      port-api-options:
        enable-take-address=false, indirect-api=false, port=ppAccModeState
        enable-take-address=false, indirect-api=false, port=ppBaModeState
        enable-take-address=false, indirect-api=false, port=ppBaOfModeState
        enable-take-address=false, indirect-api=false, port=ppIgnModeBuzzer
        enable-take-address=false, indirect-api=false, port=ppIgnSubstate
        enable-take-address=false, indirect-api=false, port=ppIgpCANModeState
        enable-take-address=false, indirect-api=false, port=ppIgpModeState
        enable-take-address=false, indirect-api=false, port=pp_AppMdl_Sleep
        enable-take-address=false, indirect-api=false, port=pp_ClusterMode
        enable-take-address=false, indirect-api=false, port=Ctrl_WSS/pp_CmpLibCmd
        enable-take-address=false, indirect-api=false, port=pp_EarlyWakeupState
        enable-take-address=false, indirect-api=false, port=pp_HMIReady
        enable-take-address=false, indirect-api=false, port=pp_Init_ClusterMode
        enable-take-address=false, indirect-api=false, port=pp_NotifySleepStatus
        enable-take-address=false, indirect-api=false, port=pp_SleepOperation
        enable-take-address=false, indirect-api=false, port=pp_SleepStatus
        enable-take-address=false, indirect-api=false, port=pp_TFTDisplayOn
        enable-take-address=false, indirect-api=false, port=pp_TFTDisplayOnExTurn
        enable-take-address=false, indirect-api=false, port=pp_Variant_status
        enable-take-address=false, indirect-api=false, port=pp_VehicleAppMode
        enable-take-address=false, indirect-api=false, port=rpCS_EcuMExt_FuelLidStatus
        enable-take-address=false, indirect-api=false, port=rpCS_EcuMExt_HazardStatus
        enable-take-address=false, indirect-api=false, port=Ctrl_WSS/rpComMExt
        enable-take-address=false, indirect-api=false, port=Ctrl_WSS/rpIoHwAb_ADC
        enable-take-address=false, indirect-api=false, port=Ctrl_WSS/rpIoHwAb_Din
        enable-take-address=false, indirect-api=false, port=rpSRPhasedRead_Status_phase{1..3}readcompleted
        enable-take-address=false, indirect-api=false, port=rpTTStsData
        enable-take-address=false, indirect-api=false, port=Ctrl_WSS/rpTelltaleStatusOP
        enable-take-address=false, indirect-api=false, port=rpUclHMIReadySts
        enable-take-address=false, indirect-api=false, port=rp_BlinkStsArray
        enable-take-address=false, indirect-api=false, port=rp_CS_ComAbsRx
        enable-take-address=false, indirect-api=false, port=Ctrl_WSS/rp_CS_MemAbs_NvMWriteStatus
        enable-take-address=false, indirect-api=false, port=Ctrl_WSS/rp_CS_NvMExt_GetNvMExtReadAllStatus
        enable-take-address=false, indirect-api=false, port=Ctrl_WSS/rp_CS_NvMExt_SleepOperations
        enable-take-address=false, indirect-api=false, port=Ctrl_WSS/rp_CS_RxCanMdl
        enable-take-address=false, indirect-api=false, port=Ctrl_WSS/rp_CS_TmExt_Timer_Elapsed
        enable-take-address=false, indirect-api=false, port=Ctrl_WSS/rp_CS_TmExt_Timer_Start
        enable-take-address=false, indirect-api=false, port=Ctrl_WSS/rp_CS_TmExt_Timer_Started
        enable-take-address=false, indirect-api=false, port=Ctrl_WSS/rp_CS_TmExt_Timer_Stop
        enable-take-address=false, indirect-api=false, port=rp_HMIOdo_Type
        enable-take-address=false, indirect-api=false, port=Ctrl_WSS/rp_HMIScreenMode
        enable-take-address=false, indirect-api=false, port=rp_Head_Lamp_Status
        enable-take-address=false, indirect-api=false, port=Ctrl_WSS/rp_IlumDayNightStatus
        enable-take-address=false, indirect-api=false, port=rp_Init_rp_Init_CWarnMsg_Core_Observer
        enable-take-address=false, indirect-api=false, port=rp_Init_rp_Init_Ctrl_Illumination
        enable-take-address=false, indirect-api=false, port=rp_Init_rp_Init_Ctrl_warning
        enable-take-address=false, indirect-api=false, port=rp_Init_rp_Init_FastGaugeAdapter
        enable-take-address=false, indirect-api=false, port=rp_Init_rp_Init_Mdl_Dim
        enable-take-address=false, indirect-api=false, port=rp_Init_rp_Init_Mdl_Gear
        enable-take-address=false, indirect-api=false, port=rp_Init_rp_Init_Mdl_Linear_Interpolation
        enable-take-address=false, indirect-api=false, port=rp_Init_rp_Init_Mdl_Speed
        enable-take-address=false, indirect-api=false, port=rp_Init_rp_Init_Mdl_Tacho
        enable-take-address=false, indirect-api=false, port=rp_Init_rp_Init_Mdl_TurnHazard
        enable-take-address=false, indirect-api=false, port=rp_Init_rp_Init_Mdl_wAirbag
        enable-take-address=false, indirect-api=false, port=rp_Init_rp_Init_Mdl_wFuelLidOpen
        enable-take-address=false, indirect-api=false, port=rp_Init_rp_Init_SlowGaugeAdapter
        enable-take-address=false, indirect-api=false, port=rp_Init_rp_Init_View_Speed
        enable-take-address=false, indirect-api=false, port=rp_Init_rp_Init_WarnMsg_Core_TmrSupport
        enable-take-address=false, indirect-api=false, port=rp_Mdl_Pwmout_TC_Dbc
        enable-take-address=false, indirect-api=false, port=rp_ShiftPositionDisp
        enable-take-address=false, indirect-api=false, port=rp_Tail_Light_Status
        enable-take-address=false, indirect-api=false, port=rp_TurnHzdTurnL_Status
        enable-take-address=false, indirect-api=false, port=rp_TurnHzdTurnR_Status
      9 x runnable, all with can-be-invoked-concurrently=true:
        CtrlWSS_CancelSleep
        Ctrl_WSS_CtrlWSS_NotifyNetworkSleep
        CtrlWSS_ReadytoSleep
        CtrlWSS_RequestSleep
        Ctrl_WSS_GetVariant_Status
        Ctrl_WSS_Impl_MainFunction
          data-receive-point-by-arguments:
            20 x access:
              DRP_rpCS_EcuMExt_FuelLidStatus_FuelLidStatus: accessed-variable=rpCS_EcuMExt_FuelLidStatus.FuelLidStatus
              DRP_rpCS_EcuMExt_HazardStatus_HazardStatus: accessed-variable=rpCS_EcuMExt_HazardStatus.HazardStatus
              DRA_rpSRPhasedRead_Status_phase{1..3}readcompleted_PhasedRead_Status_phase{1..3}readcompleted: accessed-variable=rpSRPhasedRead_Status_phase{1..3}readcompleted.PhasedRead_Status_phase{1..3}readcompleted
              DRA_rpTTStsData_TTIndex: accessed-variable=rpTTStsData.TTIndex
              DRA_rpTTStsData_TTStatus: accessed-variable=rpTTStsData.TTStatus
              DRA_rpTelltaleStatusOP_TelltaleOpArray: accessed-variable=rpTelltaleStatusOP.TelltaleOpArray
              DRP_rpUclHMIReadySts_MainHMIReadyStatusData: accessed-variable=rpUclHMIReadySts.MainHMIReadyStatusData
              DRA_rp_BlinkStsArray_TTBlinkStatusArray: accessed-variable=rp_BlinkStsArray.TTBlinkStatusArray
              DRA_rp_BlinkStsArray_TTdummyDataForTypes: accessed-variable=rp_BlinkStsArray.TTdummyDataForTypes
              DRA_rp_HMIOdo_Type_HMI_OdoType: accessed-variable=rp_HMIOdo_Type.HMI_OdoType
              DRA_rp_HMIScreenMode_HMIScreenMode_Status: accessed-variable=rp_HMIScreenMode.HMIScreenMode_Status
              DRA_rp_Head_Lamp_Status_Head_Lamp_st: accessed-variable=rp_Head_Lamp_Status.Head_Lamp_st
              DRA_rp_IlumDayNightStatus_illumDNStatus: accessed-variable=rp_IlumDayNightStatus.illumDNStatus
              DRA_rp_Mdl_Pwmout_TC_Dbc_PWMOut_TC_Dbc: accessed-variable=rp_Mdl_Pwmout_TC_Dbc.PWMOut_TC_Dbc
              DRA_rp_ShiftPositionDisp_ShiftPositionDisplay: accessed-variable=rp_ShiftPositionDisp.ShiftPositionDisplay
              DRA_rp_Tail_Light_Status_Tail_Light_st: accessed-variable=rp_Tail_Light_Status.Tail_Light_st
              DRA_rp_TurnHzdTurnL_Status_LeftIndicatorSts: accessed-variable=rp_TurnHzdTurnL_Status.LeftIndicatorSts
              DRA_rp_TurnHzdTurnR_Status_RightIndicatorSts: accessed-variable=rp_TurnHzdTurnR_Status.RightIndicatorSts
          data-send-points:
            14 x access:
              DWA_ppAccModeState_WSSAccState: accessed-variable=ppAccModeState.WSSAccState
              DWA_ppBaModeState_WSSBaState: accessed-variable=ppBaModeState.WSSBaState
              DWA_ppBaOfModeState_WSSBaOfState: accessed-variable=ppBaOfModeState.WSSBaOfState
              DWA_ppIgnModeBuzzer_IgnitioBuznstate: accessed-variable=ppIgnModeBuzzer.IgnitioBuznstate
              DWA_ppIgnSubstate_IgnitionSubstate: accessed-variable=ppIgnSubstate.IgnitionSubstate
              DWA_ppIgpCANModeState_WSSIGPCANState: accessed-variable=ppIgpCANModeState.WSSIGPCANState
              DWA_ppIgpModeState_WSSIGPState: accessed-variable=ppIgpModeState.WSSIGPState
              DWA_pp_ClusterMode_WSSCurrentClusterMode: accessed-variable=pp_ClusterMode.WSSCurrentClusterMode
              DWA_pp_HMIReady_HMI_ReadyStatus: accessed-variable=pp_HMIReady.HMI_ReadyStatus
              DWA_pp_Init_ClusterMode_WSSCurrentClusterInitMode: accessed-variable=pp_Init_ClusterMode.WSSCurrentClusterInitMode
              DWA_pp_SleepStatus_Sleep_Status: accessed-variable=pp_SleepStatus.Sleep_Status
              DWA_pp_TFTDisplayOn_TFTDisplayOn: accessed-variable=pp_TFTDisplayOn.TFTDisplayOn
              DWA_pp_TFTDisplayOnExTurn_TFTDisplayOnExTurn: accessed-variable=pp_TFTDisplayOnExTurn.TFTDisplayOnExTurn
              DWA_pp_VehicleAppMode_WSSCurrentVehicleState: accessed-variable=pp_VehicleAppMode.WSSCurrentVehicleState
          62 x sync call, all with timeout=0.0:
            OA_rpComMExt_Get_MCAN_ERR_PIN_Status: operation=rpComMExt.Get_MCAN_ERR_PIN_Status
            OA_rpComMExt_Init: operation=rpComMExt.Init
            OA_rpComMExt_GetBusOffStatus: operation=rpComMExt.GetBusOffStatus
            OA_rpComMExt_CAN_RequestCommunication: operation=rpComMExt.CAN_RequestCommunication
            OA_rpComMExt_CAN_GetCurrentComMode: operation=rpComMExt.CAN_GetCurrentComMode
            OA_rpComMExt_CAN_ReleaseCommunication: operation=rpComMExt.CAN_ReleaseCommunication
            OA_rpComMExt_CAN_DeActivateSilentCommunication: operation=rpComMExt.CAN_DeActivateSilentCommunication
            OA_rpComMExt_CAN_CommControlSetDone: operation=rpComMExt.CAN_CommControlSetDone
            OA_rpComMExt_CAN_CommControlDeActivateTx: operation=rpComMExt.CAN_CommControlDeActivateTx
            OA_rpComMExt_CAN_CommControlDeActivateRx: operation=rpComMExt.CAN_CommControlDeActivateRx
            OA_rpComMExt_CAN_ActivateSilentCommunication: operation=rpComMExt.CAN_ActivateSilentCommunication
            OA_rpComMExt_CAN_CommControlActivateRx: operation=rpComMExt.CAN_CommControlActivateRx
            OA_rpComMExt_CAN_CommControlActivateTx: operation=rpComMExt.CAN_CommControlActivateTx
            OA_rpIoHwAb_ADC_GetAsyncRawAdc: operation=rpIoHwAb_ADC.GetAsyncRawAdc
            OA_rpIoHwAb_ADC_GetSyncRawAdc: operation=rpIoHwAb_ADC.GetSyncRawAdc
            OA_rpIoHwAb_ADC_GetProcessedAdc: operation=rpIoHwAb_ADC.GetProcessedAdc
            OA_rpIoHwAb_Din_GetAsyncRawInput: operation=rpIoHwAb_Din.GetAsyncRawInput
            OA_rpIoHwAb_Din_GetProcessedInput: operation=rpIoHwAb_Din.GetProcessedInput
            OA_rpIoHwAb_Din_GetSyncRawInput: operation=rpIoHwAb_Din.GetSyncRawInput
            OA_rpIoHwAb_Din_GetInputGroup: operation=rpIoHwAb_Din.GetInputGroup
            OA_rp_CS_ComAbsRx_RxCan_GetSignalValueU8Arr: operation=rp_CS_ComAbsRx.RxCan_GetSignalValueU8Arr
            OA_rp_CS_ComAbsRx_RxCan_SetSignalInitValue: operation=rp_CS_ComAbsRx.RxCan_SetSignalInitValue
            OA_rp_CS_ComAbsRx_RxCan_SetSignalInitValueU8Arr: operation=rp_CS_ComAbsRx.RxCan_SetSignalInitValueU8Arr
            OA_rp_CS_ComAbsRx_RxCan_SignalInvalidProcessingControl: operation=rp_CS_ComAbsRx.RxCan_SignalInvalidProcessingControl
            OA_rp_CS_ComAbsRx_RxCan_SignalMissingProcessingControl: operation=rp_CS_ComAbsRx.RxCan_SignalMissingProcessingControl
            OA_rp_CS_ComAbsRx_RxCan_SignalNRProcessingControl: operation=rp_CS_ComAbsRx.RxCan_SignalNRProcessingControl
            OA_rp_CS_ComAbsRx_RxCan_SignalGetJustRcvdStatus: operation=rp_CS_ComAbsRx.RxCan_SignalGetJustRcvdStatus
            OA_rp_CS_ComAbsRx_RxCan_SignalClearJustRcvdStatus: operation=rp_CS_ComAbsRx.RxCan_SignalClearJustRcvdStatus
            OA_rp_CS_ComAbsRx_RxCan_GetSignalValue: operation=rp_CS_ComAbsRx.RxCan_GetSignalValue
            OA_rp_CS_MemAbs_NvMWriteStatus_NvmWriteStatus: operation=rp_CS_MemAbs_NvMWriteStatus.NvmWriteStatus
            OA_rp_CS_NvMExt_GetNvMExtReadAllStatus_NvmExt_GetNvMReadAllStatus: operation=rp_CS_NvMExt_GetNvMExtReadAllStatus.NvmExt_GetNvMReadAllStatus
            OA_rp_CS_NvMExt_SleepOperations_NvMExt_ReadytoSleep: operation=rp_CS_NvMExt_SleepOperations.NvMExt_ReadytoSleep
            OA_rp_CS_NvMExt_SleepOperations_NvMExt_RequestSleep: operation=rp_CS_NvMExt_SleepOperations.NvMExt_RequestSleep
            OA_rp_CS_NvMExt_SleepOperations_NvMExt_CancelSleep: operation=rp_CS_NvMExt_SleepOperations.NvMExt_CancelSleep
            OA_rp_CS_RxCanMdl_RxCan_GetSignalValueU8Arr: operation=rp_CS_RxCanMdl.RxCan_GetSignalValueU8Arr
            OA_rp_CS_RxCanMdl_RxCan_SetSignalInitValue: operation=rp_CS_RxCanMdl.RxCan_SetSignalInitValue
            OA_rp_CS_RxCanMdl_RxCan_SetSignalInitValueU8Arr: operation=rp_CS_RxCanMdl.RxCan_SetSignalInitValueU8Arr
            OA_rp_CS_RxCanMdl_RxCan_SignalInvalidProcessingControl: operation=rp_CS_RxCanMdl.RxCan_SignalInvalidProcessingControl
            OA_rp_CS_RxCanMdl_RxCan_SignalMissingProcessingControl: operation=rp_CS_RxCanMdl.RxCan_SignalMissingProcessingControl
            OA_rp_CS_RxCanMdl_RxCan_SignalNRProcessingControl: operation=rp_CS_RxCanMdl.RxCan_SignalNRProcessingControl
            OA_rp_CS_RxCanMdl_RxCan_SignalGetJustRcvdStatus: operation=rp_CS_RxCanMdl.RxCan_SignalGetJustRcvdStatus
            OA_rp_CS_RxCanMdl_RxCan_SignalClearJustRcvdStatus: operation=rp_CS_RxCanMdl.RxCan_SignalClearJustRcvdStatus
            OA_rp_CS_RxCanMdl_RxCan_GetSignalValue: operation=rp_CS_RxCanMdl.RxCan_GetSignalValue
            OA_rp_CS_TmExt_Timer_Elapsed_Timer_IsElapsed: operation=rp_CS_TmExt_Timer_Elapsed.Timer_IsElapsed
            OA_rp_CS_TmExt_Timer_Start_Timer_Start: operation=rp_CS_TmExt_Timer_Start.Timer_Start
            OA_rp_CS_TmExt_Timer_Started_Timer_IsStarted: operation=rp_CS_TmExt_Timer_Started.Timer_IsStarted
            OA_rp_CS_TmExt_Timer_Stop_Timer_Stop: operation=rp_CS_TmExt_Timer_Stop.Timer_Stop
            OA_rp_Init_rp_Init_CWarnMsg_Core_Observer_Init: operation=rp_Init_rp_Init_CWarnMsg_Core_Observer.Init
            OA_rp_Init_rp_Init_Ctrl_Illumination_Init: operation=rp_Init_rp_Init_Ctrl_Illumination.Init
            OA_rp_Init_rp_Init_Ctrl_warning_Init: operation=rp_Init_rp_Init_Ctrl_warning.Init
            OA_rp_Init_rp_Init_FastGaugeAdapter_Init: operation=rp_Init_rp_Init_FastGaugeAdapter.Init
            OA_rp_Init_rp_Init_Mdl_Dim_Init: operation=rp_Init_rp_Init_Mdl_Dim.Init
            OA_rp_Init_rp_Init_Mdl_Gear_Init: operation=rp_Init_rp_Init_Mdl_Gear.Init
            OA_rp_Init_rp_Init_Mdl_Linear_Interpolation_Init: operation=rp_Init_rp_Init_Mdl_Linear_Interpolation.Init
            OA_rp_Init_rp_Init_Mdl_Speed_Init: operation=rp_Init_rp_Init_Mdl_Speed.Init
            OA_rp_Init_rp_Init_Mdl_Tacho_Init: operation=rp_Init_rp_Init_Mdl_Tacho.Init
            OA_rp_Init_rp_Init_Mdl_TurnHazard_Init: operation=rp_Init_rp_Init_Mdl_TurnHazard.Init
            OA_rp_Init_rp_Init_Mdl_wAirbag_Init: operation=rp_Init_rp_Init_Mdl_wAirbag.Init
            OA_rp_Init_rp_Init_Mdl_wFuelLidOpen_Init: operation=rp_Init_rp_Init_Mdl_wFuelLidOpen.Init
            OA_rp_Init_rp_Init_SlowGaugeAdapter_Init: operation=rp_Init_rp_Init_SlowGaugeAdapter.Init
            OA_rp_Init_rp_Init_View_Speed_Init: operation=rp_Init_rp_Init_View_Speed.Init
            OA_rp_Init_rp_Init_WarnMsg_Core_TmrSupport_Init: operation=rp_Init_rp_Init_WarnMsg_Core_TmrSupport.Init
        Ctrl_WSS_Impl_OnCommand
        Ctrl_WSS_SWCEarlyWakeUpHandle
        Ctrl_WSS_SWCSleepStatus
  31 x constant specification:
    Ctrl_WSSWSSAccStateValue0: value-spec=Ctrl_WSSWSSAccStateValue0:0
    Ctrl_WSSWSSBaStateValue0: value-spec=Ctrl_WSSWSSBaStateValue0:0
    Ctrl_WSSWSSBaOfStateValue0: value-spec=Ctrl_WSSWSSBaOfStateValue0:0
    Ctrl_WSSIgnitioBuznstateValue0: value-spec=Ctrl_WSSIgnitioBuznstateValue0:0
    Ctrl_WSSIgnitionSubstateValue0: value-spec=Ctrl_WSSIgnitionSubstateValue0:0
    Ctrl_WSSWSSIGPCANStateValue0: value-spec=Ctrl_WSSWSSIGPCANStateValue0:0
    Ctrl_WSSWSSIGPStateValue0: value-spec=Ctrl_WSSWSSIGPStateValue0:0
    Ctrl_WSSWSSCurrentClusterModeValue0: value-spec=Ctrl_WSSWSSCurrentClusterModeValue0:0
    Ctrl_WSSHMI_ReadyStatusValue0: value-spec=Ctrl_WSSHMI_ReadyStatusValue0:0
    Ctrl_WSSWSSCurrentClusterInitModeValue0: value-spec=0
    Ctrl_WSSSleep_StatusValue0: value-spec=Ctrl_WSSSleep_StatusValue0:0
    Ctrl_WSSTFTDisplayOnValue0: value-spec=Ctrl_WSSTFTDisplayOnValue0:0
    Ctrl_WSSTFTDisplayOnExTurnValue0: value-spec=Ctrl_WSSTFTDisplayOnExTurnValue0:0
    Ctrl_WSSWSSCurrentVehicleStateValue0: value-spec=Ctrl_WSSWSSCurrentVehicleStateValue0:0
    Ctrl_WSSPhasedRead_Status_phase{1..3}readcompletedValue0: value-spec=Ctrl_WSSPhasedRead_Status_phase{1..3}readcompletedValue0:false
    Ctrl_WSSTTIndexValue0: value-spec=Ctrl_WSSTTIndexValue0:0
    Ctrl_WSSTTStatusValue0: value-spec=Ctrl_WSSTTStatusValue0:0
    Ctrl_WSSTelltaleOpArrayValue0: value-spec=Ctrl_WSSTelltaleOpArrayValue0:[Ctrl_WSSTelltaleOpArray0Value:0, Ctrl_WSSTelltaleOpArray1Value:0, Ctrl_WSSTelltaleOpArray2Value:0, Ctrl_WSSTelltaleOpArray3Value:0, Ctrl_WSSTelltaleOpArray4Value:0, Ctrl_WSSTelltaleOpArray5Value:0, Ctrl_WSSTelltaleOpArray6Value:0, Ctrl_WSSTelltaleOpArray7Value:0, Ctrl_WSSTelltaleOpArray8Value:0, Ctrl_WSSTelltaleOpArray9Value:0, Ctrl_WSSTelltaleOpArray10Value:0, Ctrl_WSSTelltaleOpArray11Value:0, Ctrl_WSSTelltaleOpArray12Value:0, Ctrl_WSSTelltaleOpArray13Value:0, Ctrl_WSSTelltaleOpArray14Value:0, Ctrl_WSSTelltaleOpArray15Value:0, Ctrl_WSSTelltaleOpArray16Value:0, Ctrl_WSSTelltaleOpArray17Value:0, Ctrl_WSSTelltaleOpArray18Value:0, Ctrl_WSSTelltaleOpArray19Value:0, Ctrl_WSSTelltaleOpArray20Value:0, Ctrl_WSSTelltaleOpArray21Value:0, Ctrl_WSSTelltaleOpArray22Value:0, Ctrl_WSSTelltaleOpArray23Value:0, Ctrl_WSSTelltaleOpArray24Value:0, Ctrl_WSSTelltaleOpArray25Value:0, Ctrl_WSSTelltaleOpArray26Value:0, Ctrl_WSSTelltaleOpArray27Value:0, Ctrl_WSSTelltaleOpArray28Value:0, Ctrl_WSSTelltaleOpArray29Value:0, Ctrl_WSSTelltaleOpArray30Value:0, Ctrl_WSSTelltaleOpArray31Value:0, Ctrl_WSSTelltaleOpArray32Value:0, Ctrl_WSSTelltaleOpArray33Value:0, Ctrl_WSSTelltaleOpArray34Value:0, Ctrl_WSSTelltaleOpArray35Value:0, Ctrl_WSSTelltaleOpArray36Value:0, Ctrl_WSSTelltaleOpArray37Value:0, Ctrl_WSSTelltaleOpArray38Value:0, Ctrl_WSSTelltaleOpArray39Value:0, Ctrl_WSSTelltaleOpArray40Value:0, Ctrl_WSSTelltaleOpArray41Value:0, Ctrl_WSSTelltaleOpArray42Value:0, Ctrl_WSSTelltaleOpArray43Value:0, Ctrl_WSSTelltaleOpArray44Value:0, Ctrl_WSSTelltaleOpArray45Value:0, Ctrl_WSSTelltaleOpArray46Value:0, Ctrl_WSSTelltaleOpArray47Value:0, Ctrl_WSSTelltaleOpArray48Value:0, Ctrl_WSSTelltaleOpArray49Value:0, Ctrl_WSSTelltaleOpArray50Value:0, Ctrl_WSSTelltaleOpArray51Value:0, Ctrl_WSSTelltaleOpArray52Value:0, Ctrl_WSSTelltaleOpArray53Value:0, Ctrl_WSSTelltaleOpArray54Value:0, Ctrl_WSSTelltaleOpArray55Value:0, Ctrl_WSSTelltaleOpArray56Value:0, Ctrl_WSSTelltaleOpArray57Value:0, Ctrl_WSSTelltaleOpArray58Value:0, Ctrl_WSSTelltaleOpArray59Value:0, Ctrl_WSSTelltaleOpArray60Value:0, Ctrl_WSSTelltaleOpArray61Value:0, Ctrl_WSSTelltaleOpArray62Value:0, Ctrl_WSSTelltaleOpArray63Value:0, Ctrl_WSSTelltaleOpArray64Value:0, Ctrl_WSSTelltaleOpArray65Value:0, Ctrl_WSSTelltaleOpArray66Value:0, Ctrl_WSSTelltaleOpArray67Value:0, Ctrl_WSSTelltaleOpArray68Value:0, Ctrl_WSSTelltaleOpArray69Value:0, Ctrl_WSSTelltaleOpArray70Value:0, Ctrl_WSSTelltaleOpArray71Value:0, Ctrl_WSSTelltaleOpArray72Value:0, Ctrl_WSSTelltaleOpArray73Value:0, Ctrl_WSSTelltaleOpArray74Value:0, Ctrl_WSSTelltaleOpArray75Value:0, Ctrl_WSSTelltaleOpArray76Value:0, Ctrl_WSSTelltaleOpArray77Value:0, Ctrl_WSSTelltaleOpArray78Value:0, Ctrl_WSSTelltaleOpArray79Value:0, Ctrl_WSSTelltaleOpArray80Value:0, Ctrl_WSSTelltaleOpArray81Value:0, Ctrl_WSSTelltaleOpArray82Value:0, Ctrl_WSSTelltaleOpArray83Value:0, Ctrl_WSSTelltaleOpArray84Value:0, Ctrl_WSSTelltaleOpArray85Value:0, Ctrl_WSSTelltaleOpArray86Value:0, Ctrl_WSSTelltaleOpArray87Value:0, Ctrl_WSSTelltaleOpArray88Value:0, Ctrl_WSSTelltaleOpArray89Value:0, Ctrl_WSSTelltaleOpArray90Value:0, Ctrl_WSSTelltaleOpArray91Value:0]
    Ctrl_WSSTTBlinkStatusArrayValue0: value-spec=Ctrl_WSSTTBlinkStatusArrayValue0:[Ctrl_WSSTTBlinkStatusArray0Value:0, Ctrl_WSSTTBlinkStatusArray1Value:0, Ctrl_WSSTTBlinkStatusArray2Value:0, Ctrl_WSSTTBlinkStatusArray3Value:0, Ctrl_WSSTTBlinkStatusArray4Value:0, Ctrl_WSSTTBlinkStatusArray5Value:0, Ctrl_WSSTTBlinkStatusArray6Value:0, Ctrl_WSSTTBlinkStatusArray7Value:0, Ctrl_WSSTTBlinkStatusArray8Value:0, Ctrl_WSSTTBlinkStatusArray9Value:0, Ctrl_WSSTTBlinkStatusArray10Value:0, Ctrl_WSSTTBlinkStatusArray11Value:0, Ctrl_WSSTTBlinkStatusArray12Value:0, Ctrl_WSSTTBlinkStatusArray13Value:0, Ctrl_WSSTTBlinkStatusArray14Value:0, Ctrl_WSSTTBlinkStatusArray15Value:0]
    Ctrl_WSSTTdummyDataForTypesValue0: value-spec=Ctrl_WSSTTdummyDataForTypesValue0:0
    Ctrl_WSSHMI_OdoTypeValue0: value-spec=Ctrl_WSSHMI_OdoTypeValue0:0
    Ctrl_WSSHMIScreenMode_StatusValue0: value-spec=Ctrl_WSSHMIScreenMode_StatusValue0:0
    Ctrl_WSSHead_Lamp_stValue0: value-spec=Ctrl_WSSHead_Lamp_stValue0:0
    Ctrl_WSSillumDNStatusValue0: value-spec=Ctrl_WSSillumDNStatusValue0:0
    Ctrl_WSSPWMOut_TC_DbcValue0: value-spec=Ctrl_WSSPWMOut_TC_DbcValue0:0
    Ctrl_WSSShiftPositionDisplayValue0: value-spec=Ctrl_WSSShiftPositionDisplayValue0:0
    Ctrl_WSSTail_Light_stValue0: value-spec=Ctrl_WSSTail_Light_stValue0:0
    Ctrl_WSSLeftIndicatorStsValue0: value-spec=Ctrl_WSSLeftIndicatorStsValue0:0
    Ctrl_WSSRightIndicatorStsValue0: value-spec=Ctrl_WSSRightIndicatorStsValue0:0
  swc implementation IMPL_Ctrl_WSS: programming-language=C, behavior=IB_Ctrl_WSS
    code-descriptors:
      code CodeDescriptor
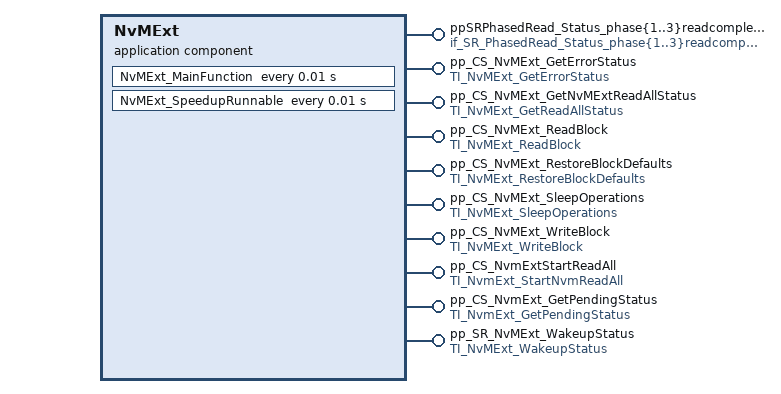
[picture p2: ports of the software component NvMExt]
  application sw component type NvMExt
    12 x provide port:
      ppSRPhasedRead_Status_phase{1..3}readcompleted: nonqueued-sender-com-spec{data-element=PhasedRead_Status_phase{1..3}readcompleted, uses-end-to-end-protection=0, init-value=constant-reference=NvMExtPhasedRead_Status_phase{1..3}readcompletedValue0}, provided-interface=if_SR_PhasedRead_Status_phase{1..3}readcompleted
      pp_CS_NvMExt_GetErrorStatus: server-com-spec{operation=NvMExt_GetErrorStatus, queue-length=1}, provided-interface=TI_NvMExt_GetErrorStatus
      pp_CS_NvMExt_GetNvMExtReadAllStatus: server-com-spec{operation=NvmExt_GetNvMReadAllStatus, queue-length=1}, provided-interface=TI_NvMExt_GetReadAllStatus
      pp_CS_NvMExt_ReadBlock: server-com-spec{operation=NvMExt_ReadBlock, queue-length=1}, provided-interface=TI_NvMExt_ReadBlock
      pp_CS_NvMExt_RestoreBlockDefaults: server-com-spec{operation=NvMExt_RestoreBlockDefaults, queue-length=1}, provided-interface=TI_NvMExt_RestoreBlockDefaults
      pp_CS_NvMExt_SleepOperations: provided-interface=TI_NvMExt_SleepOperations
        provided-com-specs:
          operation=NvMExt_CancelSleep, queue-length=1
          operation=NvMExt_ReadytoSleep, queue-length=1
          operation=NvMExt_RequestSleep, queue-length=1
      pp_CS_NvMExt_WriteBlock: server-com-spec{operation=NvMExt_WriteBlock, queue-length=1}, provided-interface=TI_NvMExt_WriteBlock
      pp_CS_NvmExtStartReadAll: server-com-spec{operation=NvMExt_ReadAll, queue-length=1}, provided-interface=TI_NvmExt_StartNvmReadAll
      pp_CS_NvmExt_GetPendingStatus: server-com-spec{operation=NvMExt_GetPendingStatus, queue-length=1}, provided-interface=TI_NvmExt_GetPendingStatus
      pp_SR_NvMExt_WakeupStatus: nonqueued-sender-com-spec{data-element=WakeupFlag, uses-end-to-end-protection=0, init-value=constant-reference=NvMExtWakeupFlagValue0}, provided-interface=TI_NvMExt_WakeupStatus
    behavior IB_NvMExt
      timing event TENvMExt_MainFunction: start-on-event=NvMExt_MainFunction, period=0.01
      10 x operation invoked event:
        OIE_pp_CS_NvMExt_SleepOperations_NvMExt_CancelSleepTrigByNvMExt_CancelSleep: start-on-event=NvMExt_CancelSleep, operation=pp_CS_NvMExt_SleepOperations.NvMExt_CancelSleep
        OIE_pp_CS_NvMExt_GetErrorStatus_NvMExt_GetErrorStatusTrigByNvMExt_GetErrorStatus: start-on-event=NvMExt_GetErrorStatus, operation=pp_CS_NvMExt_GetErrorStatus.NvMExt_GetErrorStatus
        OIE_pp_CS_NvmExt_GetPendingStatus_NvMExt_GetPendingStatusTrigByNvMExt_GetPendingStatus: start-on-event=NvMExt_GetPendingStatus, operation=pp_CS_NvmExt_GetPendingStatus.NvMExt_GetPendingStatus
        OIE_pp_CS_NvmExtStartReadAll_NvMExt_ReadAllTrigByNvMExt_ReadAll: start-on-event=NvMExt_ReadAll, operation=pp_CS_NvmExtStartReadAll.NvMExt_ReadAll
        OIE_pp_CS_NvMExt_ReadBlock_NvMExt_ReadBlockTrigByNvMExt_ReadBlock: start-on-event=NvMExt_ReadBlock, operation=pp_CS_NvMExt_ReadBlock.NvMExt_ReadBlock
        OIE_pp_CS_NvMExt_SleepOperations_NvMExt_ReadytoSleepTrigByNvMExt_ReadytoSleep: start-on-event=NvMExt_ReadytoSleep, operation=pp_CS_NvMExt_SleepOperations.NvMExt_ReadytoSleep
        OIE_pp_CS_NvMExt_SleepOperations_NvMExt_RequestSleepTrigByNvMExt_RequestSleep: start-on-event=NvMExt_RequestSleep, operation=pp_CS_NvMExt_SleepOperations.NvMExt_RequestSleep
        OIE_pp_CS_NvMExt_RestoreBlockDefaults_NvMExt_RestoreBlockDefaultsTrigByNvMExt_RestoreBlockDefaults: start-on-event=NvMExt_RestoreBlockDefaults, operation=pp_CS_NvMExt_RestoreBlockDefaults.NvMExt_RestoreBlockDefaults
        OIE_pp_CS_NvMExt_WriteBlock_NvMExt_WriteBlockTrigByNvMExt_WriteBlock: start-on-event=NvMExt_WriteBlock, operation=pp_CS_NvMExt_WriteBlock.NvMExt_WriteBlock
        OIE_pp_CS_NvMExt_GetNvMExtReadAllStatus_NvmExt_GetNvMReadAllStatusTrigByNvmExt_GetNvMReadAllStatus: start-on-event=NvmExt_GetNvMReadAllStatus, operation=pp_CS_NvMExt_GetNvMExtReadAllStatus.NvmExt_GetNvMReadAllStatus
      timing event TENvMExt_SpeedupRunnable: start-on-event=NvMExt_SpeedupRunnable, period=0.01
      port-api-options:
        enable-take-address=false, indirect-api=false, port=ppSRPhasedRead_Status_phase{1..3}readcompleted
        enable-take-address=false, indirect-api=false, port=pp_CS_NvMExt_GetErrorStatus
        enable-take-address=false, indirect-api=false, port=pp_CS_NvMExt_GetNvMExtReadAllStatus
        enable-take-address=false, indirect-api=false, port=pp_CS_NvMExt_ReadBlock
        enable-take-address=false, indirect-api=false, port=pp_CS_NvMExt_RestoreBlockDefaults
        enable-take-address=false, indirect-api=false, port=pp_CS_NvMExt_SleepOperations
        enable-take-address=false, indirect-api=false, port=pp_CS_NvMExt_WriteBlock
        enable-take-address=false, indirect-api=false, port=pp_CS_NvmExtStartReadAll
        enable-take-address=false, indirect-api=false, port=pp_CS_NvmExt_GetPendingStatus
        enable-take-address=false, indirect-api=false, port=pp_SR_NvMExt_WakeupStatus
      12 x runnable, all with can-be-invoked-concurrently=true:
        NvMExt_MainFunction
          data-send-points:
            4 x access:
              DWA_ppSRPhasedRead_Status_phase{1..3}readcompleted_PhasedRead_Status_phase{1..3}readcompleted: accessed-variable=ppSRPhasedRead_Status_phase{1..3}readcompleted.PhasedRead_Status_phase{1..3}readcompleted
              DWA_pp_SR_NvMExt_WakeupStatus_WakeupFlag: accessed-variable=pp_SR_NvMExt_WakeupStatus.WakeupFlag
        NvMExt_CancelSleep
        NvMExt_GetErrorStatus
          data-send-points:
            4 x access:
              DWA_ppSRPhasedRead_Status_phase{1..3}readcompleted_PhasedRead_Status_phase{1..3}readcompleted: accessed-variable=ppSRPhasedRead_Status_phase{1..3}readcompleted.PhasedRead_Status_phase{1..3}readcompleted
              DWA_pp_SR_NvMExt_WakeupStatus_WakeupFlag: accessed-variable=pp_SR_NvMExt_WakeupStatus.WakeupFlag
        NvMExt_GetPendingStatus
        NvMExt_ReadAll
        NvMExt_ReadBlock
          data-send-points:
            4 x access:
              DWA_ppSRPhasedRead_Status_phase{1..3}readcompleted_PhasedRead_Status_phase{1..3}readcompleted: accessed-variable=ppSRPhasedRead_Status_phase{1..3}readcompleted.PhasedRead_Status_phase{1..3}readcompleted
              DWA_pp_SR_NvMExt_WakeupStatus_WakeupFlag: accessed-variable=pp_SR_NvMExt_WakeupStatus.WakeupFlag
        NvMExt_ReadytoSleep
        NvMExt_RequestSleep
        NvMExt_RestoreBlockDefaults
          data-send-points:
            4 x access:
              DWA_ppSRPhasedRead_Status_phase{1..3}readcompleted_PhasedRead_Status_phase{1..3}readcompleted: accessed-variable=ppSRPhasedRead_Status_phase{1..3}readcompleted.PhasedRead_Status_phase{1..3}readcompleted
              DWA_pp_SR_NvMExt_WakeupStatus_WakeupFlag: accessed-variable=pp_SR_NvMExt_WakeupStatus.WakeupFlag
        NvMExt_WriteBlock
          data-send-points:
            4 x access:
              DWA_ppSRPhasedRead_Status_phase{1..3}readcompleted_PhasedRead_Status_phase{1..3}readcompleted: accessed-variable=ppSRPhasedRead_Status_phase{1..3}readcompleted.PhasedRead_Status_phase{1..3}readcompleted
              DWA_pp_SR_NvMExt_WakeupStatus_WakeupFlag: accessed-variable=pp_SR_NvMExt_WakeupStatus.WakeupFlag
        NvmExt_GetNvMReadAllStatus
        NvMExt_SpeedupRunnable
  4 x constant specification:
    NvMExtPhasedRead_Status_phase{1..3}readcompletedValue0: value-spec=NvMExtPhasedRead_Status_phase{1..3}readcompletedValue0:false
    NvMExtWakeupFlagValue0: value-spec=NvMExtWakeupFlagValue0:false
  swc implementation IMPL_NvMExt: programming-language=C, behavior=IB_NvMExt
    code-descriptors:
      code CodeDescriptor
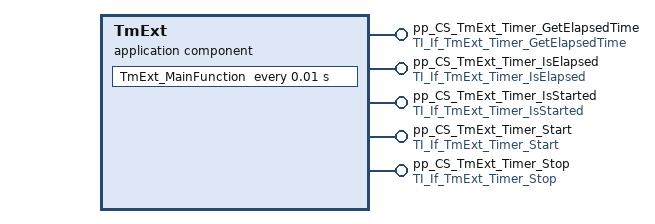
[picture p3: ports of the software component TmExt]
  application sw component type TmExt
    5 x provide port:
      pp_CS_TmExt_Timer_GetElapsedTime: server-com-spec{operation=Timer_GetElapsedTime, queue-length=1}, provided-interface=TI_If_TmExt_Timer_GetElapsedTime
      pp_CS_TmExt_Timer_IsElapsed: server-com-spec{operation=Timer_IsElapsed, queue-length=1}, provided-interface=TI_If_TmExt_Timer_IsElapsed
      pp_CS_TmExt_Timer_IsStarted: server-com-spec{operation=Timer_IsStarted, queue-length=1}, provided-interface=TI_If_TmExt_Timer_IsStarted
      pp_CS_TmExt_Timer_Start: server-com-spec{operation=Timer_Start, queue-length=1}, provided-interface=TI_If_TmExt_Timer_Start
      pp_CS_TmExt_Timer_Stop: server-com-spec{operation=Timer_Stop, queue-length=1}, provided-interface=TI_If_TmExt_Timer_Stop
    behavior IB_TmExt
      timing event TETmExt_MainFunction: start-on-event=TmExt_MainFunction, period=0.01
      5 x operation invoked event:
        OIE_pp_CS_TmExt_Timer_GetElapsedTime_TmExt_Timer_GetElapsedTimeTrigByTimer_GetElapsedTime: start-on-event=TmExt_Timer_GetElapsedTime, operation=pp_CS_TmExt_Timer_GetElapsedTime.Timer_GetElapsedTime
        OIE_pp_CS_TmExt_Timer_IsElapsed_TmExt_Timer_IsElapsedTrigByTimer_IsElapsed: start-on-event=TmExt_Timer_IsElapsed, operation=pp_CS_TmExt_Timer_IsElapsed.Timer_IsElapsed
        OIE_pp_CS_TmExt_Timer_IsStarted_TmExt_Timer_IsStartedTrigByTimer_IsStarted: start-on-event=TmExt_Timer_IsStarted, operation=pp_CS_TmExt_Timer_IsStarted.Timer_IsStarted
        OIE_pp_CS_TmExt_Timer_Start_TmExt_Timer_StartTrigByTimer_Start: start-on-event=TmExt_Timer_Start, operation=pp_CS_TmExt_Timer_Start.Timer_Start
        OIE_pp_CS_TmExt_Timer_Stop_TmExt_Timer_StopTrigByTimer_Stop: start-on-event=TmExt_Timer_Stop, operation=pp_CS_TmExt_Timer_Stop.Timer_Stop
      port-api-options:
        enable-take-address=false, indirect-api=false, port=pp_CS_TmExt_Timer_GetElapsedTime
        enable-take-address=false, indirect-api=false, port=pp_CS_TmExt_Timer_IsElapsed
        enable-take-address=false, indirect-api=false, port=pp_CS_TmExt_Timer_IsStarted
        enable-take-address=false, indirect-api=false, port=pp_CS_TmExt_Timer_Start
        enable-take-address=false, indirect-api=false, port=pp_CS_TmExt_Timer_Stop
      6 x runnable, all with can-be-invoked-concurrently=true:
        TmExt_MainFunction
        TmExt_Timer_GetElapsedTime
        TmExt_Timer_IsElapsed
        TmExt_Timer_IsStarted
        TmExt_Timer_Start
        TmExt_Timer_Stop
  swc implementation IMPL_TmExt: programming-language=C, behavior=IB_TmExt
    code-descriptors:
      code CodeDescriptor
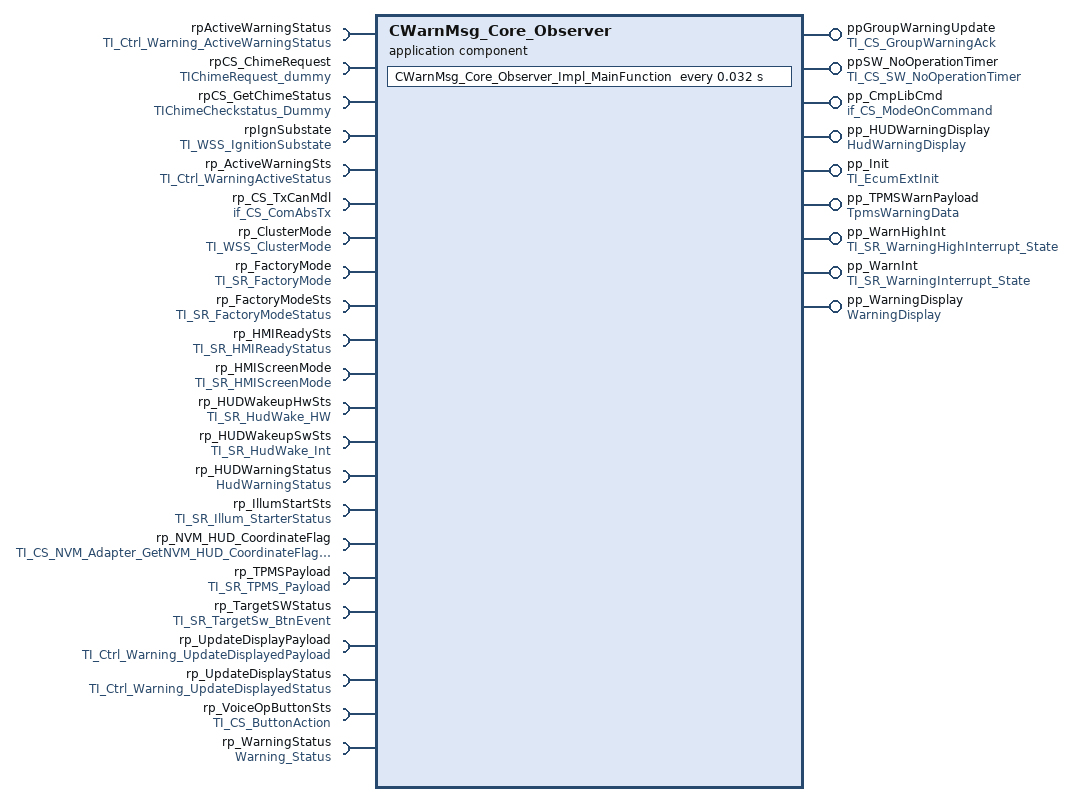
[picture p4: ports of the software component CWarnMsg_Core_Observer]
  application sw component type CWarnMsg_Core_Observer
    9 x provide port:
      ppGroupWarningUpdate: server-com-spec{operation=GroupWrnAck, queue-length=1}, provided-interface=TI_CS_GroupWarningAck
      ppSW_NoOperationTimer: server-com-spec{operation=SW_NoOperationTimer, queue-length=1}, provided-interface=TI_CS_SW_NoOperationTimer
      pp_CmpLibCmd: server-com-spec{operation=Impl_OnCommand, queue-length=1}, provided-interface=if_CS_ModeOnCommand
      pp_HUDWarningDisplay: nonqueued-sender-com-spec{data-element=HudWarningDisplayData, init-value=constant-reference=CWarnMsg_Core_ObserverHudWarningDisplayDataValue0}, provided-interface=HudWarningDisplay
      pp_Init: server-com-spec{operation=TI_EcumExtInit/Init, queue-length=1}, provided-interface=TI_EcumExtInit
      pp_TPMSWarnPayload: nonqueued-sender-com-spec{data-element=TpmsWarningDataData, init-value=constant-reference=CWarnMsg_Core_ObserverTpmsWarningDataDataValue0}, provided-interface=TpmsWarningData
      pp_WarnHighInt: nonqueued-sender-com-spec{data-element=WarningHighInterrupt_State, init-value=constant-reference=CWarnMsg_Core_ObserverWarningHighInterrupt_StateValue0}, provided-interface=TI_SR_WarningHighInterrupt_State
      pp_WarnInt: nonqueued-sender-com-spec{data-element=WarningInterrupt_State, init-value=constant-reference=CWarnMsg_Core_ObserverWarningInterrupt_StateValue0}, provided-interface=TI_SR_WarningInterrupt_State
      pp_WarningDisplay: nonqueued-sender-com-spec{data-element=WarningDisplayData, init-value=constant-reference=CWarnMsg_Core_ObserverWarningDisplayDataValue0}, provided-interface=WarningDisplay
    22 x require port:
      rpActiveWarningStatus: required-interface=TI_Ctrl_Warning_ActiveWarningStatus
      rpCS_ChimeRequest: nonqueued-receiver-com-spec{data-element=Chime_Request, init-value=constant-reference=CWarnMsg_Core_ObserverChime_RequestValue0}, required-interface=TIChimeRequest_dummy
      rpCS_GetChimeStatus: nonqueued-receiver-com-spec{data-element=Chime_Status, init-value=constant-reference=CWarnMsg_Core_ObserverChime_StatusValue0}, required-interface=TIChimeCheckstatus_Dummy
      rpIgnSubstate: nonqueued-receiver-com-spec{data-element=IgnitionSubstate, init-value=constant-reference=CWarnMsg_Core_ObserverIgnitionSubstateValue0}, required-interface=TI_WSS_IgnitionSubstate
      rp_ActiveWarningSts: required-interface=TI_Ctrl_WarningActiveStatus
      rp_CS_TxCanMdl: required-interface=if_CS_ComAbsTx
      rp_ClusterMode: nonqueued-receiver-com-spec{data-element=WSSCurrentClusterMode, init-value=constant-reference=CWarnMsg_Core_ObserverWSSCurrentClusterModeValue0}, required-interface=TI_WSS_ClusterMode
      rp_FactoryMode: nonqueued-receiver-com-spec{data-element=FactoryMode, init-value=constant-reference=CWarnMsg_Core_ObserverFactoryModeValue0}, required-interface=TI_SR_FactoryMode
      rp_FactoryModeSts: nonqueued-receiver-com-spec{data-element=FactoryModeStatus, init-value=constant-reference=CWarnMsg_Core_ObserverFactoryModeStatusValue0}, required-interface=TI_SR_FactoryModeStatus
      rp_HMIReadySts: nonqueued-receiver-com-spec{data-element=HMI_ReadyStatus, init-value=constant-reference=CWarnMsg_Core_ObserverHMI_ReadyStatusValue0}, required-interface=TI_SR_HMIReadyStatus
      rp_HMIScreenMode: nonqueued-receiver-com-spec{data-element=HMIScreenMode_Status, init-value=constant-reference=CWarnMsg_Core_ObserverHMIScreenMode_StatusValue0}, required-interface=TI_SR_HMIScreenMode
      rp_HUDWakeupHwSts: nonqueued-receiver-com-spec{data-element=WakeType_Hw, init-value=constant-reference=CWarnMsg_Core_ObserverWakeType_HwValue0}, required-interface=TI_SR_HudWake_HW
      rp_HUDWakeupSwSts: nonqueued-receiver-com-spec{data-element=WakeType_Int, init-value=constant-reference=CWarnMsg_Core_ObserverWakeType_IntValue0}, required-interface=TI_SR_HudWake_Int
      rp_HUDWarningStatus: nonqueued-receiver-com-spec{data-element=HudWarningStatusData, init-value=constant-reference=CWarnMsg_Core_ObserverHudWarningStatusDataValue0}, required-interface=HudWarningStatus
      rp_IllumStartSts: nonqueued-receiver-com-spec{data-element=StarterStatus_Out, init-value=constant-reference=CWarnMsg_Core_ObserverStarterStatus_OutValue0}, required-interface=TI_SR_Illum_StarterStatus
      rp_NVM_HUD_CoordinateFlag: nonqueued-receiver-com-spec{data-element=NvmData, init-value=constant-reference=CWarnMsg_Core_ObserverNvmDataValue0}, required-interface=TI_CS_NVM_Adapter_GetNVM_HUD_CoordinateFlag_Dummy
      rp_TPMSPayload: nonqueued-receiver-com-spec{data-element=Tpms_Payload, init-value=constant-reference=CWarnMsg_Core_ObserverTpms_PayloadValue0}, required-interface=TI_SR_TPMS_Payload
      rp_TargetSWStatus: nonqueued-receiver-com-spec{data-element=TargetSw, init-value=constant-reference=CWarnMsg_Core_ObserverTargetSwValue0}, required-interface=TI_SR_TargetSw_BtnEvent
      rp_UpdateDisplayPayload: required-interface=TI_Ctrl_Warning_UpdateDisplayedPayload
      rp_UpdateDisplayStatus: required-interface=TI_Ctrl_Warning_UpdateDisplayedStatus
      rp_VoiceOpButtonSts: required-interface=TI_CS_ButtonAction
      rp_WarningStatus: nonqueued-receiver-com-spec{data-element=WarningStatusData, init-value=constant-reference=CWarnMsg_Core_ObserverWarningStatusDataValue0}, required-interface=Warning_Status
    behavior IB_CWarnMsg_Core_Observer
      operation invoked event OIE_ppGroupWarningUpdate_CWarnMsg_Core_Observer_GroupWrnAckTrigByGroupWrnAck: start-on-event=CWarnMsg_Core_Observer_GroupWrnAck, operation=ppGroupWarningUpdate.GroupWrnAck
      timing event TECWarnMsg_Core_Observer_Impl_MainFunction: start-on-event=CWarnMsg_Core_Observer_Impl_MainFunction, period=0.032
      operation invoked event OIE_pp_CmpLibCmd_CWarnMsg_Core_Observer_Impl_OnCommandTrigByImpl_OnCommand: start-on-event=CWarnMsg_Core_Observer_Impl_OnCommand, operation=pp_CmpLibCmd.Impl_OnCommand
      operation invoked event OIE_pp_Init_CWarnMsg_Core_Observer_InitTrigByInit: start-on-event=CWarnMsg_Core_Observer_Init, operation=pp_Init.Init
      data received event DREOnDre_UCL_HudWarnStatusTrigByHudWarningStatusData: start-on-event=OnDre_UCL_HudWarnStatus, data=rp_HUDWarningStatus.HudWarningStatusData
      data received event DREOnDre_UCL_WarnStatusTrigByWarningStatusData: start-on-event=OnDre_UCL_WarnStatus, data=rp_WarningStatus.WarningStatusData
      operation invoked event OIE_ppSW_NoOperationTimer_CWarnMsg_Core_Observer_SW_NoOperationTimerTrigBySW_NoOperationTimer: start-on-event=CWarnMsg_Core_Observer_SW_NoOperationTimer, operation=ppSW_NoOperationTimer.SW_NoOperationTimer
      port-api-options:
        enable-take-address=false, indirect-api=false, port=ppGroupWarningUpdate
        enable-take-address=false, indirect-api=false, port=ppSW_NoOperationTimer
        enable-take-address=false, indirect-api=false, port=CWarnMsg_Core_Observer/pp_CmpLibCmd
        enable-take-address=false, indirect-api=false, port=pp_HUDWarningDisplay
        enable-take-address=false, indirect-api=false, port=CWarnMsg_Core_Observer/pp_Init
        enable-take-address=false, indirect-api=false, port=pp_TPMSWarnPayload
        enable-take-address=false, indirect-api=false, port=pp_WarnHighInt
        enable-take-address=false, indirect-api=false, port=pp_WarnInt
        enable-take-address=false, indirect-api=false, port=pp_WarningDisplay
        enable-take-address=false, indirect-api=false, port=rpActiveWarningStatus
        enable-take-address=false, indirect-api=false, port=CWarnMsg_Core_Observer/rpCS_ChimeRequest
        enable-take-address=false, indirect-api=false, port=rpCS_GetChimeStatus
        enable-take-address=false, indirect-api=false, port=CWarnMsg_Core_Observer/rpIgnSubstate
        enable-take-address=false, indirect-api=false, port=rp_ActiveWarningSts
        enable-take-address=false, indirect-api=false, port=CWarnMsg_Core_Observer/rp_CS_TxCanMdl
        enable-take-address=false, indirect-api=false, port=CWarnMsg_Core_Observer/rp_ClusterMode
        enable-take-address=false, indirect-api=false, port=rp_FactoryMode
        enable-take-address=false, indirect-api=false, port=rp_FactoryModeSts
        enable-take-address=false, indirect-api=false, port=rp_HMIReadySts
        enable-take-address=false, indirect-api=false, port=CWarnMsg_Core_Observer/rp_HMIScreenMode
        enable-take-address=false, indirect-api=false, port=rp_HUDWakeupHwSts
        enable-take-address=false, indirect-api=false, port=rp_HUDWakeupSwSts
        enable-take-address=false, indirect-api=false, port=rp_HUDWarningStatus
        enable-take-address=false, indirect-api=false, port=rp_IllumStartSts
        enable-take-address=false, indirect-api=false, port=rp_NVM_HUD_CoordinateFlag
        enable-take-address=false, indirect-api=false, port=rp_TPMSPayload
        enable-take-address=false, indirect-api=false, port=rp_TargetSWStatus
        enable-take-address=false, indirect-api=false, port=rp_UpdateDisplayPayload
        enable-take-address=false, indirect-api=false, port=rp_UpdateDisplayStatus
        enable-take-address=false, indirect-api=false, port=rp_VoiceOpButtonSts
        enable-take-address=false, indirect-api=false, port=rp_WarningStatus
      7 x runnable, all with can-be-invoked-concurrently=true:
        CWarnMsg_Core_Observer_GroupWrnAck
        CWarnMsg_Core_Observer_Impl_MainFunction
          data-receive-point-by-arguments:
            16 x access:
              DRA_rpCS_ChimeRequest_Chime_Request: accessed-variable=rpCS_ChimeRequest.Chime_Request
              DRA_rpCS_GetChimeStatus_Chime_Status: accessed-variable=rpCS_GetChimeStatus.Chime_Status
              DRA_rpIgnSubstate_IgnitionSubstate: accessed-variable=rpIgnSubstate.IgnitionSubstate
              DRA_rp_ClusterMode_WSSCurrentClusterMode: accessed-variable=rp_ClusterMode.WSSCurrentClusterMode
              DRA_rp_FactoryMode_FactoryMode: accessed-variable=rp_FactoryMode.FactoryMode
              DRA_rp_FactoryModeSts_FactoryModeStatus: accessed-variable=rp_FactoryModeSts.FactoryModeStatus
              DRA_rp_HMIReadySts_HMI_ReadyStatus: accessed-variable=rp_HMIReadySts.HMI_ReadyStatus
              DRA_rp_HMIScreenMode_HMIScreenMode_Status: accessed-variable=rp_HMIScreenMode.HMIScreenMode_Status
              DRA_rp_HUDWakeupHwSts_WakeType_Hw: accessed-variable=rp_HUDWakeupHwSts.WakeType_Hw
              DRA_rp_HUDWakeupSwSts_WakeType_Int: accessed-variable=rp_HUDWakeupSwSts.WakeType_Int
              DRA_rp_HUDWarningStatus_HudWarningStatusData: accessed-variable=rp_HUDWarningStatus.HudWarningStatusData
              DRA_rp_IllumStartSts_StarterStatus_Out: accessed-variable=rp_IllumStartSts.StarterStatus_Out
              DRA_rp_NVM_HUD_CoordinateFlag_NvmData: accessed-variable=rp_NVM_HUD_CoordinateFlag.NvmData
              DRA_rp_TPMSPayload_Tpms_Payload: accessed-variable=rp_TPMSPayload.Tpms_Payload
              DRA_rp_TargetSWStatus_TargetSw: accessed-variable=rp_TargetSWStatus.TargetSw
              DRA_rp_WarningStatus_WarningStatusData: accessed-variable=rp_WarningStatus.WarningStatusData
          data-send-points:
            5 x access:
              DWA_pp_HUDWarningDisplay_HudWarningDisplayData: accessed-variable=pp_HUDWarningDisplay.HudWarningDisplayData
              DWA_pp_TPMSWarnPayload_TpmsWarningDataData: accessed-variable=pp_TPMSWarnPayload.TpmsWarningDataData
              DWA_pp_WarnHighInt_WarningHighInterrupt_State: accessed-variable=pp_WarnHighInt.WarningHighInterrupt_State
              DWA_pp_WarnInt_WarningInterrupt_State: accessed-variable=pp_WarnInt.WarningInterrupt_State
              DWA_pp_WarningDisplay_WarningDisplayData: accessed-variable=pp_WarningDisplay.WarningDisplayData
          10 x sync call, all with timeout=0.0:
            OA_rpActiveWarningStatus_GetActiveWarningStatus: operation=rpActiveWarningStatus.GetActiveWarningStatus
            OA_rp_ActiveWarningSts_GetWarningActiveStatus: operation=rp_ActiveWarningSts.GetWarningActiveStatus
            OA_rp_CS_TxCanMdl_TxCan_ClearCanSignalTxConfirmation: operation=rp_CS_TxCanMdl.TxCan_ClearCanSignalTxConfirmation
            OA_rp_CS_TxCanMdl_TxCan_GetCanSignalTxConfirmation: operation=rp_CS_TxCanMdl.TxCan_GetCanSignalTxConfirmation
            OA_rp_CS_TxCanMdl_TxCan_SetSignalFromRetentionBuffer: operation=rp_CS_TxCanMdl.TxCan_SetSignalFromRetentionBuffer
            OA_rp_CS_TxCanMdl_TxCan_SetSignalValue: operation=rp_CS_TxCanMdl.TxCan_SetSignalValue
            OA_rp_CS_TxCanMdl_TxCan_SetSignalValueU8Arr: operation=rp_CS_TxCanMdl.TxCan_SetSignalValueU8Arr
            OA_rp_UpdateDisplayPayload_SetWarningDisplayedPayload: operation=rp_UpdateDisplayPayload.SetWarningDisplayedPayload
            OA_rp_UpdateDisplayStatus_SetWarningDisplayedStatus: operation=rp_UpdateDisplayStatus.SetWarningDisplayedStatus
            OA_rp_VoiceOpButtonSts_GetButtonStatus: operation=rp_VoiceOpButtonSts.GetButtonStatus
        CWarnMsg_Core_Observer_Impl_OnCommand
        CWarnMsg_Core_Observer_Init
        OnDre_UCL_HudWarnStatus
          data-receive-point-by-arguments:
            16 x access:
              DRA_rpCS_ChimeRequest_Chime_Request: accessed-variable=rpCS_ChimeRequest.Chime_Request
              DRA_rpCS_GetChimeStatus_Chime_Status: accessed-variable=rpCS_GetChimeStatus.Chime_Status
              DRA_rpIgnSubstate_IgnitionSubstate: accessed-variable=rpIgnSubstate.IgnitionSubstate
              DRA_rp_ClusterMode_WSSCurrentClusterMode: accessed-variable=rp_ClusterMode.WSSCurrentClusterMode
              DRA_rp_FactoryMode_FactoryMode: accessed-variable=rp_FactoryMode.FactoryMode
              DRA_rp_FactoryModeSts_FactoryModeStatus: accessed-variable=rp_FactoryModeSts.FactoryModeStatus
              DRA_rp_HMIReadySts_HMI_ReadyStatus: accessed-variable=rp_HMIReadySts.HMI_ReadyStatus
              DRA_rp_HMIScreenMode_HMIScreenMode_Status: accessed-variable=rp_HMIScreenMode.HMIScreenMode_Status
              DRA_rp_HUDWakeupHwSts_WakeType_Hw: accessed-variable=rp_HUDWakeupHwSts.WakeType_Hw
              DRA_rp_HUDWakeupSwSts_WakeType_Int: accessed-variable=rp_HUDWakeupSwSts.WakeType_Int
              DRA_rp_HUDWarningStatus_HudWarningStatusData: accessed-variable=rp_HUDWarningStatus.HudWarningStatusData
              DRA_rp_IllumStartSts_StarterStatus_Out: accessed-variable=rp_IllumStartSts.StarterStatus_Out
              DRA_rp_NVM_HUD_CoordinateFlag_NvmData: accessed-variable=rp_NVM_HUD_CoordinateFlag.NvmData
              DRA_rp_TPMSPayload_Tpms_Payload: accessed-variable=rp_TPMSPayload.Tpms_Payload
              DRA_rp_TargetSWStatus_TargetSw: accessed-variable=rp_TargetSWStatus.TargetSw
              DRA_rp_WarningStatus_WarningStatusData: accessed-variable=rp_WarningStatus.WarningStatusData
          data-send-points:
            5 x access:
              DWA_pp_HUDWarningDisplay_HudWarningDisplayData: accessed-variable=pp_HUDWarningDisplay.HudWarningDisplayData
              DWA_pp_TPMSWarnPayload_TpmsWarningDataData: accessed-variable=pp_TPMSWarnPayload.TpmsWarningDataData
              DWA_pp_WarnHighInt_WarningHighInterrupt_State: accessed-variable=pp_WarnHighInt.WarningHighInterrupt_State
              DWA_pp_WarnInt_WarningInterrupt_State: accessed-variable=pp_WarnInt.WarningInterrupt_State
              DWA_pp_WarningDisplay_WarningDisplayData: accessed-variable=pp_WarningDisplay.WarningDisplayData
          10 x sync call, all with timeout=0.0:
            OA_rpActiveWarningStatus_GetActiveWarningStatus: operation=rpActiveWarningStatus.GetActiveWarningStatus
            OA_rp_ActiveWarningSts_GetWarningActiveStatus: operation=rp_ActiveWarningSts.GetWarningActiveStatus
            OA_rp_CS_TxCanMdl_TxCan_ClearCanSignalTxConfirmation: operation=rp_CS_TxCanMdl.TxCan_ClearCanSignalTxConfirmation
            OA_rp_CS_TxCanMdl_TxCan_GetCanSignalTxConfirmation: operation=rp_CS_TxCanMdl.TxCan_GetCanSignalTxConfirmation
            OA_rp_CS_TxCanMdl_TxCan_SetSignalFromRetentionBuffer: operation=rp_CS_TxCanMdl.TxCan_SetSignalFromRetentionBuffer
            OA_rp_CS_TxCanMdl_TxCan_SetSignalValue: operation=rp_CS_TxCanMdl.TxCan_SetSignalValue
            OA_rp_CS_TxCanMdl_TxCan_SetSignalValueU8Arr: operation=rp_CS_TxCanMdl.TxCan_SetSignalValueU8Arr
            OA_rp_UpdateDisplayPayload_SetWarningDisplayedPayload: operation=rp_UpdateDisplayPayload.SetWarningDisplayedPayload
            OA_rp_UpdateDisplayStatus_SetWarningDisplayedStatus: operation=rp_UpdateDisplayStatus.SetWarningDisplayedStatus
            OA_rp_VoiceOpButtonSts_GetButtonStatus: operation=rp_VoiceOpButtonSts.GetButtonStatus
        OnDre_UCL_WarnStatus
          data-receive-point-by-arguments:
            16 x access:
              DRA_rpCS_ChimeRequest_Chime_Request: accessed-variable=rpCS_ChimeRequest.Chime_Request
              DRA_rpCS_GetChimeStatus_Chime_Status: accessed-variable=rpCS_GetChimeStatus.Chime_Status
              DRA_rpIgnSubstate_IgnitionSubstate: accessed-variable=rpIgnSubstate.IgnitionSubstate
              DRA_rp_ClusterMode_WSSCurrentClusterMode: accessed-variable=rp_ClusterMode.WSSCurrentClusterMode
              DRA_rp_FactoryMode_FactoryMode: accessed-variable=rp_FactoryMode.FactoryMode
              DRA_rp_FactoryModeSts_FactoryModeStatus: accessed-variable=rp_FactoryModeSts.FactoryModeStatus
              DRA_rp_HMIReadySts_HMI_ReadyStatus: accessed-variable=rp_HMIReadySts.HMI_ReadyStatus
              DRA_rp_HMIScreenMode_HMIScreenMode_Status: accessed-variable=rp_HMIScreenMode.HMIScreenMode_Status
              DRA_rp_HUDWakeupHwSts_WakeType_Hw: accessed-variable=rp_HUDWakeupHwSts.WakeType_Hw
              DRA_rp_HUDWakeupSwSts_WakeType_Int: accessed-variable=rp_HUDWakeupSwSts.WakeType_Int
              DRA_rp_HUDWarningStatus_HudWarningStatusData: accessed-variable=rp_HUDWarningStatus.HudWarningStatusData
              DRA_rp_IllumStartSts_StarterStatus_Out: accessed-variable=rp_IllumStartSts.StarterStatus_Out
              DRA_rp_NVM_HUD_CoordinateFlag_NvmData: accessed-variable=rp_NVM_HUD_CoordinateFlag.NvmData
              DRA_rp_TPMSPayload_Tpms_Payload: accessed-variable=rp_TPMSPayload.Tpms_Payload
              DRA_rp_TargetSWStatus_TargetSw: accessed-variable=rp_TargetSWStatus.TargetSw
              DRA_rp_WarningStatus_WarningStatusData: accessed-variable=rp_WarningStatus.WarningStatusData
          data-send-points:
            5 x access:
              DWA_pp_HUDWarningDisplay_HudWarningDisplayData: accessed-variable=pp_HUDWarningDisplay.HudWarningDisplayData
              DWA_pp_TPMSWarnPayload_TpmsWarningDataData: accessed-variable=pp_TPMSWarnPayload.TpmsWarningDataData
              DWA_pp_WarnHighInt_WarningHighInterrupt_State: accessed-variable=pp_WarnHighInt.WarningHighInterrupt_State
              DWA_pp_WarnInt_WarningInterrupt_State: accessed-variable=pp_WarnInt.WarningInterrupt_State
              DWA_pp_WarningDisplay_WarningDisplayData: accessed-variable=pp_WarningDisplay.WarningDisplayData
          10 x sync call, all with timeout=0.0:
            OA_rpActiveWarningStatus_GetActiveWarningStatus: operation=rpActiveWarningStatus.GetActiveWarningStatus
            OA_rp_ActiveWarningSts_GetWarningActiveStatus: operation=rp_ActiveWarningSts.GetWarningActiveStatus
            OA_rp_CS_TxCanMdl_TxCan_ClearCanSignalTxConfirmation: operation=rp_CS_TxCanMdl.TxCan_ClearCanSignalTxConfirmation
            OA_rp_CS_TxCanMdl_TxCan_GetCanSignalTxConfirmation: operation=rp_CS_TxCanMdl.TxCan_GetCanSignalTxConfirmation
            OA_rp_CS_TxCanMdl_TxCan_SetSignalFromRetentionBuffer: operation=rp_CS_TxCanMdl.TxCan_SetSignalFromRetentionBuffer
            OA_rp_CS_TxCanMdl_TxCan_SetSignalValue: operation=rp_CS_TxCanMdl.TxCan_SetSignalValue
            OA_rp_CS_TxCanMdl_TxCan_SetSignalValueU8Arr: operation=rp_CS_TxCanMdl.TxCan_SetSignalValueU8Arr
            OA_rp_UpdateDisplayPayload_SetWarningDisplayedPayload: operation=rp_UpdateDisplayPayload.SetWarningDisplayedPayload
            OA_rp_UpdateDisplayStatus_SetWarningDisplayedStatus: operation=rp_UpdateDisplayStatus.SetWarningDisplayedStatus
            OA_rp_VoiceOpButtonSts_GetButtonStatus: operation=rp_VoiceOpButtonSts.GetButtonStatus
        CWarnMsg_Core_Observer_SW_NoOperationTimer
          data-receive-point-by-arguments:
            16 x access:
              DRA_rpCS_ChimeRequest_Chime_Request: accessed-variable=rpCS_ChimeRequest.Chime_Request
              DRA_rpCS_GetChimeStatus_Chime_Status: accessed-variable=rpCS_GetChimeStatus.Chime_Status
              DRA_rpIgnSubstate_IgnitionSubstate: accessed-variable=rpIgnSubstate.IgnitionSubstate
              DRA_rp_ClusterMode_WSSCurrentClusterMode: accessed-variable=rp_ClusterMode.WSSCurrentClusterMode
              DRA_rp_FactoryMode_FactoryMode: accessed-variable=rp_FactoryMode.FactoryMode
              DRA_rp_FactoryModeSts_FactoryModeStatus: accessed-variable=rp_FactoryModeSts.FactoryModeStatus
              DRA_rp_HMIReadySts_HMI_ReadyStatus: accessed-variable=rp_HMIReadySts.HMI_ReadyStatus
              DRA_rp_HMIScreenMode_HMIScreenMode_Status: accessed-variable=rp_HMIScreenMode.HMIScreenMode_Status
              DRA_rp_HUDWakeupHwSts_WakeType_Hw: accessed-variable=rp_HUDWakeupHwSts.WakeType_Hw
              DRA_rp_HUDWakeupSwSts_WakeType_Int: accessed-variable=rp_HUDWakeupSwSts.WakeType_Int
              DRA_rp_HUDWarningStatus_HudWarningStatusData: accessed-variable=rp_HUDWarningStatus.HudWarningStatusData
              DRA_rp_IllumStartSts_StarterStatus_Out: accessed-variable=rp_IllumStartSts.StarterStatus_Out
              DRA_rp_NVM_HUD_CoordinateFlag_NvmData: accessed-variable=rp_NVM_HUD_CoordinateFlag.NvmData
              DRA_rp_TPMSPayload_Tpms_Payload: accessed-variable=rp_TPMSPayload.Tpms_Payload
              DRA_rp_TargetSWStatus_TargetSw: accessed-variable=rp_TargetSWStatus.TargetSw
              DRA_rp_WarningStatus_WarningStatusData: accessed-variable=rp_WarningStatus.WarningStatusData
          data-send-points:
            5 x access:
              DWA_pp_HUDWarningDisplay_HudWarningDisplayData: accessed-variable=pp_HUDWarningDisplay.HudWarningDisplayData
              DWA_pp_TPMSWarnPayload_TpmsWarningDataData: accessed-variable=pp_TPMSWarnPayload.TpmsWarningDataData
              DWA_pp_WarnHighInt_WarningHighInterrupt_State: accessed-variable=pp_WarnHighInt.WarningHighInterrupt_State
              DWA_pp_WarnInt_WarningInterrupt_State: accessed-variable=pp_WarnInt.WarningInterrupt_State
              DWA_pp_WarningDisplay_WarningDisplayData: accessed-variable=pp_WarningDisplay.WarningDisplayData
          10 x sync call, all with timeout=0.0:
            OA_rpActiveWarningStatus_GetActiveWarningStatus: operation=rpActiveWarningStatus.GetActiveWarningStatus
            OA_rp_ActiveWarningSts_GetWarningActiveStatus: operation=rp_ActiveWarningSts.GetWarningActiveStatus
            OA_rp_CS_TxCanMdl_TxCan_ClearCanSignalTxConfirmation: operation=rp_CS_TxCanMdl.TxCan_ClearCanSignalTxConfirmation
            OA_rp_CS_TxCanMdl_TxCan_GetCanSignalTxConfirmation: operation=rp_CS_TxCanMdl.TxCan_GetCanSignalTxConfirmation
            OA_rp_CS_TxCanMdl_TxCan_SetSignalFromRetentionBuffer: operation=rp_CS_TxCanMdl.TxCan_SetSignalFromRetentionBuffer
            OA_rp_CS_TxCanMdl_TxCan_SetSignalValue: operation=rp_CS_TxCanMdl.TxCan_SetSignalValue
            OA_rp_CS_TxCanMdl_TxCan_SetSignalValueU8Arr: operation=rp_CS_TxCanMdl.TxCan_SetSignalValueU8Arr
            OA_rp_UpdateDisplayPayload_SetWarningDisplayedPayload: operation=rp_UpdateDisplayPayload.SetWarningDisplayedPayload
            OA_rp_UpdateDisplayStatus_SetWarningDisplayedStatus: operation=rp_UpdateDisplayStatus.SetWarningDisplayedStatus
            OA_rp_VoiceOpButtonSts_GetButtonStatus: operation=rp_VoiceOpButtonSts.GetButtonStatus
  21 x constant specification:
    CWarnMsg_Core_ObserverHudWarningDisplayDataValue0: value-spec={short-label=CWarnMsg_Core_ObserverHudWarningDisplayDataValue0, fields=[CWarnMsg_Core_ObserverHudWarningDisplayDataValue_0:0, CWarnMsg_Core_ObserverHudWarningDisplayDataValue_1:0, CWarnMsg_Core_ObserverHudWarningDisplayDataValue_2:[CWarnMsg_Core_ObserverdynData0Value:0, CWarnMsg_Core_ObserverdynData1Value:0, CWarnMsg_Core_ObserverdynData2Value:0, CWarnMsg_Core_ObserverdynData3Value:0, CWarnMsg_Core_ObserverdynData4Value:0, CWarnMsg_Core_ObserverdynData5Value:0, CWarnMsg_Core_ObserverdynData6Value:0, CWarnMsg_Core_ObserverdynData7Value:0]]}
    CWarnMsg_Core_ObserverTpmsWarningDataDataValue0: value-spec={short-label=CWarnMsg_Core_ObserverTpmsWarningDataDataValue0, fields=CWarnMsg_Core_ObserverTpmsWarningDataDataValue_0:[CWarnMsg_Core_ObservertpmsWarndata0Value:0, CWarnMsg_Core_ObservertpmsWarndata1Value:0, CWarnMsg_Core_ObservertpmsWarndata2Value:0, CWarnMsg_Core_ObservertpmsWarndata3Value:0, CWarnMsg_Core_ObservertpmsWarndata4Value:0]}
    CWarnMsg_Core_ObserverWarningHighInterrupt_StateValue0: value-spec=CWarnMsg_Core_ObserverWarningHighInterrupt_StateValue0:0
    CWarnMsg_Core_ObserverWarningInterrupt_StateValue0: value-spec=CWarnMsg_Core_ObserverWarningInterrupt_StateValue0:0
    CWarnMsg_Core_ObserverWarningDisplayDataValue0: value-spec={short-label=CWarnMsg_Core_ObserverWarningDisplayDataValue0, fields=[CWarnMsg_Core_ObserverWarningDisplayDataValue_0:0, CWarnMsg_Core_ObserverWarningDisplayDataValue_1:0, CWarnMsg_Core_ObserverWarningDisplayDataValue_2:[CWarnMsg_Core_ObserverdynData0Value:0, CWarnMsg_Core_ObserverdynData1Value:0, CWarnMsg_Core_ObserverdynData2Value:0, CWarnMsg_Core_ObserverdynData3Value:0, CWarnMsg_Core_ObserverdynData4Value:0, CWarnMsg_Core_ObserverdynData5Value:0, CWarnMsg_Core_ObserverdynData6Value:0, CWarnMsg_Core_ObserverdynData7Value:0]]}
    CWarnMsg_Core_ObserverChime_RequestValue0: value-spec=CWarnMsg_Core_ObserverChime_RequestValue0:0
    CWarnMsg_Core_ObserverChime_StatusValue0: value-spec=CWarnMsg_Core_ObserverChime_StatusValue0:0
    CWarnMsg_Core_ObserverIgnitionSubstateValue0: value-spec=CWarnMsg_Core_ObserverIgnitionSubstateValue0:0
    CWarnMsg_Core_ObserverWSSCurrentClusterModeValue0: value-spec=CWarnMsg_Core_ObserverWSSCurrentClusterModeValue0:0
    CWarnMsg_Core_ObserverFactoryModeValue0: value-spec=CWarnMsg_Core_ObserverFactoryModeValue0:0
    CWarnMsg_Core_ObserverFactoryModeStatusValue0: value-spec=CWarnMsg_Core_ObserverFactoryModeStatusValue0:0
    CWarnMsg_Core_ObserverHMI_ReadyStatusValue0: value-spec=CWarnMsg_Core_ObserverHMI_ReadyStatusValue0:0
    CWarnMsg_Core_ObserverHMIScreenMode_StatusValue0: value-spec=CWarnMsg_Core_ObserverHMIScreenMode_StatusValue0:0
    CWarnMsg_Core_ObserverWakeType_HwValue0: value-spec=CWarnMsg_Core_ObserverWakeType_HwValue0:0
    CWarnMsg_Core_ObserverWakeType_IntValue0: value-spec=CWarnMsg_Core_ObserverWakeType_IntValue0:0
    CWarnMsg_Core_ObserverHudWarningStatusDataValue0: value-spec={short-label=CWarnMsg_Core_ObserverHudWarningStatusDataValue0, fields=[CWarnMsg_Core_ObserverHudWarningStatusDataValue_0:0, CWarnMsg_Core_ObserverHudWarningStatusDataValue_1:0, CWarnMsg_Core_ObserverHudWarningStatusDataValue_2:[CWarnMsg_Core_ObserverdynData0Value:0, CWarnMsg_Core_ObserverdynData1Value:0, CWarnMsg_Core_ObserverdynData2Value:0, CWarnMsg_Core_ObserverdynData3Value:0, CWarnMsg_Core_ObserverdynData4Value:0, CWarnMsg_Core_ObserverdynData5Value:0, CWarnMsg_Core_ObserverdynData6Value:0, CWarnMsg_Core_ObserverdynData7Value:0, CWarnMsg_Core_ObserverdynData8Value:0, CWarnMsg_Core_ObserverdynData9Value:0]]}
    CWarnMsg_Core_ObserverStarterStatus_OutValue0: value-spec=CWarnMsg_Core_ObserverStarterStatus_OutValue0:0
    CWarnMsg_Core_ObserverNvmDataValue0: value-spec=CWarnMsg_Core_ObserverNvmDataValue0:0
    CWarnMsg_Core_ObserverTpms_PayloadValue0: value-spec=CWarnMsg_Core_ObserverTpms_PayloadValue0:[CWarnMsg_Core_ObserverTpms_Payload0Value:0, CWarnMsg_Core_ObserverTpms_Payload1Value:0, CWarnMsg_Core_ObserverTpms_Payload2Value:0, CWarnMsg_Core_ObserverTpms_Payload3Value:0, CWarnMsg_Core_ObserverTpms_Payload4Value:0]
    CWarnMsg_Core_ObserverTargetSwValue0: value-spec=CWarnMsg_Core_ObserverTargetSwValue0:0
    CWarnMsg_Core_ObserverWarningStatusDataValue0: value-spec={short-label=CWarnMsg_Core_ObserverWarningStatusDataValue0, fields=[CWarnMsg_Core_ObserverWarningStatusDataValue_0:0, CWarnMsg_Core_ObserverWarningStatusDataValue_1:0, CWarnMsg_Core_ObserverWarningStatusDataValue_2:[CWarnMsg_Core_ObserverdynData0Value:0, CWarnMsg_Core_ObserverdynData1Value:0, CWarnMsg_Core_ObserverdynData2Value:0, CWarnMsg_Core_ObserverdynData3Value:0, CWarnMsg_Core_ObserverdynData4Value:0, CWarnMsg_Core_ObserverdynData5Value:0, CWarnMsg_Core_ObserverdynData6Value:0, CWarnMsg_Core_ObserverdynData7Value:0, CWarnMsg_Core_ObserverdynData8Value:0, CWarnMsg_Core_ObserverdynData9Value:0]]}
  swc implementation IMPL_CWarnMsg_Core_Observer: programming-language=C, behavior=IB_CWarnMsg_Core_Observer
    code-descriptors:
      code CodeDescriptor
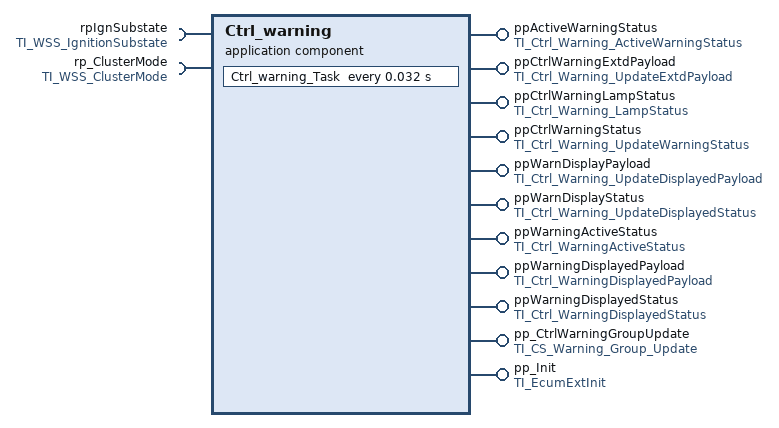
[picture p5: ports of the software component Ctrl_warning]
  application sw component type Ctrl_warning
    11 x provide port:
      ppActiveWarningStatus: server-com-spec{operation=GetActiveWarningStatus, queue-length=1}, provided-interface=TI_Ctrl_Warning_ActiveWarningStatus
      ppCtrlWarningExtdPayload: server-com-spec{operation=UpdateExtdPayload, queue-length=1}, provided-interface=TI_Ctrl_Warning_UpdateExtdPayload
      ppCtrlWarningLampStatus: provided-interface=TI_Ctrl_Warning_LampStatus
        provided-com-specs:
          operation=Get_Red_MasterLamp_Status, queue-length=1
          operation=Get_Yellow_MasterLamp_Status, queue-length=1
      ppCtrlWarningStatus: server-com-spec{operation=UpdateWarningStatus, queue-length=1}, provided-interface=TI_Ctrl_Warning_UpdateWarningStatus
      ppWarnDisplayPayload: server-com-spec{operation=SetWarningDisplayedPayload, queue-length=1}, provided-interface=TI_Ctrl_Warning_UpdateDisplayedPayload
      ppWarnDisplayStatus: server-com-spec{operation=SetWarningDisplayedStatus, queue-length=1}, provided-interface=TI_Ctrl_Warning_UpdateDisplayedStatus
      ppWarningActiveStatus: server-com-spec{operation=GetWarningActiveStatus, queue-length=1}, provided-interface=TI_Ctrl_WarningActiveStatus
      ppWarningDisplayedPayload: server-com-spec{operation=GetWarningDisplayedPayload, queue-length=1}, provided-interface=TI_Ctrl_WarningDisplayedPayload
      ppWarningDisplayedStatus: server-com-spec{operation=GetWarningDisplayedStatus, queue-length=1}, provided-interface=TI_Ctrl_WarningDisplayedStatus
      pp_CtrlWarningGroupUpdate: server-com-spec{operation=Warning_Group_update, queue-length=1}, provided-interface=TI_CS_Warning_Group_Update
      pp_Init: server-com-spec{operation=TI_EcumExtInit/Init, queue-length=1}, provided-interface=TI_EcumExtInit
    require port rpIgnSubstate: nonqueued-receiver-com-spec{data-element=IgnitionSubstate, init-value=constant-reference=Ctrl_warningIgnitionSubstateValue0}, required-interface=TI_WSS_IgnitionSubstate
    require port rp_ClusterMode: nonqueued-receiver-com-spec{data-element=WSSCurrentClusterMode, init-value=constant-reference=Ctrl_warningWSSCurrentClusterModeValue0}, required-interface=TI_WSS_ClusterMode
    behavior IB_Ctrl_warning
      9 x operation invoked event:
        OIE_ppActiveWarningStatus_Ctrl_warning_GetActiveWarningStatusTrigByGetActiveWarningStatus: start-on-event=Ctrl_warning_GetActiveWarningStatus, operation=ppActiveWarningStatus.GetActiveWarningStatus
        OIE_ppWarningActiveStatus_Ctrl_warning_GetWarningActiveStatusTrigByGetWarningActiveStatus: start-on-event=Ctrl_warning_GetWarningActiveStatus, operation=ppWarningActiveStatus.GetWarningActiveStatus
        OIE_ppWarningDisplayedPayload_Ctrl_warning_GetWarningDisplayedPayloadTrigByGetWarningDisplayedPayload: start-on-event=Ctrl_warning_GetWarningDisplayedPayload, operation=ppWarningDisplayedPayload.GetWarningDisplayedPayload
        OIE_ppWarningDisplayedStatus_Ctrl_warning_GetWarningDisplayedStatusTrigByGetWarningDisplayedStatus: start-on-event=Ctrl_warning_GetWarningDisplayedStatus, operation=ppWarningDisplayedStatus.GetWarningDisplayedStatus
        OIE_ppCtrlWarningLampStatus_Ctrl_warning_Get_Red_MasterLamp_StatusTrigByGet_Red_MasterLamp_Status: start-on-event=Ctrl_warning_Get_Red_MasterLamp_Status, operation=ppCtrlWarningLampStatus.Get_Red_MasterLamp_Status
        OIE_ppCtrlWarningLampStatus_Ctrl_warning_Get_Yellow_MasterLamp_StatusTrigByGet_Yellow_MasterLamp_Status: start-on-event=Ctrl_warning_Get_Yellow_MasterLamp_Status, operation=ppCtrlWarningLampStatus.Get_Yellow_MasterLamp_Status
        OIE_pp_Init_Ctrl_warning_InitTrigByInit: start-on-event=Ctrl_warning_Init, operation=pp_Init.Init
        OIE_ppWarnDisplayPayload_Ctrl_warning_SetWarningDisplayedPayloadTrigBySetWarningDisplayedPayload: start-on-event=Ctrl_warning_SetWarningDisplayedPayload, operation=ppWarnDisplayPayload.SetWarningDisplayedPayload
        OIE_ppWarnDisplayStatus_Ctrl_warning_SetWarningDisplayedStatusTrigBySetWarningDisplayedStatus: start-on-event=Ctrl_warning_SetWarningDisplayedStatus, operation=ppWarnDisplayStatus.SetWarningDisplayedStatus
      timing event TECtrl_warning_Task: start-on-event=Ctrl_warning_Task, period=0.032
      operation invoked event OIE_ppCtrlWarningExtdPayload_Ctrl_warning_UpdateExtdPayloadTrigByUpdateExtdPayload: start-on-event=Ctrl_warning_UpdateExtdPayload, operation=ppCtrlWarningExtdPayload.UpdateExtdPayload
      operation invoked event OIE_ppCtrlWarningStatus_Ctrl_warning_UpdateWarningStatusTrigByUpdateWarningStatus: start-on-event=Ctrl_warning_UpdateWarningStatus, operation=ppCtrlWarningStatus.UpdateWarningStatus
      operation invoked event OIE_pp_CtrlWarningGroupUpdate_Ctrl_warning_Warning_Group_updateTrigByWarning_Group_update: start-on-event=Ctrl_warning_Warning_Group_update, operation=pp_CtrlWarningGroupUpdate.Warning_Group_update
      port-api-options:
        enable-take-address=false, indirect-api=false, port=ppActiveWarningStatus
        enable-take-address=false, indirect-api=false, port=ppCtrlWarningExtdPayload
        enable-take-address=false, indirect-api=false, port=ppCtrlWarningLampStatus
        enable-take-address=false, indirect-api=false, port=ppCtrlWarningStatus
        enable-take-address=false, indirect-api=false, port=ppWarnDisplayPayload
        enable-take-address=false, indirect-api=false, port=ppWarnDisplayStatus
        enable-take-address=false, indirect-api=false, port=ppWarningActiveStatus
        enable-take-address=false, indirect-api=false, port=ppWarningDisplayedPayload
        enable-take-address=false, indirect-api=false, port=ppWarningDisplayedStatus
        enable-take-address=false, indirect-api=false, port=pp_CtrlWarningGroupUpdate
        enable-take-address=false, indirect-api=false, port=Ctrl_warning/pp_Init
        enable-take-address=false, indirect-api=false, port=Ctrl_warning/rpIgnSubstate
        enable-take-address=false, indirect-api=false, port=Ctrl_warning/rp_ClusterMode
      13 x runnable, all with can-be-invoked-concurrently=true:
        Ctrl_warning_GetActiveWarningStatus
        Ctrl_warning_GetWarningActiveStatus
        Ctrl_warning_GetWarningDisplayedPayload
        Ctrl_warning_GetWarningDisplayedStatus
        Ctrl_warning_Get_Red_MasterLamp_Status
        Ctrl_warning_Get_Yellow_MasterLamp_Status
        Ctrl_warning_Init
        Ctrl_warning_SetWarningDisplayedPayload
        Ctrl_warning_SetWarningDisplayedStatus
        Ctrl_warning_Task
          data-receive-point-by-arguments:
            access DRA_rpIgnSubstate_IgnitionSubstate: accessed-variable=rpIgnSubstate.IgnitionSubstate
            access DRA_rp_ClusterMode_WSSCurrentClusterMode: accessed-variable=rp_ClusterMode.WSSCurrentClusterMode
        Ctrl_warning_UpdateExtdPayload
        Ctrl_warning_UpdateWarningStatus
        Ctrl_warning_Warning_Group_update
  constant specification Ctrl_warningIgnitionSubstateValue0: value-spec=Ctrl_warningIgnitionSubstateValue0:0
  constant specification Ctrl_warningWSSCurrentClusterModeValue0: value-spec=Ctrl_warningWSSCurrentClusterModeValue0:0
  swc implementation IMPL_Ctrl_warning: programming-language=C, behavior=IB_Ctrl_warning
    code-descriptors:
      code CodeDescriptor
